VERSION ""

NS_ :

BS_:

BU_: FBD_HL IPB_App1 FBD_HM FBD_HR FBD_Miko FBD_MM FBD_Trunk FBD_VL FBD_VM FBD_VR Diagnosetool_CAN_FD_IPB_41

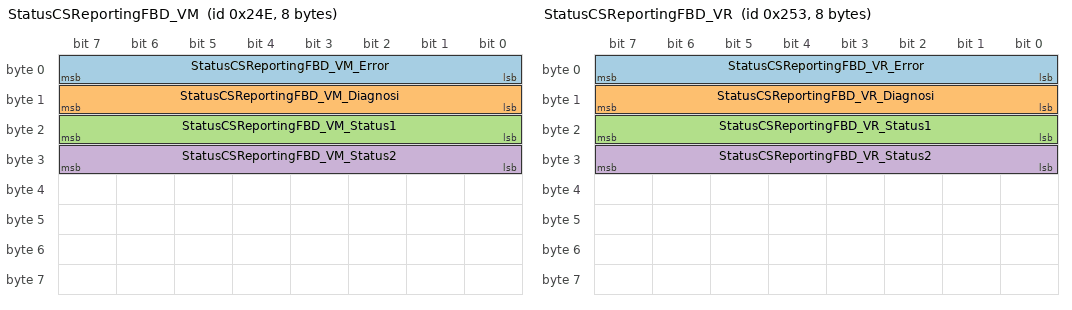
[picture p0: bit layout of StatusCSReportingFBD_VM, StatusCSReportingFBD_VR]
BO_ 590 StatusCSReportingFBD_VM: 8 FBD_VM
 SG_ StatusCSReportingFBD_VM_Error : 0|8@1+ (1,0) [0|0] "" IPB_App1
 SG_ StatusCSReportingFBD_VM_Diagnosi : 8|8@1+ (1.0,0) [0|252] "" IPB_App1
 SG_ StatusCSReportingFBD_VM_Status1 : 16|8@1+ (1.0,0) [0|252] "" IPB_App1
 SG_ StatusCSReportingFBD_VM_Status2 : 24|8@1+ (1.0,0) [0|252] "" IPB_App1

BO_ 595 StatusCSReportingFBD_VR: 8 FBD_VR
 SG_ StatusCSReportingFBD_VR_Error : 0|8@1+ (1,0) [0|0] "" IPB_App1
 SG_ StatusCSReportingFBD_VR_Diagnosi : 8|8@1+ (1.0,0) [0|252] "" IPB_App1
 SG_ StatusCSReportingFBD_VR_Status1 : 16|8@1+ (1.0,0) [0|252] "" IPB_App1
 SG_ StatusCSReportingFBD_VR_Status2 : 24|8@1+ (1.0,0) [0|252] "" IPB_App1

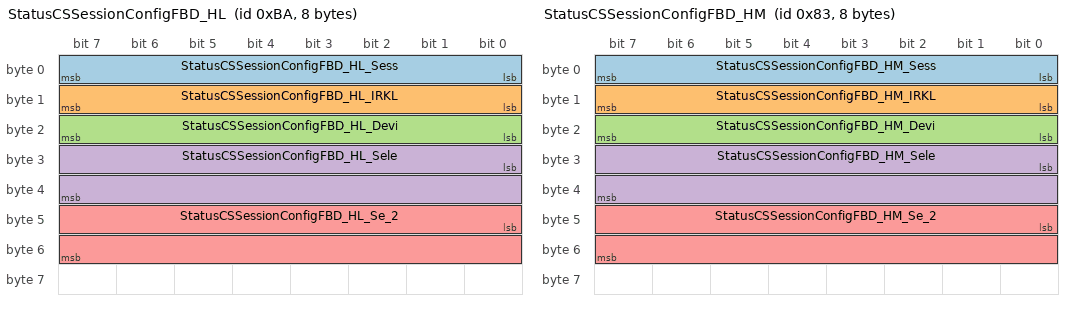
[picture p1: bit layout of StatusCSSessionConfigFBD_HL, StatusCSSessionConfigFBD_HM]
BO_ 186 StatusCSSessionConfigFBD_HL: 8 FBD_HL
 SG_ StatusCSSessionConfigFBD_HL_Sess : 0|8@1+ (1.0,0) [0|252] "" IPB_App1
 SG_ StatusCSSessionConfigFBD_HL_IRKL : 8|8@1+ (1.0,0) [0|252] "" IPB_App1
 SG_ StatusCSSessionConfigFBD_HL_Devi : 16|8@1+ (1.0,0) [0|252] "" IPB_App1
 SG_ StatusCSSessionConfigFBD_HL_Sele : 24|16@1+ (0.625,0) [0|40900] "ms" IPB_App1
 SG_ StatusCSSessionConfigFBD_HL_Se_2 : 40|16@1+ (1.0,0) [0|65532] "" IPB_App1

BO_ 131 StatusCSSessionConfigFBD_HM: 8 FBD_HM
 SG_ StatusCSSessionConfigFBD_HM_Sess : 0|8@1+ (1.0,0) [0|252] "" IPB_App1
 SG_ StatusCSSessionConfigFBD_HM_IRKL : 8|8@1+ (1.0,0) [0|252] "" IPB_App1
 SG_ StatusCSSessionConfigFBD_HM_Devi : 16|8@1+ (1.0,0) [0|252] "" IPB_App1
 SG_ StatusCSSessionConfigFBD_HM_Sele : 24|16@1+ (0.625,0) [0|40900] "ms" IPB_App1
 SG_ StatusCSSessionConfigFBD_HM_Se_2 : 40|16@1+ (1.0,0) [0|65532] "" IPB_App1

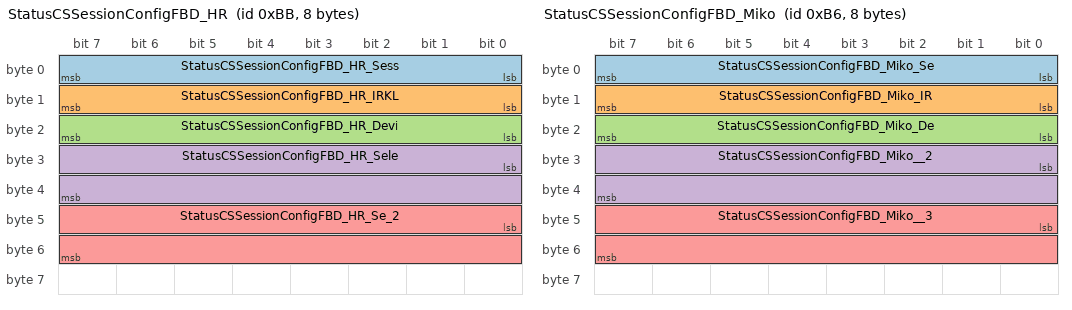
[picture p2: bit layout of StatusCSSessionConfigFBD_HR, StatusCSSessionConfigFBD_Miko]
BO_ 187 StatusCSSessionConfigFBD_HR: 8 FBD_HR
 SG_ StatusCSSessionConfigFBD_HR_Sess : 0|8@1+ (1.0,0) [0|252] "" IPB_App1
 SG_ StatusCSSessionConfigFBD_HR_IRKL : 8|8@1+ (1.0,0) [0|252] "" IPB_App1
 SG_ StatusCSSessionConfigFBD_HR_Devi : 16|8@1+ (1.0,0) [0|252] "" IPB_App1
 SG_ StatusCSSessionConfigFBD_HR_Sele : 24|16@1+ (0.625,0) [0|40900] "ms" IPB_App1
 SG_ StatusCSSessionConfigFBD_HR_Se_2 : 40|16@1+ (1.0,0) [0|65532] "" IPB_App1

BO_ 182 StatusCSSessionConfigFBD_Miko: 8 FBD_Miko
 SG_ StatusCSSessionConfigFBD_Miko_Se : 0|8@1+ (1.0,0) [0|252] "" IPB_App1
 SG_ StatusCSSessionConfigFBD_Miko_IR : 8|8@1+ (1.0,0) [0|252] "" IPB_App1
 SG_ StatusCSSessionConfigFBD_Miko_De : 16|8@1+ (1.0,0) [0|252] "" IPB_App1
 SG_ StatusCSSessionConfigFBD_Miko__2 : 24|16@1+ (0.625,0) [0|40900] "ms" IPB_App1
 SG_ StatusCSSessionConfigFBD_Miko__3 : 40|16@1+ (1.0,0) [0|65532] "" IPB_App1

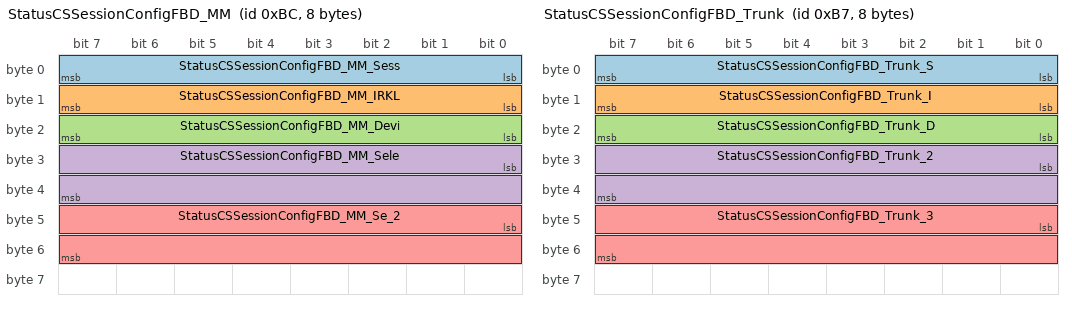
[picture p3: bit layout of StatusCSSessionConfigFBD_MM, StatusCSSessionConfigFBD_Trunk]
BO_ 188 StatusCSSessionConfigFBD_MM: 8 FBD_MM
 SG_ StatusCSSessionConfigFBD_MM_Sess : 0|8@1+ (1.0,0) [0|252] "" IPB_App1
 SG_ StatusCSSessionConfigFBD_MM_IRKL : 8|8@1+ (1.0,0) [0|252] "" IPB_App1
 SG_ StatusCSSessionConfigFBD_MM_Devi : 16|8@1+ (1.0,0) [0|252] "" IPB_App1
 SG_ StatusCSSessionConfigFBD_MM_Sele : 24|16@1+ (0.625,0) [0|40900] "ms" IPB_App1
 SG_ StatusCSSessionConfigFBD_MM_Se_2 : 40|16@1+ (1.0,0) [0|65532] "" IPB_App1

BO_ 183 StatusCSSessionConfigFBD_Trunk: 8 FBD_Trunk
 SG_ StatusCSSessionConfigFBD_Trunk_S : 0|8@1+ (1.0,0) [0|252] "" IPB_App1
 SG_ StatusCSSessionConfigFBD_Trunk_I : 8|8@1+ (1.0,0) [0|252] "" IPB_App1
 SG_ StatusCSSessionConfigFBD_Trunk_D : 16|8@1+ (1.0,0) [0|252] "" IPB_App1
 SG_ StatusCSSessionConfigFBD_Trunk_2 : 24|16@1+ (0.625,0) [0|40900] "ms" IPB_App1
 SG_ StatusCSSessionConfigFBD_Trunk_3 : 40|16@1+ (1.0,0) [0|65532] "" IPB_App1

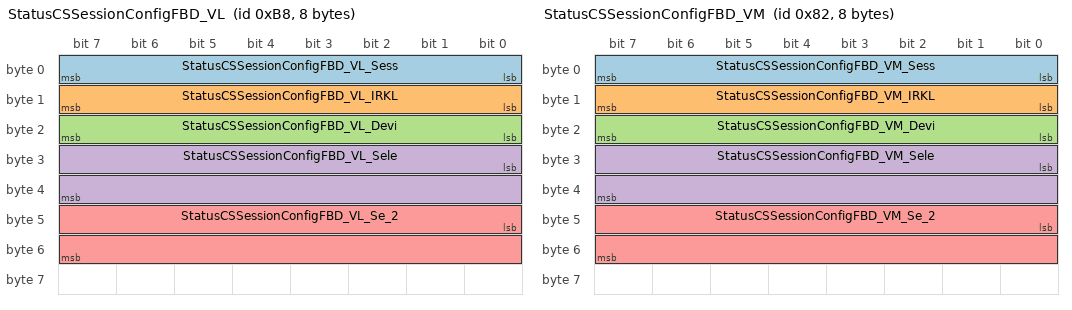
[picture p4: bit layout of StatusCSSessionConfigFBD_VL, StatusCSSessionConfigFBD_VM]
BO_ 184 StatusCSSessionConfigFBD_VL: 8 FBD_VL
 SG_ StatusCSSessionConfigFBD_VL_Sess : 0|8@1+ (1.0,0) [0|252] "" IPB_App1
 SG_ StatusCSSessionConfigFBD_VL_IRKL : 8|8@1+ (1.0,0) [0|252] "" IPB_App1
 SG_ StatusCSSessionConfigFBD_VL_Devi : 16|8@1+ (1.0,0) [0|252] "" IPB_App1
 SG_ StatusCSSessionConfigFBD_VL_Sele : 24|16@1+ (0.625,0) [0|40900] "ms" IPB_App1
 SG_ StatusCSSessionConfigFBD_VL_Se_2 : 40|16@1+ (1.0,0) [0|65532] "" IPB_App1

BO_ 130 StatusCSSessionConfigFBD_VM: 8 FBD_VM
 SG_ StatusCSSessionConfigFBD_VM_Sess : 0|8@1+ (1.0,0) [0|252] "" IPB_App1
 SG_ StatusCSSessionConfigFBD_VM_IRKL : 8|8@1+ (1.0,0) [0|252] "" IPB_App1
 SG_ StatusCSSessionConfigFBD_VM_Devi : 16|8@1+ (1.0,0) [0|252] "" IPB_App1
 SG_ StatusCSSessionConfigFBD_VM_Sele : 24|16@1+ (0.625,0) [0|40900] "ms" IPB_App1
 SG_ StatusCSSessionConfigFBD_VM_Se_2 : 40|16@1+ (1.0,0) [0|65532] "" IPB_App1

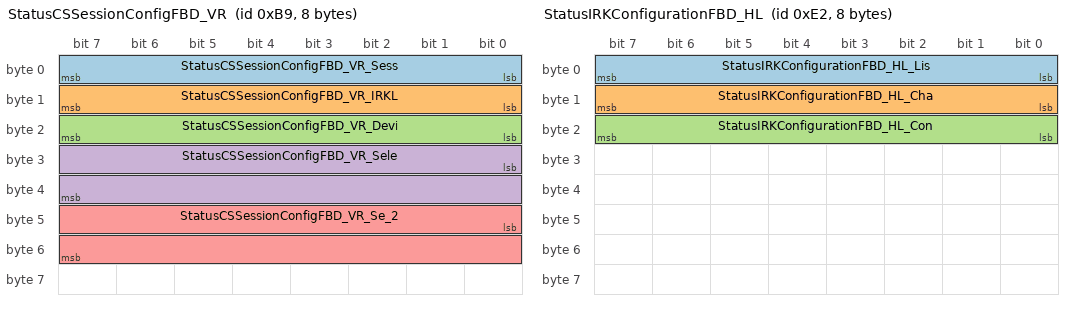
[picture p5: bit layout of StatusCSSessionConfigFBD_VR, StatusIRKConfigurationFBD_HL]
BO_ 185 StatusCSSessionConfigFBD_VR: 8 FBD_VR
 SG_ StatusCSSessionConfigFBD_VR_Sess : 0|8@1+ (1.0,0) [0|252] "" IPB_App1
 SG_ StatusCSSessionConfigFBD_VR_IRKL : 8|8@1+ (1.0,0) [0|252] "" IPB_App1
 SG_ StatusCSSessionConfigFBD_VR_Devi : 16|8@1+ (1.0,0) [0|252] "" IPB_App1
 SG_ StatusCSSessionConfigFBD_VR_Sele : 24|16@1+ (0.625,0) [0|40900] "ms" IPB_App1
 SG_ StatusCSSessionConfigFBD_VR_Se_2 : 40|16@1+ (1.0,0) [0|65532] "" IPB_App1

BO_ 646 StatusDiagnosticFBD_HL: 32 FBD_HL
 SG_ StatusDiagnosticFBD_HL_BMWPartNu : 0|8@1+ (1.0,0) [0|255] "" IPB_App1
 SG_ StatusDiagnosticFBD_HL_BMWPart_2 : 8|8@1+ (1.0,0) [0|255] "" IPB_App1
 SG_ StatusDiagnosticFBD_HL_BMWPart_3 : 16|8@1+ (1.0,0) [0|255] "" IPB_App1
 SG_ StatusDiagnosticFBD_HL_BMWPart_4 : 24|8@1+ (1.0,0) [0|255] "" IPB_App1
 SG_ StatusDiagnosticFBD_HL_BMWPart_5 : 32|8@1+ (1.0,0) [0|255] "" IPB_App1
 SG_ StatusDiagnosticFBD_HL_BMWPart_6 : 40|8@1+ (1.0,0) [0|255] "" IPB_App1
 SG_ StatusDiagnosticFBD_HL_BMWPart_7 : 48|8@1+ (1.0,0) [0|255] "" IPB_App1
 SG_ StatusDiagnosticFBD_HL_BMWPart_8 : 56|8@1+ (1.0,0) [0|255] "" IPB_App1
 SG_ StatusDiagnosticFBD_HL_HWELMain : 64|8@1+ (1.0,0) [0|252] "" IPB_App1
 SG_ StatusDiagnosticFBD_HL_HWELMinor : 72|8@1+ (1.0,0) [0|252] "" IPB_App1
 SG_ StatusDiagnosticFBD_HL_HWELPatch : 80|8@1+ (1.0,0) [0|252] "" IPB_App1
 SG_ StatusDiagnosticFBD_HL_BLESWFKMa : 88|8@1+ (1.0,0) [0|252] "" IPB_App1
 SG_ StatusDiagnosticFBD_HL_BLESWFKMi : 96|8@1+ (1.0,0) [0|252] "" IPB_App1
 SG_ StatusDiagnosticFBD_HL_BLESWFKPa : 104|8@1+ (1.0,0) [0|252] "" IPB_App1
 SG_ StatusDiagnosticFBD_HL_UWBSWFKMa : 112|8@1+ (1.0,0) [0|252] "" IPB_App1
 SG_ StatusDiagnosticFBD_HL_UWBSWFKMi : 120|8@1+ (1.0,0) [0|252] "" IPB_App1
 SG_ StatusDiagnosticFBD_HL_UWBSWFKPa : 128|8@1+ (1.0,0) [0|252] "" IPB_App1
 SG_ StatusDiagnosticFBD_HL_Bootloade : 136|8@1+ (1.0,0) [0|252] "" IPB_App1
 SG_ StatusDiagnosticFBD_HL_Bootloa_2 : 144|8@1+ (1.0,0) [0|252] "" IPB_App1
 SG_ StatusDiagnosticFBD_HL_Bootloa_3 : 152|8@1+ (1.0,0) [0|252] "" IPB_App1
 SG_ StatusDiagnosticFBD_HL_Productio : 160|64@1+ (1.0,0) [0|18446744073709551612] "" IPB_App1
 SG_ StatusDiagnosticFBD_HL_SerialNum : 224|32@1+ (1.0,0) [0|4294967292] "" IPB_App1

BO_ 641 StatusDiagnosticFBD_HM: 32 FBD_HM
 SG_ StatusDiagnosticFBD_HM_BMWPartNu : 0|8@1+ (1.0,0) [0|255] "" IPB_App1
 SG_ StatusDiagnosticFBD_HM_BMWPart_2 : 8|8@1+ (1.0,0) [0|255] "" IPB_App1
 SG_ StatusDiagnosticFBD_HM_BMWPart_3 : 16|8@1+ (1.0,0) [0|255] "" IPB_App1
 SG_ StatusDiagnosticFBD_HM_BMWPart_4 : 24|8@1+ (1.0,0) [0|255] "" IPB_App1
 SG_ StatusDiagnosticFBD_HM_BMWPart_5 : 32|8@1+ (1.0,0) [0|255] "" IPB_App1
 SG_ StatusDiagnosticFBD_HM_BMWPart_6 : 40|8@1+ (1.0,0) [0|255] "" IPB_App1
 SG_ StatusDiagnosticFBD_HM_BMWPart_7 : 48|8@1+ (1.0,0) [0|255] "" IPB_App1
 SG_ StatusDiagnosticFBD_HM_BMWPart_8 : 56|8@1+ (1.0,0) [0|255] "" IPB_App1
 SG_ StatusDiagnosticFBD_HM_HWELMain : 64|8@1+ (1.0,0) [0|252] "" IPB_App1
 SG_ StatusDiagnosticFBD_HM_HWELMinor : 72|8@1+ (1.0,0) [0|252] "" IPB_App1
 SG_ StatusDiagnosticFBD_HM_HWELPatch : 80|8@1+ (1.0,0) [0|252] "" IPB_App1
 SG_ StatusDiagnosticFBD_HM_BLESWFKMa : 88|8@1+ (1.0,0) [0|252] "" IPB_App1
 SG_ StatusDiagnosticFBD_HM_BLESWFKMi : 96|8@1+ (1.0,0) [0|252] "" IPB_App1
 SG_ StatusDiagnosticFBD_HM_BLESWFKPa : 104|8@1+ (1.0,0) [0|252] "" IPB_App1
 SG_ StatusDiagnosticFBD_HM_UWBSWFKMa : 112|8@1+ (1.0,0) [0|252] "" IPB_App1
 SG_ StatusDiagnosticFBD_HM_UWBSWFKMi : 120|8@1+ (1.0,0) [0|252] "" IPB_App1
 SG_ StatusDiagnosticFBD_HM_UWBSWFKPa : 128|8@1+ (1.0,0) [0|252] "" IPB_App1
 SG_ StatusDiagnosticFBD_HM_Bootloade : 136|8@1+ (1.0,0) [0|252] "" IPB_App1
 SG_ StatusDiagnosticFBD_HM_Bootloa_2 : 144|8@1+ (1.0,0) [0|252] "" IPB_App1
 SG_ StatusDiagnosticFBD_HM_Bootloa_3 : 152|8@1+ (1.0,0) [0|252] "" IPB_App1
 SG_ StatusDiagnosticFBD_HM_Productio : 160|64@1+ (1.0,0) [0|18446744073709551612] "" IPB_App1
 SG_ StatusDiagnosticFBD_HM_SerialNum : 224|32@1+ (1.0,0) [0|4294967292] "" IPB_App1

BO_ 647 StatusDiagnosticFBD_HR: 32 FBD_HR
 SG_ StatusDiagnosticFBD_HR_BMWPartNu : 0|8@1+ (1.0,0) [0|255] "" IPB_App1
 SG_ StatusDiagnosticFBD_HR_BMWPart_2 : 8|8@1+ (1.0,0) [0|255] "" IPB_App1
 SG_ StatusDiagnosticFBD_HR_BMWPart_3 : 16|8@1+ (1.0,0) [0|255] "" IPB_App1
 SG_ StatusDiagnosticFBD_HR_BMWPart_4 : 24|8@1+ (1.0,0) [0|255] "" IPB_App1
 SG_ StatusDiagnosticFBD_HR_BMWPart_5 : 32|8@1+ (1.0,0) [0|255] "" IPB_App1
 SG_ StatusDiagnosticFBD_HR_BMWPart_6 : 40|8@1+ (1.0,0) [0|255] "" IPB_App1
 SG_ StatusDiagnosticFBD_HR_BMWPart_7 : 48|8@1+ (1.0,0) [0|255] "" IPB_App1
 SG_ StatusDiagnosticFBD_HR_BMWPart_8 : 56|8@1+ (1.0,0) [0|255] "" IPB_App1
 SG_ StatusDiagnosticFBD_HR_HWELMain : 64|8@1+ (1.0,0) [0|252] "" IPB_App1
 SG_ StatusDiagnosticFBD_HR_HWELMinor : 72|8@1+ (1.0,0) [0|252] "" IPB_App1
 SG_ StatusDiagnosticFBD_HR_HWELPatch : 80|8@1+ (1.0,0) [0|252] "" IPB_App1
 SG_ StatusDiagnosticFBD_HR_BLESWFKMa : 88|8@1+ (1.0,0) [0|252] "" IPB_App1
 SG_ StatusDiagnosticFBD_HR_BLESWFKMi : 96|8@1+ (1.0,0) [0|252] "" IPB_App1
 SG_ StatusDiagnosticFBD_HR_BLESWFKPa : 104|8@1+ (1.0,0) [0|252] "" IPB_App1
 SG_ StatusDiagnosticFBD_HR_UWBSWFKMa : 112|8@1+ (1.0,0) [0|252] "" IPB_App1
 SG_ StatusDiagnosticFBD_HR_UWBSWFKMi : 120|8@1+ (1.0,0) [0|252] "" IPB_App1
 SG_ StatusDiagnosticFBD_HR_UWBSWFKPa : 128|8@1+ (1.0,0) [0|252] "" IPB_App1
 SG_ StatusDiagnosticFBD_HR_Bootloade : 136|8@1+ (1.0,0) [0|252] "" IPB_App1
 SG_ StatusDiagnosticFBD_HR_Bootloa_2 : 144|8@1+ (1.0,0) [0|252] "" IPB_App1
 SG_ StatusDiagnosticFBD_HR_Bootloa_3 : 152|8@1+ (1.0,0) [0|252] "" IPB_App1
 SG_ StatusDiagnosticFBD_HR_Productio : 160|64@1+ (1.0,0) [0|18446744073709551612] "" IPB_App1
 SG_ StatusDiagnosticFBD_HR_SerialNum : 224|32@1+ (1.0,0) [0|4294967292] "" IPB_App1

BO_ 642 StatusDiagnosticFBD_Miko: 32 FBD_Miko
 SG_ StatusDiagnosticFBD_Miko_BMWPart : 0|8@1+ (1.0,0) [0|255] "" IPB_App1
 SG_ StatusDiagnosticFBD_Miko_BMWPa_2 : 8|8@1+ (1.0,0) [0|255] "" IPB_App1
 SG_ StatusDiagnosticFBD_Miko_BMWPa_3 : 16|8@1+ (1.0,0) [0|255] "" IPB_App1
 SG_ StatusDiagnosticFBD_Miko_BMWPa_4 : 24|8@1+ (1.0,0) [0|255] "" IPB_App1
 SG_ StatusDiagnosticFBD_Miko_BMWPa_5 : 32|8@1+ (1.0,0) [0|255] "" IPB_App1
 SG_ StatusDiagnosticFBD_Miko_BMWPa_6 : 40|8@1+ (1.0,0) [0|255] "" IPB_App1
 SG_ StatusDiagnosticFBD_Miko_BMWPa_7 : 48|8@1+ (1.0,0) [0|255] "" IPB_App1
 SG_ StatusDiagnosticFBD_Miko_BMWPa_8 : 56|8@1+ (1.0,0) [0|255] "" IPB_App1
 SG_ StatusDiagnosticFBD_Miko_HWELMai : 64|8@1+ (1.0,0) [0|252] "" IPB_App1
 SG_ StatusDiagnosticFBD_Miko_HWELMin : 72|8@1+ (1.0,0) [0|252] "" IPB_App1
 SG_ StatusDiagnosticFBD_Miko_HWELPat : 80|8@1+ (1.0,0) [0|252] "" IPB_App1
 SG_ StatusDiagnosticFBD_Miko_BLESWFK : 88|8@1+ (1.0,0) [0|252] "" IPB_App1
 SG_ StatusDiagnosticFBD_Miko_BLESW_2 : 96|8@1+ (1.0,0) [0|252] "" IPB_App1
 SG_ StatusDiagnosticFBD_Miko_BLESW_3 : 104|8@1+ (1.0,0) [0|252] "" IPB_App1
 SG_ StatusDiagnosticFBD_Miko_UWBSWFK : 112|8@1+ (1.0,0) [0|252] "" IPB_App1
 SG_ StatusDiagnosticFBD_Miko_UWBSW_2 : 120|8@1+ (1.0,0) [0|252] "" IPB_App1
 SG_ StatusDiagnosticFBD_Miko_UWBSW_3 : 128|8@1+ (1.0,0) [0|252] "" IPB_App1
 SG_ StatusDiagnosticFBD_Miko_Bootloa : 136|8@1+ (1.0,0) [0|252] "" IPB_App1
 SG_ StatusDiagnosticFBD_Miko_Bootl_2 : 144|8@1+ (1.0,0) [0|252] "" IPB_App1
 SG_ StatusDiagnosticFBD_Miko_Bootl_3 : 152|8@1+ (1.0,0) [0|252] "" IPB_App1
 SG_ StatusDiagnosticFBD_Miko_Product : 160|64@1+ (1.0,0) [0|18446744073709551612] "" IPB_App1
 SG_ StatusDiagnosticFBD_Miko_SerialN : 224|32@1+ (1.0,0) [0|4294967292] "" IPB_App1

BO_ 864 StatusDiagnosticFBD_MM: 32 FBD_MM
 SG_ StatusDiagnosticFBD_MM_BMWPartNu : 0|8@1+ (1.0,0) [0|255] "" IPB_App1
 SG_ StatusDiagnosticFBD_MM_BMWPart_2 : 8|8@1+ (1.0,0) [0|255] "" IPB_App1
 SG_ StatusDiagnosticFBD_MM_BMWPart_3 : 16|8@1+ (1.0,0) [0|255] "" IPB_App1
 SG_ StatusDiagnosticFBD_MM_BMWPart_4 : 24|8@1+ (1.0,0) [0|255] "" IPB_App1
 SG_ StatusDiagnosticFBD_MM_BMWPart_5 : 32|8@1+ (1.0,0) [0|255] "" IPB_App1
 SG_ StatusDiagnosticFBD_MM_BMWPart_6 : 40|8@1+ (1.0,0) [0|255] "" IPB_App1
 SG_ StatusDiagnosticFBD_MM_BMWPart_7 : 48|8@1+ (1.0,0) [0|255] "" IPB_App1
 SG_ StatusDiagnosticFBD_MM_BMWPart_8 : 56|8@1+ (1.0,0) [0|255] "" IPB_App1
 SG_ StatusDiagnosticFBD_MM_HWELMain : 64|8@1+ (1.0,0) [0|252] "" IPB_App1
 SG_ StatusDiagnosticFBD_MM_HWELMinor : 72|8@1+ (1.0,0) [0|252] "" IPB_App1
 SG_ StatusDiagnosticFBD_MM_HWELPatch : 80|8@1+ (1.0,0) [0|252] "" IPB_App1
 SG_ StatusDiagnosticFBD_MM_BLESWFKMa : 88|8@1+ (1.0,0) [0|252] "" IPB_App1
 SG_ StatusDiagnosticFBD_MM_BLESWFKMi : 96|8@1+ (1.0,0) [0|252] "" IPB_App1
 SG_ StatusDiagnosticFBD_MM_BLESWFKPa : 104|8@1+ (1.0,0) [0|252] "" IPB_App1
 SG_ StatusDiagnosticFBD_MM_UWBSWFKMa : 112|8@1+ (1.0,0) [0|252] "" IPB_App1
 SG_ StatusDiagnosticFBD_MM_UWBSWFKMi : 120|8@1+ (1.0,0) [0|252] "" IPB_App1
 SG_ StatusDiagnosticFBD_MM_UWBSWFKPa : 128|8@1+ (1.0,0) [0|252] "" IPB_App1
 SG_ StatusDiagnosticFBD_MM_Bootloade : 136|8@1+ (1.0,0) [0|252] "" IPB_App1
 SG_ StatusDiagnosticFBD_MM_Bootloa_2 : 144|8@1+ (1.0,0) [0|252] "" IPB_App1
 SG_ StatusDiagnosticFBD_MM_Bootloa_3 : 152|8@1+ (1.0,0) [0|252] "" IPB_App1
 SG_ StatusDiagnosticFBD_MM_Productio : 160|64@1+ (1.0,0) [0|18446744073709551612] "" IPB_App1
 SG_ StatusDiagnosticFBD_MM_SerialNum : 224|32@1+ (1.0,0) [0|4294967292] "" IPB_App1

BO_ 643 StatusDiagnosticFBD_Trunk: 32 FBD_Trunk
 SG_ StatusDiagnosticFBD_Trunk_BMWPar : 0|8@1+ (1.0,0) [0|255] "" IPB_App1
 SG_ StatusDiagnosticFBD_Trunk_BMWP_2 : 8|8@1+ (1.0,0) [0|255] "" IPB_App1
 SG_ StatusDiagnosticFBD_Trunk_BMWP_3 : 16|8@1+ (1.0,0) [0|255] "" IPB_App1
 SG_ StatusDiagnosticFBD_Trunk_BMWP_4 : 24|8@1+ (1.0,0) [0|255] "" IPB_App1
 SG_ StatusDiagnosticFBD_Trunk_BMWP_5 : 32|8@1+ (1.0,0) [0|255] "" IPB_App1
 SG_ StatusDiagnosticFBD_Trunk_BMWP_6 : 40|8@1+ (1.0,0) [0|255] "" IPB_App1
 SG_ StatusDiagnosticFBD_Trunk_BMWP_7 : 48|8@1+ (1.0,0) [0|255] "" IPB_App1
 SG_ StatusDiagnosticFBD_Trunk_BMWP_8 : 56|8@1+ (1.0,0) [0|255] "" IPB_App1
 SG_ StatusDiagnosticFBD_Trunk_HWELMa : 64|8@1+ (1.0,0) [0|252] "" IPB_App1
 SG_ StatusDiagnosticFBD_Trunk_HWELMi : 72|8@1+ (1.0,0) [0|252] "" IPB_App1
 SG_ StatusDiagnosticFBD_Trunk_HWELPa : 80|8@1+ (1.0,0) [0|252] "" IPB_App1
 SG_ StatusDiagnosticFBD_Trunk_BLESWF : 88|8@1+ (1.0,0) [0|252] "" IPB_App1
 SG_ StatusDiagnosticFBD_Trunk_BLES_2 : 96|8@1+ (1.0,0) [0|252] "" IPB_App1
 SG_ StatusDiagnosticFBD_Trunk_BLES_3 : 104|8@1+ (1.0,0) [0|252] "" IPB_App1
 SG_ StatusDiagnosticFBD_Trunk_UWBSWF : 112|8@1+ (1.0,0) [0|252] "" IPB_App1
 SG_ StatusDiagnosticFBD_Trunk_UWBS_2 : 120|8@1+ (1.0,0) [0|252] "" IPB_App1
 SG_ StatusDiagnosticFBD_Trunk_UWBS_3 : 128|8@1+ (1.0,0) [0|252] "" IPB_App1
 SG_ StatusDiagnosticFBD_Trunk_Bootlo : 136|8@1+ (1.0,0) [0|252] "" IPB_App1
 SG_ StatusDiagnosticFBD_Trunk_Boot_2 : 144|8@1+ (1.0,0) [0|252] "" IPB_App1
 SG_ StatusDiagnosticFBD_Trunk_Boot_3 : 152|8@1+ (1.0,0) [0|252] "" IPB_App1
 SG_ StatusDiagnosticFBD_Trunk_Produc : 160|64@1+ (1.0,0) [0|18446744073709551612] "" IPB_App1
 SG_ StatusDiagnosticFBD_Trunk_Serial : 224|32@1+ (1.0,0) [0|4294967292] "" IPB_App1

BO_ 644 StatusDiagnosticFBD_VL: 32 FBD_VL
 SG_ StatusDiagnosticFBD_VL_BMWPartNu : 0|8@1+ (1.0,0) [0|255] "" IPB_App1
 SG_ StatusDiagnosticFBD_VL_BMWPart_2 : 8|8@1+ (1.0,0) [0|255] "" IPB_App1
 SG_ StatusDiagnosticFBD_VL_BMWPart_3 : 16|8@1+ (1.0,0) [0|255] "" IPB_App1
 SG_ StatusDiagnosticFBD_VL_BMWPart_4 : 24|8@1+ (1.0,0) [0|255] "" IPB_App1
 SG_ StatusDiagnosticFBD_VL_BMWPart_5 : 32|8@1+ (1.0,0) [0|255] "" IPB_App1
 SG_ StatusDiagnosticFBD_VL_BMWPart_6 : 40|8@1+ (1.0,0) [0|255] "" IPB_App1
 SG_ StatusDiagnosticFBD_VL_BMWPart_7 : 48|8@1+ (1.0,0) [0|255] "" IPB_App1
 SG_ StatusDiagnosticFBD_VL_BMWPart_8 : 56|8@1+ (1.0,0) [0|255] "" IPB_App1
 SG_ StatusDiagnosticFBD_VL_HWELMain : 64|8@1+ (1.0,0) [0|252] "" IPB_App1
 SG_ StatusDiagnosticFBD_VL_HWELMinor : 72|8@1+ (1.0,0) [0|252] "" IPB_App1
 SG_ StatusDiagnosticFBD_VL_HWELPatch : 80|8@1+ (1.0,0) [0|252] "" IPB_App1
 SG_ StatusDiagnosticFBD_VL_BLESWFKMa : 88|8@1+ (1.0,0) [0|252] "" IPB_App1
 SG_ StatusDiagnosticFBD_VL_BLESWFKMi : 96|8@1+ (1.0,0) [0|252] "" IPB_App1
 SG_ StatusDiagnosticFBD_VL_BLESWFKPa : 104|8@1+ (1.0,0) [0|252] "" IPB_App1
 SG_ StatusDiagnosticFBD_VL_UWBSWFKMa : 112|8@1+ (1.0,0) [0|252] "" IPB_App1
 SG_ StatusDiagnosticFBD_VL_UWBSWFKMi : 120|8@1+ (1.0,0) [0|252] "" IPB_App1
 SG_ StatusDiagnosticFBD_VL_UWBSWFKPa : 128|8@1+ (1.0,0) [0|252] "" IPB_App1
 SG_ StatusDiagnosticFBD_VL_Bootloade : 136|8@1+ (1.0,0) [0|252] "" IPB_App1
 SG_ StatusDiagnosticFBD_VL_Bootloa_2 : 144|8@1+ (1.0,0) [0|252] "" IPB_App1
 SG_ StatusDiagnosticFBD_VL_Bootloa_3 : 152|8@1+ (1.0,0) [0|252] "" IPB_App1
 SG_ StatusDiagnosticFBD_VL_Productio : 160|64@1+ (1.0,0) [0|18446744073709551612] "" IPB_App1
 SG_ StatusDiagnosticFBD_VL_SerialNum : 224|32@1+ (1.0,0) [0|4294967292] "" IPB_App1

BO_ 640 StatusDiagnosticFBD_VM: 32 FBD_VM
 SG_ StatusDiagnosticFBD_VM_BMWPartNu : 0|8@1+ (1.0,0) [0|255] "" IPB_App1
 SG_ StatusDiagnosticFBD_VM_BMWPart_2 : 8|8@1+ (1.0,0) [0|255] "" IPB_App1
 SG_ StatusDiagnosticFBD_VM_BMWPart_3 : 16|8@1+ (1.0,0) [0|255] "" IPB_App1
 SG_ StatusDiagnosticFBD_VM_BMWPart_4 : 24|8@1+ (1.0,0) [0|255] "" IPB_App1
 SG_ StatusDiagnosticFBD_VM_BMWPart_5 : 32|8@1+ (1.0,0) [0|255] "" IPB_App1
 SG_ StatusDiagnosticFBD_VM_BMWPart_6 : 40|8@1+ (1.0,0) [0|255] "" IPB_App1
 SG_ StatusDiagnosticFBD_VM_BMWPart_7 : 48|8@1+ (1.0,0) [0|255] "" IPB_App1
 SG_ StatusDiagnosticFBD_VM_BMWPart_8 : 56|8@1+ (1.0,0) [0|255] "" IPB_App1
 SG_ StatusDiagnosticFBD_VM_HWELMain : 64|8@1+ (1.0,0) [0|252] "" IPB_App1
 SG_ StatusDiagnosticFBD_VM_HWELMinor : 72|8@1+ (1.0,0) [0|252] "" IPB_App1
 SG_ StatusDiagnosticFBD_VM_HWELPatch : 80|8@1+ (1.0,0) [0|252] "" IPB_App1
 SG_ StatusDiagnosticFBD_VM_BLESWFKMa : 88|8@1+ (1.0,0) [0|252] "" IPB_App1
 SG_ StatusDiagnosticFBD_VM_BLESWFKMi : 96|8@1+ (1.0,0) [0|252] "" IPB_App1
 SG_ StatusDiagnosticFBD_VM_BLESWFKPa : 104|8@1+ (1.0,0) [0|252] "" IPB_App1
 SG_ StatusDiagnosticFBD_VM_UWBSWFKMa : 112|8@1+ (1.0,0) [0|252] "" IPB_App1
 SG_ StatusDiagnosticFBD_VM_UWBSWFKMi : 120|8@1+ (1.0,0) [0|252] "" IPB_App1
 SG_ StatusDiagnosticFBD_VM_UWBSWFKPa : 128|8@1+ (1.0,0) [0|252] "" IPB_App1
 SG_ StatusDiagnosticFBD_VM_Bootloade : 136|8@1+ (1.0,0) [0|252] "" IPB_App1
 SG_ StatusDiagnosticFBD_VM_Bootloa_2 : 144|8@1+ (1.0,0) [0|252] "" IPB_App1
 SG_ StatusDiagnosticFBD_VM_Bootloa_3 : 152|8@1+ (1.0,0) [0|252] "" IPB_App1
 SG_ StatusDiagnosticFBD_VM_Productio : 160|64@1+ (1.0,0) [0|18446744073709551612] "" IPB_App1
 SG_ StatusDiagnosticFBD_VM_SerialNum : 224|32@1+ (1.0,0) [0|4294967292] "" IPB_App1

BO_ 645 StatusDiagnosticFBD_VR: 32 FBD_VR
 SG_ StatusDiagnosticFBD_VR_BMWPartNu : 0|8@1+ (1.0,0) [0|255] "" IPB_App1
 SG_ StatusDiagnosticFBD_VR_BMWPart_2 : 8|8@1+ (1.0,0) [0|255] "" IPB_App1
 SG_ StatusDiagnosticFBD_VR_BMWPart_3 : 16|8@1+ (1.0,0) [0|255] "" IPB_App1
 SG_ StatusDiagnosticFBD_VR_BMWPart_4 : 24|8@1+ (1.0,0) [0|255] "" IPB_App1
 SG_ StatusDiagnosticFBD_VR_BMWPart_5 : 32|8@1+ (1.0,0) [0|255] "" IPB_App1
 SG_ StatusDiagnosticFBD_VR_BMWPart_6 : 40|8@1+ (1.0,0) [0|255] "" IPB_App1
 SG_ StatusDiagnosticFBD_VR_BMWPart_7 : 48|8@1+ (1.0,0) [0|255] "" IPB_App1
 SG_ StatusDiagnosticFBD_VR_BMWPart_8 : 56|8@1+ (1.0,0) [0|255] "" IPB_App1
 SG_ StatusDiagnosticFBD_VR_HWELMain : 64|8@1+ (1.0,0) [0|252] "" IPB_App1
 SG_ StatusDiagnosticFBD_VR_HWELMinor : 72|8@1+ (1.0,0) [0|252] "" IPB_App1
 SG_ StatusDiagnosticFBD_VR_HWELPatch : 80|8@1+ (1.0,0) [0|252] "" IPB_App1
 SG_ StatusDiagnosticFBD_VR_BLESWFKMa : 88|8@1+ (1.0,0) [0|252] "" IPB_App1
 SG_ StatusDiagnosticFBD_VR_BLESWFKMi : 96|8@1+ (1.0,0) [0|252] "" IPB_App1
 SG_ StatusDiagnosticFBD_VR_BLESWFKPa : 104|8@1+ (1.0,0) [0|252] "" IPB_App1
 SG_ StatusDiagnosticFBD_VR_UWBSWFKMa : 112|8@1+ (1.0,0) [0|252] "" IPB_App1
 SG_ StatusDiagnosticFBD_VR_UWBSWFKMi : 120|8@1+ (1.0,0) [0|252] "" IPB_App1
 SG_ StatusDiagnosticFBD_VR_UWBSWFKPa : 128|8@1+ (1.0,0) [0|252] "" IPB_App1
 SG_ StatusDiagnosticFBD_VR_Bootloade : 136|8@1+ (1.0,0) [0|252] "" IPB_App1
 SG_ StatusDiagnosticFBD_VR_Bootloa_2 : 144|8@1+ (1.0,0) [0|252] "" IPB_App1
 SG_ StatusDiagnosticFBD_VR_Bootloa_3 : 152|8@1+ (1.0,0) [0|252] "" IPB_App1
 SG_ StatusDiagnosticFBD_VR_Productio : 160|64@1+ (1.0,0) [0|18446744073709551612] "" IPB_App1
 SG_ StatusDiagnosticFBD_VR_SerialNum : 224|32@1+ (1.0,0) [0|4294967292] "" IPB_App1

BO_ 156 StatusFBD_HL: 32 FBD_HL
 SG_ StatusFBD_HL_PowerMode : 0|8@1+ (1,0) [0|0] "" IPB_App1
 SG_ StatusFBD_HL_ResetState : 8|8@1+ (1.0,0) [0|252] "" IPB_App1
 SG_ StatusFBD_HL_ResetReason : 16|8@1+ (1.0,0) [0|252] "" IPB_App1
 SG_ StatusFBD_HL_BLEStatus : 24|8@1+ (1,0) [0|0] "" IPB_App1
 SG_ StatusFBD_HL_UWBStatus : 32|8@1+ (1,0) [0|0] "" IPB_App1
 SG_ StatusFBD_HL_WakeUpReason : 40|8@1+ (1,0) [0|0] "" IPB_App1
 SG_ StatusFBD_HL_IRKListIndexWakeUpT : 48|8@1+ (1.0,0) [0|252] "" IPB_App1
 SG_ StatusFBD_HL_Temperature : 56|8@1+ (1.0,-100) [-100|150] "°C" IPB_App1
 SG_ StatusFBD_HL_BLENumberOfBonding : 64|8@1+ (1.0,0) [0|252] "" IPB_App1
 SG_ StatusFBD_HL_BLENumberActiveConn : 72|8@1+ (1.0,0) [0|252] "" IPB_App1
 SG_ StatusFBD_HL_BLEChipPowerOnReset : 80|8@1+ (1.0,0) [0|252] "" IPB_App1
 SG_ StatusFBD_HL_BLEChipSWResetCount : 88|8@1+ (1.0,0) [0|252] "" IPB_App1
 SG_ StatusFBD_HL_BLEChipWatchdogCoun : 96|8@1+ (1.0,0) [0|252] "" IPB_App1
 SG_ StatusFBD_HL_BLEChipTemperatureP : 104|8@1+ (1.0,0) [0|252] "" IPB_App1
 SG_ StatusFBD_HL_BLEChipThermalShutd : 112|8@1+ (1.0,0) [0|252] "" IPB_App1
 SG_ StatusFBD_HL_BLEChipErrorState : 120|8@1+ (1,0) [0|0] "" IPB_App1
 SG_ StatusFBD_HL_UWBChipPowerOnReset : 128|8@1+ (1.0,0) [0|252] "" IPB_App1
 SG_ StatusFBD_HL_UWBChipSWResetCount : 136|8@1+ (1.0,0) [0|252] "" IPB_App1
 SG_ StatusFBD_HL_UWBChipWatchdogCoun : 144|8@1+ (1.0,0) [0|252] "" IPB_App1
 SG_ StatusFBD_HL_UWBChipTemperatureP : 152|8@1+ (1.0,0) [0|252] "" IPB_App1
 SG_ StatusFBD_HL_UWBChipThermalShutd : 160|8@1+ (1.0,0) [0|252] "" IPB_App1
 SG_ StatusFBD_HL_UWBChipErrorState : 168|8@1+ (1,0) [0|0] "" IPB_App1
 SG_ StatusFBD_HL_ProgrammingCounter : 176|8@1+ (1.0,0) [0|252] "" IPB_App1
 SG_ StatusFBD_HL_ProgrammingErrorCou : 184|8@1+ (1.0,0) [0|252] "" IPB_App1
 SG_ StatusFBD_HL_SPIHangupCounter : 192|8@1+ (1.0,0) [0|252] "" IPB_App1
 SG_ StatusFBD_HL_SBCChipTemperatureP : 200|8@1+ (1.0,0) [0|252] "" IPB_App1
 SG_ StatusFBD_HL_SBCChipThermalShutd : 208|8@1+ (1.0,0) [0|252] "" IPB_App1
 SG_ StatusFBD_HL_SBCErrorState : 216|8@1+ (1,0) [0|0] "" IPB_App1
 SG_ StatusFBD_HL_OptionCode : 224|8@1+ (1,0) [0|0] "" IPB_App1
 SG_ StatusFBD_HL_UWBCollisionCounter : 232|8@1+ (1.0,0) [0|252] "" IPB_App1
 SG_ StatusFBD_HL_DebugInformation1 : 240|8@1+ (1,0) [0|0] "" IPB_App1
 SG_ StatusFBD_HL_DebugInformation2 : 248|8@1+ (1,0) [0|0] "" IPB_App1

BO_ 151 StatusFBD_HM: 32 FBD_HM
 SG_ StatusFBD_HM_PowerMode : 0|8@1+ (1,0) [0|0] "" IPB_App1
 SG_ StatusFBD_HM_ResetState : 8|8@1+ (1.0,0) [0|252] "" IPB_App1
 SG_ StatusFBD_HM_ResetReason : 16|8@1+ (1.0,0) [0|252] "" IPB_App1
 SG_ StatusFBD_HM_BLEStatus : 24|8@1+ (1,0) [0|0] "" IPB_App1
 SG_ StatusFBD_HM_UWBStatus : 32|8@1+ (1,0) [0|0] "" IPB_App1
 SG_ StatusFBD_HM_WakeUpReason : 40|8@1+ (1,0) [0|0] "" IPB_App1
 SG_ StatusFBD_HM_IRKListIndexWakeUpT : 48|8@1+ (1.0,0) [0|252] "" IPB_App1
 SG_ StatusFBD_HM_Temperature : 56|8@1+ (1.0,-100) [-100|150] "°C" IPB_App1
 SG_ StatusFBD_HM_BLENumberOfBonding : 64|8@1+ (1.0,0) [0|252] "" IPB_App1
 SG_ StatusFBD_HM_BLENumberActiveConn : 72|8@1+ (1.0,0) [0|252] "" IPB_App1
 SG_ StatusFBD_HM_BLEChipPowerOnReset : 80|8@1+ (1.0,0) [0|252] "" IPB_App1
 SG_ StatusFBD_HM_BLEChipSWResetCount : 88|8@1+ (1.0,0) [0|252] "" IPB_App1
 SG_ StatusFBD_HM_BLEChipWatchdogCoun : 96|8@1+ (1.0,0) [0|252] "" IPB_App1
 SG_ StatusFBD_HM_BLEChipTemperatureP : 104|8@1+ (1.0,0) [0|252] "" IPB_App1
 SG_ StatusFBD_HM_BLEChipThermalShutd : 112|8@1+ (1.0,0) [0|252] "" IPB_App1
 SG_ StatusFBD_HM_BLEChipErrorState : 120|8@1+ (1,0) [0|0] "" IPB_App1
 SG_ StatusFBD_HM_UWBChipPowerOnReset : 128|8@1+ (1.0,0) [0|252] "" IPB_App1
 SG_ StatusFBD_HM_UWBChipSWResetCount : 136|8@1+ (1.0,0) [0|252] "" IPB_App1
 SG_ StatusFBD_HM_UWBChipWatchdogCoun : 144|8@1+ (1.0,0) [0|252] "" IPB_App1
 SG_ StatusFBD_HM_UWBChipTemperatureP : 152|8@1+ (1.0,0) [0|252] "" IPB_App1
 SG_ StatusFBD_HM_UWBChipThermalShutd : 160|8@1+ (1.0,0) [0|252] "" IPB_App1
 SG_ StatusFBD_HM_UWBChipErrorState : 168|8@1+ (1,0) [0|0] "" IPB_App1
 SG_ StatusFBD_HM_ProgrammingCounter : 176|8@1+ (1.0,0) [0|252] "" IPB_App1
 SG_ StatusFBD_HM_ProgrammingErrorCou : 184|8@1+ (1.0,0) [0|252] "" IPB_App1
 SG_ StatusFBD_HM_SPIHangupCounter : 192|8@1+ (1.0,0) [0|252] "" IPB_App1
 SG_ StatusFBD_HM_SBCChipTemperatureP : 200|8@1+ (1.0,0) [0|252] "" IPB_App1
 SG_ StatusFBD_HM_SBCChipThermalShutd : 208|8@1+ (1.0,0) [0|252] "" IPB_App1
 SG_ StatusFBD_HM_SBCErrorState : 216|8@1+ (1,0) [0|0] "" IPB_App1
 SG_ StatusFBD_HM_OptionCode : 224|8@1+ (1,0) [0|0] "" IPB_App1
 SG_ StatusFBD_HM_UWBCollisionCounter : 232|8@1+ (1.0,0) [0|252] "" IPB_App1
 SG_ StatusFBD_HM_DebugInformation1 : 240|8@1+ (1,0) [0|0] "" IPB_App1
 SG_ StatusFBD_HM_DebugInformation2 : 248|8@1+ (1,0) [0|0] "" IPB_App1

BO_ 157 StatusFBD_HR: 32 FBD_HR
 SG_ StatusFBD_HR_PowerMode : 0|8@1+ (1,0) [0|0] "" IPB_App1
 SG_ StatusFBD_HR_ResetState : 8|8@1+ (1.0,0) [0|252] "" IPB_App1
 SG_ StatusFBD_HR_ResetReason : 16|8@1+ (1.0,0) [0|252] "" IPB_App1
 SG_ StatusFBD_HR_BLEStatus : 24|8@1+ (1,0) [0|0] "" IPB_App1
 SG_ StatusFBD_HR_UWBStatus : 32|8@1+ (1,0) [0|0] "" IPB_App1
 SG_ StatusFBD_HR_WakeUpReason : 40|8@1+ (1,0) [0|0] "" IPB_App1
 SG_ StatusFBD_HR_IRKListIndexWakeUpT : 48|8@1+ (1.0,0) [0|252] "" IPB_App1
 SG_ StatusFBD_HR_Temperature : 56|8@1+ (1.0,-100) [-100|150] "°C" IPB_App1
 SG_ StatusFBD_HR_BLENumberOfBonding : 64|8@1+ (1.0,0) [0|252] "" IPB_App1
 SG_ StatusFBD_HR_BLENumberActiveConn : 72|8@1+ (1.0,0) [0|252] "" IPB_App1
 SG_ StatusFBD_HR_BLEChipPowerOnReset : 80|8@1+ (1.0,0) [0|252] "" IPB_App1
 SG_ StatusFBD_HR_BLEChipSWResetCount : 88|8@1+ (1.0,0) [0|252] "" IPB_App1
 SG_ StatusFBD_HR_BLEChipWatchdogCoun : 96|8@1+ (1.0,0) [0|252] "" IPB_App1
 SG_ StatusFBD_HR_BLEChipTemperatureP : 104|8@1+ (1.0,0) [0|252] "" IPB_App1
 SG_ StatusFBD_HR_BLEChipThermalShutd : 112|8@1+ (1.0,0) [0|252] "" IPB_App1
 SG_ StatusFBD_HR_BLEChipErrorState : 120|8@1+ (1,0) [0|0] "" IPB_App1
 SG_ StatusFBD_HR_UWBChipPowerOnReset : 128|8@1+ (1.0,0) [0|252] "" IPB_App1
 SG_ StatusFBD_HR_UWBChipSWResetCount : 136|8@1+ (1.0,0) [0|252] "" IPB_App1
 SG_ StatusFBD_HR_UWBChipWatchdogCoun : 144|8@1+ (1.0,0) [0|252] "" IPB_App1
 SG_ StatusFBD_HR_UWBChipTemperatureP : 152|8@1+ (1.0,0) [0|252] "" IPB_App1
 SG_ StatusFBD_HR_UWBChipThermalShutd : 160|8@1+ (1.0,0) [0|252] "" IPB_App1
 SG_ StatusFBD_HR_UWBChipErrorState : 168|8@1+ (1,0) [0|0] "" IPB_App1
 SG_ StatusFBD_HR_ProgrammingCounter : 176|8@1+ (1.0,0) [0|252] "" IPB_App1
 SG_ StatusFBD_HR_ProgrammingErrorCou : 184|8@1+ (1.0,0) [0|252] "" IPB_App1
 SG_ StatusFBD_HR_SPIHangupCounter : 192|8@1+ (1.0,0) [0|252] "" IPB_App1
 SG_ StatusFBD_HR_SBCChipTemperatureP : 200|8@1+ (1.0,0) [0|252] "" IPB_App1
 SG_ StatusFBD_HR_SBCChipThermalShutd : 208|8@1+ (1.0,0) [0|252] "" IPB_App1
 SG_ StatusFBD_HR_SBCErrorState : 216|8@1+ (1,0) [0|0] "" IPB_App1
 SG_ StatusFBD_HR_OptionCode : 224|8@1+ (1,0) [0|0] "" IPB_App1
 SG_ StatusFBD_HR_UWBCollisionCounter : 232|8@1+ (1.0,0) [0|252] "" IPB_App1
 SG_ StatusFBD_HR_DebugInformation1 : 240|8@1+ (1,0) [0|0] "" IPB_App1
 SG_ StatusFBD_HR_DebugInformation2 : 248|8@1+ (1,0) [0|0] "" IPB_App1

BO_ 152 StatusFBD_Miko: 32 FBD_Miko
 SG_ StatusFBD_Miko_PowerMode : 0|8@1+ (1,0) [0|0] "" IPB_App1
 SG_ StatusFBD_Miko_ResetState : 8|8@1+ (1.0,0) [0|252] "" IPB_App1
 SG_ StatusFBD_Miko_ResetReason : 16|8@1+ (1.0,0) [0|252] "" IPB_App1
 SG_ StatusFBD_Miko_BLEStatus : 24|8@1+ (1,0) [0|0] "" IPB_App1
 SG_ StatusFBD_Miko_UWBStatus : 32|8@1+ (1,0) [0|0] "" IPB_App1
 SG_ StatusFBD_Miko_WakeUpReason : 40|8@1+ (1,0) [0|0] "" IPB_App1
 SG_ StatusFBD_Miko_IRKListIndexWakeU : 48|8@1+ (1.0,0) [0|252] "" IPB_App1
 SG_ StatusFBD_Miko_Temperature : 56|8@1+ (1.0,-100) [-100|150] "°C" IPB_App1
 SG_ StatusFBD_Miko_BLENumberOfBondin : 64|8@1+ (1.0,0) [0|252] "" IPB_App1
 SG_ StatusFBD_Miko_BLENumberActiveCo : 72|8@1+ (1.0,0) [0|252] "" IPB_App1
 SG_ StatusFBD_Miko_BLEChipPowerOnRes : 80|8@1+ (1.0,0) [0|252] "" IPB_App1
 SG_ StatusFBD_Miko_BLEChipSWResetCou : 88|8@1+ (1.0,0) [0|252] "" IPB_App1
 SG_ StatusFBD_Miko_BLEChipWatchdogCo : 96|8@1+ (1.0,0) [0|252] "" IPB_App1
 SG_ StatusFBD_Miko_BLEChipTemperatur : 104|8@1+ (1.0,0) [0|252] "" IPB_App1
 SG_ StatusFBD_Miko_BLEChipThermalShu : 112|8@1+ (1.0,0) [0|252] "" IPB_App1
 SG_ StatusFBD_Miko_BLEChipErrorState : 120|8@1+ (1,0) [0|0] "" IPB_App1
 SG_ StatusFBD_Miko_UWBChipPowerOnRes : 128|8@1+ (1.0,0) [0|252] "" IPB_App1
 SG_ StatusFBD_Miko_UWBChipSWResetCou : 136|8@1+ (1.0,0) [0|252] "" IPB_App1
 SG_ StatusFBD_Miko_UWBChipWatchdogCo : 144|8@1+ (1.0,0) [0|252] "" IPB_App1
 SG_ StatusFBD_Miko_UWBChipTemperatur : 152|8@1+ (1.0,0) [0|252] "" IPB_App1
 SG_ StatusFBD_Miko_UWBChipThermalShu : 160|8@1+ (1.0,0) [0|252] "" IPB_App1
 SG_ StatusFBD_Miko_UWBChipErrorState : 168|8@1+ (1,0) [0|0] "" IPB_App1
 SG_ StatusFBD_Miko_ProgrammingCounte : 176|8@1+ (1.0,0) [0|252] "" IPB_App1
 SG_ StatusFBD_Miko_ProgrammingErrorC : 184|8@1+ (1.0,0) [0|252] "" IPB_App1
 SG_ StatusFBD_Miko_SPIHangupCounter : 192|8@1+ (1.0,0) [0|252] "" IPB_App1
 SG_ StatusFBD_Miko_SBCChipTemperatur : 200|8@1+ (1.0,0) [0|252] "" IPB_App1
 SG_ StatusFBD_Miko_SBCChipThermalShu : 208|8@1+ (1.0,0) [0|252] "" IPB_App1
 SG_ StatusFBD_Miko_SBCErrorState : 216|8@1+ (1,0) [0|0] "" IPB_App1
 SG_ StatusFBD_Miko_OptionCode : 224|8@1+ (1,0) [0|0] "" IPB_App1
 SG_ StatusFBD_Miko_UWBCollisionCount : 232|8@1+ (1.0,0) [0|252] "" IPB_App1
 SG_ StatusFBD_Miko_DebugInformation1 : 240|8@1+ (1,0) [0|0] "" IPB_App1
 SG_ StatusFBD_Miko_DebugInformation2 : 248|8@1+ (1,0) [0|0] "" IPB_App1

BO_ 815 StatusFBD_MM: 64 FBD_MM
 SG_ StatusFBD_MM_PowerMode : 0|8@1+ (1,0) [0|0] "" IPB_App1
 SG_ StatusFBD_MM_ResetState : 8|8@1+ (1.0,0) [0|252] "" IPB_App1
 SG_ StatusFBD_MM_ResetReason : 16|8@1+ (1.0,0) [0|252] "" IPB_App1
 SG_ StatusFBD_MM_BLEStatus : 24|8@1+ (1,0) [0|0] "" IPB_App1
 SG_ StatusFBD_MM_UWBStatus : 32|8@1+ (1,0) [0|0] "" IPB_App1
 SG_ StatusFBD_MM_WakeUpReason : 40|8@1+ (1,0) [0|0] "" IPB_App1
 SG_ StatusFBD_MM_IRKListIndexWakeUpT : 48|8@1+ (1.0,0) [0|252] "" IPB_App1
 SG_ StatusFBD_MM_Temperature : 56|8@1+ (1.0,-100) [-100|150] "°C" IPB_App1
 SG_ StatusFBD_MM_BLENumberOfBonding : 64|8@1+ (1.0,0) [0|252] "" IPB_App1
 SG_ StatusFBD_MM_BLENumberActiveConn : 72|8@1+ (1.0,0) [0|252] "" IPB_App1
 SG_ StatusFBD_MM_BLEChipPowerOnReset : 80|8@1+ (1.0,0) [0|252] "" IPB_App1
 SG_ StatusFBD_MM_BLEChipSWResetCount : 88|8@1+ (1.0,0) [0|252] "" IPB_App1
 SG_ StatusFBD_MM_BLEChipWatchdogCoun : 96|8@1+ (1.0,0) [0|252] "" IPB_App1
 SG_ StatusFBD_MM_BLEChipTemperatureP : 104|8@1+ (1.0,0) [0|252] "" IPB_App1
 SG_ StatusFBD_MM_BLEChipThermalShutd : 112|8@1+ (1.0,0) [0|252] "" IPB_App1
 SG_ StatusFBD_MM_BLEChipErrorState : 120|8@1+ (1,0) [0|0] "" IPB_App1
 SG_ StatusFBD_MM_UWBChipPowerOnReset : 128|8@1+ (1.0,0) [0|252] "" IPB_App1
 SG_ StatusFBD_MM_UWBChipSWResetCount : 136|8@1+ (1.0,0) [0|252] "" IPB_App1
 SG_ StatusFBD_MM_UWBChipWatchdogCoun : 144|8@1+ (1.0,0) [0|252] "" IPB_App1
 SG_ StatusFBD_MM_UWBChipTemperatureP : 152|8@1+ (1.0,0) [0|252] "" IPB_App1
 SG_ StatusFBD_MM_UWBChipThermalShutd : 160|8@1+ (1.0,0) [0|252] "" IPB_App1
 SG_ StatusFBD_MM_UWBChipErrorState : 168|8@1+ (1,0) [0|0] "" IPB_App1
 SG_ StatusFBD_MM_ProgrammingCounter : 176|8@1+ (1.0,0) [0|252] "" IPB_App1
 SG_ StatusFBD_MM_ProgrammingErrorCou : 184|8@1+ (1.0,0) [0|252] "" IPB_App1
 SG_ StatusFBD_MM_SPIHangupCounter : 192|8@1+ (1.0,0) [0|252] "" IPB_App1
 SG_ StatusFBD_MM_SBCChipTemperatureP : 200|8@1+ (1.0,0) [0|252] "" IPB_App1
 SG_ StatusFBD_MM_SBCChipThermalShutd : 208|8@1+ (1.0,0) [0|252] "" IPB_App1
 SG_ StatusFBD_MM_SBCErrorState : 216|8@1+ (1,0) [0|0] "" IPB_App1
 SG_ StatusFBD_MM_OptionCode : 224|8@1+ (1,0) [0|0] "" IPB_App1
 SG_ StatusFBD_MM_UWBCollisionCounter : 232|8@1+ (1.0,0) [0|252] "" IPB_App1
 SG_ StatusFBD_MM_DebugInformation1 : 240|8@1+ (1,0) [0|0] "" IPB_App1
 SG_ StatusFBD_MM_DebugInformation2 : 248|8@1+ (1,0) [0|0] "" IPB_App1

BO_ 153 StatusFBD_Trunk: 32 FBD_Trunk
 SG_ StatusFBD_Trunk_PowerMode : 0|8@1+ (1,0) [0|0] "" IPB_App1
 SG_ StatusFBD_Trunk_ResetState : 8|8@1+ (1.0,0) [0|252] "" IPB_App1
 SG_ StatusFBD_Trunk_ResetReason : 16|8@1+ (1.0,0) [0|252] "" IPB_App1
 SG_ StatusFBD_Trunk_BLEStatus : 24|8@1+ (1,0) [0|0] "" IPB_App1
 SG_ StatusFBD_Trunk_UWBStatus : 32|8@1+ (1,0) [0|0] "" IPB_App1
 SG_ StatusFBD_Trunk_WakeUpReason : 40|8@1+ (1,0) [0|0] "" IPB_App1
 SG_ StatusFBD_Trunk_IRKListIndexWake : 48|8@1+ (1.0,0) [0|252] "" IPB_App1
 SG_ StatusFBD_Trunk_Temperature : 56|8@1+ (1.0,-100) [-100|150] "°C" IPB_App1
 SG_ StatusFBD_Trunk_BLENumberOfBondi : 64|8@1+ (1.0,0) [0|252] "" IPB_App1
 SG_ StatusFBD_Trunk_BLENumberActiveC : 72|8@1+ (1.0,0) [0|252] "" IPB_App1
 SG_ StatusFBD_Trunk_BLEChipPowerOnRe : 80|8@1+ (1.0,0) [0|252] "" IPB_App1
 SG_ StatusFBD_Trunk_BLEChipSWResetCo : 88|8@1+ (1.0,0) [0|252] "" IPB_App1
 SG_ StatusFBD_Trunk_BLEChipWatchdogC : 96|8@1+ (1.0,0) [0|252] "" IPB_App1
 SG_ StatusFBD_Trunk_BLEChipTemperatu : 104|8@1+ (1.0,0) [0|252] "" IPB_App1
 SG_ StatusFBD_Trunk_BLEChipThermalSh : 112|8@1+ (1.0,0) [0|252] "" IPB_App1
 SG_ StatusFBD_Trunk_BLEChipErrorStat : 120|8@1+ (1,0) [0|0] "" IPB_App1
 SG_ StatusFBD_Trunk_UWBChipPowerOnRe : 128|8@1+ (1.0,0) [0|252] "" IPB_App1
 SG_ StatusFBD_Trunk_UWBChipSWResetCo : 136|8@1+ (1.0,0) [0|252] "" IPB_App1
 SG_ StatusFBD_Trunk_UWBChipWatchdogC : 144|8@1+ (1.0,0) [0|252] "" IPB_App1
 SG_ StatusFBD_Trunk_UWBChipTemperatu : 152|8@1+ (1.0,0) [0|252] "" IPB_App1
 SG_ StatusFBD_Trunk_UWBChipThermalSh : 160|8@1+ (1.0,0) [0|252] "" IPB_App1
 SG_ StatusFBD_Trunk_UWBChipErrorStat : 168|8@1+ (1,0) [0|0] "" IPB_App1
 SG_ StatusFBD_Trunk_ProgrammingCount : 176|8@1+ (1.0,0) [0|252] "" IPB_App1
 SG_ StatusFBD_Trunk_ProgrammingError : 184|8@1+ (1.0,0) [0|252] "" IPB_App1
 SG_ StatusFBD_Trunk_SPIHangupCounter : 192|8@1+ (1.0,0) [0|252] "" IPB_App1
 SG_ StatusFBD_Trunk_SBCChipTemperatu : 200|8@1+ (1.0,0) [0|252] "" IPB_App1
 SG_ StatusFBD_Trunk_SBCChipThermalSh : 208|8@1+ (1.0,0) [0|252] "" IPB_App1
 SG_ StatusFBD_Trunk_SBCErrorState : 216|8@1+ (1,0) [0|0] "" IPB_App1
 SG_ StatusFBD_Trunk_OptionCode : 224|8@1+ (1,0) [0|0] "" IPB_App1
 SG_ StatusFBD_Trunk_UWBCollisionCoun : 232|8@1+ (1.0,0) [0|252] "" IPB_App1
 SG_ StatusFBD_Trunk_DebugInformation : 240|8@1+ (1,0) [0|0] "" IPB_App1
 SG_ StatusFBD_Trunk_DebugInformati_2 : 248|8@1+ (1,0) [0|0] "" IPB_App1

BO_ 154 StatusFBD_VL: 32 FBD_VL
 SG_ StatusFBD_VL_PowerMode : 0|8@1+ (1,0) [0|0] "" IPB_App1
 SG_ StatusFBD_VL_ResetState : 8|8@1+ (1.0,0) [0|252] "" IPB_App1
 SG_ StatusFBD_VL_ResetReason : 16|8@1+ (1.0,0) [0|252] "" IPB_App1
 SG_ StatusFBD_VL_BLEStatus : 24|8@1+ (1,0) [0|0] "" IPB_App1
 SG_ StatusFBD_VL_UWBStatus : 32|8@1+ (1,0) [0|0] "" IPB_App1
 SG_ StatusFBD_VL_WakeUpReason : 40|8@1+ (1,0) [0|0] "" IPB_App1
 SG_ StatusFBD_VL_IRKListIndexWakeUpT : 48|8@1+ (1.0,0) [0|252] "" IPB_App1
 SG_ StatusFBD_VL_Temperature : 56|8@1+ (1.0,-100) [-100|150] "°C" IPB_App1
 SG_ StatusFBD_VL_BLENumberOfBonding : 64|8@1+ (1.0,0) [0|252] "" IPB_App1
 SG_ StatusFBD_VL_BLENumberActiveConn : 72|8@1+ (1.0,0) [0|252] "" IPB_App1
 SG_ StatusFBD_VL_BLEChipPowerOnReset : 80|8@1+ (1.0,0) [0|252] "" IPB_App1
 SG_ StatusFBD_VL_BLEChipSWResetCount : 88|8@1+ (1.0,0) [0|252] "" IPB_App1
 SG_ StatusFBD_VL_BLEChipWatchdogCoun : 96|8@1+ (1.0,0) [0|252] "" IPB_App1
 SG_ StatusFBD_VL_BLEChipTemperatureP : 104|8@1+ (1.0,0) [0|252] "" IPB_App1
 SG_ StatusFBD_VL_BLEChipThermalShutd : 112|8@1+ (1.0,0) [0|252] "" IPB_App1
 SG_ StatusFBD_VL_BLEChipErrorState : 120|8@1+ (1,0) [0|0] "" IPB_App1
 SG_ StatusFBD_VL_UWBChipPowerOnReset : 128|8@1+ (1.0,0) [0|252] "" IPB_App1
 SG_ StatusFBD_VL_UWBChipSWResetCount : 136|8@1+ (1.0,0) [0|252] "" IPB_App1
 SG_ StatusFBD_VL_UWBChipWatchdogCoun : 144|8@1+ (1.0,0) [0|252] "" IPB_App1
 SG_ StatusFBD_VL_UWBChipTemperatureP : 152|8@1+ (1.0,0) [0|252] "" IPB_App1
 SG_ StatusFBD_VL_UWBChipThermalShutd : 160|8@1+ (1.0,0) [0|252] "" IPB_App1
 SG_ StatusFBD_VL_UWBChipErrorState : 168|8@1+ (1,0) [0|0] "" IPB_App1
 SG_ StatusFBD_VL_ProgrammingCounter : 176|8@1+ (1.0,0) [0|252] "" IPB_App1
 SG_ StatusFBD_VL_ProgrammingErrorCou : 184|8@1+ (1.0,0) [0|252] "" IPB_App1
 SG_ StatusFBD_VL_SPIHangupCounter : 192|8@1+ (1.0,0) [0|252] "" IPB_App1
 SG_ StatusFBD_VL_SBCChipTemperatureP : 200|8@1+ (1.0,0) [0|252] "" IPB_App1
 SG_ StatusFBD_VL_SBCChipThermalShutd : 208|8@1+ (1.0,0) [0|252] "" IPB_App1
 SG_ StatusFBD_VL_SBCErrorState : 216|8@1+ (1,0) [0|0] "" IPB_App1
 SG_ StatusFBD_VL_OptionCode : 224|8@1+ (1,0) [0|0] "" IPB_App1
 SG_ StatusFBD_VL_UWBCollisionCounter : 232|8@1+ (1.0,0) [0|252] "" IPB_App1
 SG_ StatusFBD_VL_DebugInformation1 : 240|8@1+ (1,0) [0|0] "" IPB_App1
 SG_ StatusFBD_VL_DebugInformation2 : 248|8@1+ (1,0) [0|0] "" IPB_App1

BO_ 150 StatusFBD_VM: 32 FBD_VM
 SG_ StatusFBD_VM_PowerMode : 0|8@1+ (1,0) [0|0] "" IPB_App1
 SG_ StatusFBD_VM_ResetState : 8|8@1+ (1.0,0) [0|252] "" IPB_App1
 SG_ StatusFBD_VM_ResetReason : 16|8@1+ (1.0,0) [0|252] "" IPB_App1
 SG_ StatusFBD_VM_BLEStatus : 24|8@1+ (1,0) [0|0] "" IPB_App1
 SG_ StatusFBD_VM_UWBStatus : 32|8@1+ (1,0) [0|0] "" IPB_App1
 SG_ StatusFBD_VM_WakeUpReason : 40|8@1+ (1,0) [0|0] "" IPB_App1
 SG_ StatusFBD_VM_IRKListIndexWakeUpT : 48|8@1+ (1.0,0) [0|252] "" IPB_App1
 SG_ StatusFBD_VM_Temperature : 56|8@1+ (1.0,-100) [-100|150] "°C" IPB_App1
 SG_ StatusFBD_VM_BLENumberOfBonding : 64|8@1+ (1.0,0) [0|252] "" IPB_App1
 SG_ StatusFBD_VM_BLENumberActiveConn : 72|8@1+ (1.0,0) [0|252] "" IPB_App1
 SG_ StatusFBD_VM_BLEChipPowerOnReset : 80|8@1+ (1.0,0) [0|252] "" IPB_App1
 SG_ StatusFBD_VM_BLEChipSWResetCount : 88|8@1+ (1.0,0) [0|252] "" IPB_App1
 SG_ StatusFBD_VM_BLEChipWatchdogCoun : 96|8@1+ (1.0,0) [0|252] "" IPB_App1
 SG_ StatusFBD_VM_BLEChipTemperatureP : 104|8@1+ (1.0,0) [0|252] "" IPB_App1
 SG_ StatusFBD_VM_BLEChipThermalShutd : 112|8@1+ (1.0,0) [0|252] "" IPB_App1
 SG_ StatusFBD_VM_BLEChipErrorState : 120|8@1+ (1,0) [0|0] "" IPB_App1
 SG_ StatusFBD_VM_UWBChipPowerOnReset : 128|8@1+ (1.0,0) [0|252] "" IPB_App1
 SG_ StatusFBD_VM_UWBChipSWResetCount : 136|8@1+ (1.0,0) [0|252] "" IPB_App1
 SG_ StatusFBD_VM_UWBChipWatchdogCoun : 144|8@1+ (1.0,0) [0|252] "" IPB_App1
 SG_ StatusFBD_VM_UWBChipTemperatureP : 152|8@1+ (1.0,0) [0|252] "" IPB_App1
 SG_ StatusFBD_VM_UWBChipThermalShutd : 160|8@1+ (1.0,0) [0|252] "" IPB_App1
 SG_ StatusFBD_VM_UWBChipErrorState : 168|8@1+ (1,0) [0|0] "" IPB_App1
 SG_ StatusFBD_VM_ProgrammingCounter : 176|8@1+ (1.0,0) [0|252] "" IPB_App1
 SG_ StatusFBD_VM_ProgrammingErrorCou : 184|8@1+ (1.0,0) [0|252] "" IPB_App1
 SG_ StatusFBD_VM_SPIHangupCounter : 192|8@1+ (1.0,0) [0|252] "" IPB_App1
 SG_ StatusFBD_VM_SBCChipTemperatureP : 200|8@1+ (1.0,0) [0|252] "" IPB_App1
 SG_ StatusFBD_VM_SBCChipThermalShutd : 208|8@1+ (1.0,0) [0|252] "" IPB_App1
 SG_ StatusFBD_VM_SBCErrorState : 216|8@1+ (1,0) [0|0] "" IPB_App1
 SG_ StatusFBD_VM_OptionCode : 224|8@1+ (1,0) [0|0] "" IPB_App1
 SG_ StatusFBD_VM_UWBCollisionCounter : 232|8@1+ (1.0,0) [0|252] "" IPB_App1
 SG_ StatusFBD_VM_DebugInformation1 : 240|8@1+ (1,0) [0|0] "" IPB_App1
 SG_ StatusFBD_VM_DebugInformation2 : 248|8@1+ (1,0) [0|0] "" IPB_App1

BO_ 155 StatusFBD_VR: 32 FBD_VR
 SG_ StatusFBD_VR_PowerMode : 0|8@1+ (1,0) [0|0] "" IPB_App1
 SG_ StatusFBD_VR_ResetState : 8|8@1+ (1.0,0) [0|252] "" IPB_App1
 SG_ StatusFBD_VR_ResetReason : 16|8@1+ (1.0,0) [0|252] "" IPB_App1
 SG_ StatusFBD_VR_BLEStatus : 24|8@1+ (1,0) [0|0] "" IPB_App1
 SG_ StatusFBD_VR_UWBStatus : 32|8@1+ (1,0) [0|0] "" IPB_App1
 SG_ StatusFBD_VR_WakeUpReason : 40|8@1+ (1,0) [0|0] "" IPB_App1
 SG_ StatusFBD_VR_IRKListIndexWakeUpT : 48|8@1+ (1.0,0) [0|252] "" IPB_App1
 SG_ StatusFBD_VR_Temperature : 56|8@1+ (1.0,-100) [-100|150] "°C" IPB_App1
 SG_ StatusFBD_VR_BLENumberOfBonding : 64|8@1+ (1.0,0) [0|252] "" IPB_App1
 SG_ StatusFBD_VR_BLENumberActiveConn : 72|8@1+ (1.0,0) [0|252] "" IPB_App1
 SG_ StatusFBD_VR_BLEChipPowerOnReset : 80|8@1+ (1.0,0) [0|252] "" IPB_App1
 SG_ StatusFBD_VR_BLEChipSWResetCount : 88|8@1+ (1.0,0) [0|252] "" IPB_App1
 SG_ StatusFBD_VR_BLEChipWatchdogCoun : 96|8@1+ (1.0,0) [0|252] "" IPB_App1
 SG_ StatusFBD_VR_BLEChipTemperatureP : 104|8@1+ (1.0,0) [0|252] "" IPB_App1
 SG_ StatusFBD_VR_BLEChipThermalShutd : 112|8@1+ (1.0,0) [0|252] "" IPB_App1
 SG_ StatusFBD_VR_BLEChipErrorState : 120|8@1+ (1,0) [0|0] "" IPB_App1
 SG_ StatusFBD_VR_UWBChipPowerOnReset : 128|8@1+ (1.0,0) [0|252] "" IPB_App1
 SG_ StatusFBD_VR_UWBChipSWResetCount : 136|8@1+ (1.0,0) [0|252] "" IPB_App1
 SG_ StatusFBD_VR_UWBChipWatchdogCoun : 144|8@1+ (1.0,0) [0|252] "" IPB_App1
 SG_ StatusFBD_VR_UWBChipTemperatureP : 152|8@1+ (1.0,0) [0|252] "" IPB_App1
 SG_ StatusFBD_VR_UWBChipThermalShutd : 160|8@1+ (1.0,0) [0|252] "" IPB_App1
 SG_ StatusFBD_VR_UWBChipErrorState : 168|8@1+ (1,0) [0|0] "" IPB_App1
 SG_ StatusFBD_VR_ProgrammingCounter : 176|8@1+ (1.0,0) [0|252] "" IPB_App1
 SG_ StatusFBD_VR_ProgrammingErrorCou : 184|8@1+ (1.0,0) [0|252] "" IPB_App1
 SG_ StatusFBD_VR_SPIHangupCounter : 192|8@1+ (1.0,0) [0|252] "" IPB_App1
 SG_ StatusFBD_VR_SBCChipTemperatureP : 200|8@1+ (1.0,0) [0|252] "" IPB_App1
 SG_ StatusFBD_VR_SBCChipThermalShutd : 208|8@1+ (1.0,0) [0|252] "" IPB_App1
 SG_ StatusFBD_VR_SBCErrorState : 216|8@1+ (1,0) [0|0] "" IPB_App1
 SG_ StatusFBD_VR_OptionCode : 224|8@1+ (1,0) [0|0] "" IPB_App1
 SG_ StatusFBD_VR_UWBCollisionCounter : 232|8@1+ (1.0,0) [0|252] "" IPB_App1
 SG_ StatusFBD_VR_DebugInformation1 : 240|8@1+ (1,0) [0|0] "" IPB_App1
 SG_ StatusFBD_VR_DebugInformation2 : 248|8@1+ (1,0) [0|0] "" IPB_App1

BO_ 226 StatusIRKConfigurationFBD_HL: 8 FBD_HL
 SG_ StatusIRKConfigurationFBD_HL_Lis : 0|8@1+ (1.0,0) [0|252] "" IPB_App1
 SG_ StatusIRKConfigurationFBD_HL_Cha : 8|8@1+ (1,0) [0|0] "" IPB_App1
 SG_ StatusIRKConfigurationFBD_HL_Con : 16|8@1+ (1,0) [0|0] "" IPB_App1

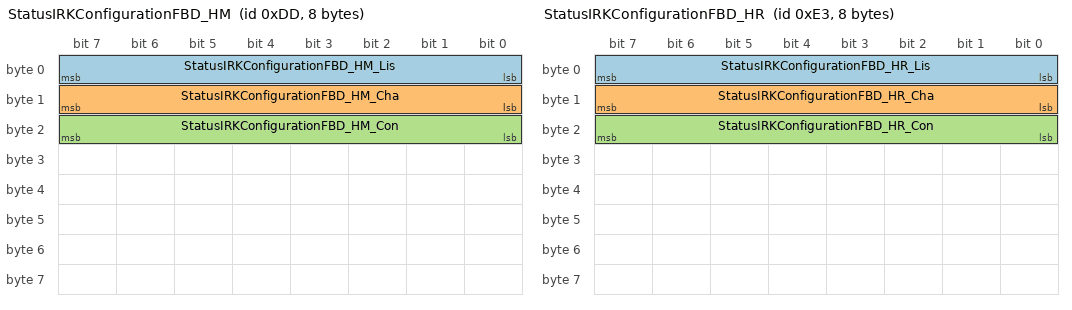
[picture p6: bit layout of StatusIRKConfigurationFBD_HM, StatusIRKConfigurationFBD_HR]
BO_ 221 StatusIRKConfigurationFBD_HM: 8 FBD_HM
 SG_ StatusIRKConfigurationFBD_HM_Lis : 0|8@1+ (1.0,0) [0|252] "" IPB_App1
 SG_ StatusIRKConfigurationFBD_HM_Cha : 8|8@1+ (1,0) [0|0] "" IPB_App1
 SG_ StatusIRKConfigurationFBD_HM_Con : 16|8@1+ (1,0) [0|0] "" IPB_App1

BO_ 227 StatusIRKConfigurationFBD_HR: 8 FBD_HR
 SG_ StatusIRKConfigurationFBD_HR_Lis : 0|8@1+ (1.0,0) [0|252] "" IPB_App1
 SG_ StatusIRKConfigurationFBD_HR_Cha : 8|8@1+ (1,0) [0|0] "" IPB_App1
 SG_ StatusIRKConfigurationFBD_HR_Con : 16|8@1+ (1,0) [0|0] "" IPB_App1

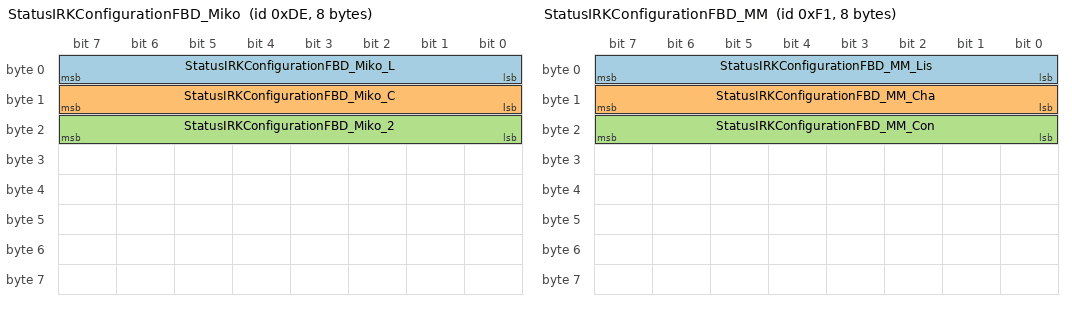
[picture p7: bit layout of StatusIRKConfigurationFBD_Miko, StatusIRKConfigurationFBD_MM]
BO_ 222 StatusIRKConfigurationFBD_Miko: 8 FBD_Miko
 SG_ StatusIRKConfigurationFBD_Miko_L : 0|8@1+ (1.0,0) [0|252] "" IPB_App1
 SG_ StatusIRKConfigurationFBD_Miko_C : 8|8@1+ (1,0) [0|0] "" IPB_App1
 SG_ StatusIRKConfigurationFBD_Miko_2 : 16|8@1+ (1,0) [0|0] "" IPB_App1

BO_ 241 StatusIRKConfigurationFBD_MM: 8 FBD_MM
 SG_ StatusIRKConfigurationFBD_MM_Lis : 0|8@1+ (1.0,0) [0|252] "" IPB_App1
 SG_ StatusIRKConfigurationFBD_MM_Cha : 8|8@1+ (1,0) [0|0] "" IPB_App1
 SG_ StatusIRKConfigurationFBD_MM_Con : 16|8@1+ (1,0) [0|0] "" IPB_App1

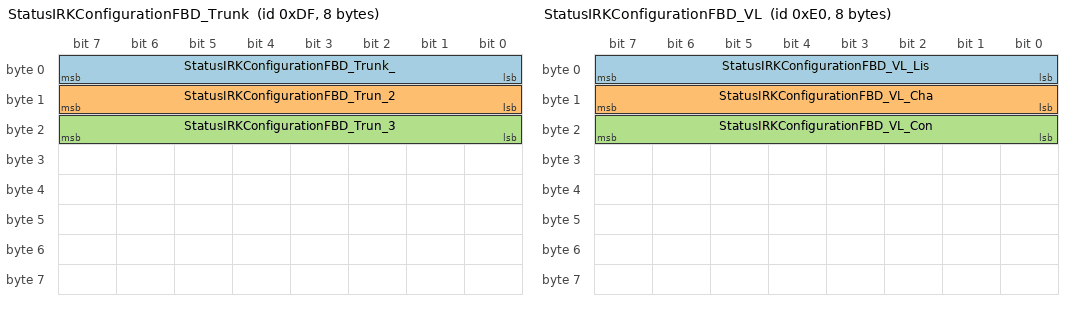
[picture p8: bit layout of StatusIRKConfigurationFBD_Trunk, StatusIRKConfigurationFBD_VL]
BO_ 223 StatusIRKConfigurationFBD_Trunk: 8 FBD_Trunk
 SG_ StatusIRKConfigurationFBD_Trunk_ : 0|8@1+ (1.0,0) [0|252] "" IPB_App1
 SG_ StatusIRKConfigurationFBD_Trun_2 : 8|8@1+ (1,0) [0|0] "" IPB_App1
 SG_ StatusIRKConfigurationFBD_Trun_3 : 16|8@1+ (1,0) [0|0] "" IPB_App1

BO_ 224 StatusIRKConfigurationFBD_VL: 8 FBD_VL
 SG_ StatusIRKConfigurationFBD_VL_Lis : 0|8@1+ (1.0,0) [0|252] "" IPB_App1
 SG_ StatusIRKConfigurationFBD_VL_Cha : 8|8@1+ (1,0) [0|0] "" IPB_App1
 SG_ StatusIRKConfigurationFBD_VL_Con : 16|8@1+ (1,0) [0|0] "" IPB_App1

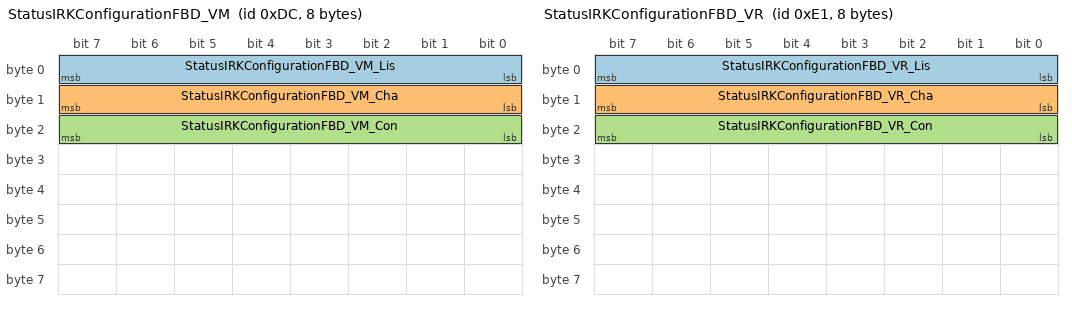
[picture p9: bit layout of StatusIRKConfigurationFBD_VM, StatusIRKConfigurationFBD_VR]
BO_ 220 StatusIRKConfigurationFBD_VM: 8 FBD_VM
 SG_ StatusIRKConfigurationFBD_VM_Lis : 0|8@1+ (1.0,0) [0|252] "" IPB_App1
 SG_ StatusIRKConfigurationFBD_VM_Cha : 8|8@1+ (1,0) [0|0] "" IPB_App1
 SG_ StatusIRKConfigurationFBD_VM_Con : 16|8@1+ (1,0) [0|0] "" IPB_App1

BO_ 225 StatusIRKConfigurationFBD_VR: 8 FBD_VR
 SG_ StatusIRKConfigurationFBD_VR_Lis : 0|8@1+ (1.0,0) [0|252] "" IPB_App1
 SG_ StatusIRKConfigurationFBD_VR_Cha : 8|8@1+ (1,0) [0|0] "" IPB_App1
 SG_ StatusIRKConfigurationFBD_VR_Con : 16|8@1+ (1,0) [0|0] "" IPB_App1

BO_ 236 StatusRangingIntentFBD_HL: 8 FBD_HL
 SG_ StatusRangingIntentFBD_HL_IRKLis : 0|8@1+ (1.0,0) [0|252] "" IPB_App1
 SG_ StatusRangingIntentFBD_HL_Intent : 8|8@1+ (1.0,0) [0|252] "" IPB_App1

BO_ 231 StatusRangingIntentFBD_HM: 8 FBD_HM
 SG_ StatusRangingIntentFBD_HM_IRKLis : 0|8@1+ (1.0,0) [0|252] "" IPB_App1
 SG_ StatusRangingIntentFBD_HM_Intent : 8|8@1+ (1.0,0) [0|252] "" IPB_App1

BO_ 237 StatusRangingIntentFBD_HR: 8 FBD_HR
 SG_ StatusRangingIntentFBD_HR_IRKLis : 0|8@1+ (1.0,0) [0|252] "" IPB_App1
 SG_ StatusRangingIntentFBD_HR_Intent : 8|8@1+ (1.0,0) [0|252] "" IPB_App1

BO_ 232 StatusRangingIntentFBD_Miko: 8 FBD_Miko
 SG_ StatusRangingIntentFBD_Miko_IRKL : 0|8@1+ (1.0,0) [0|252] "" IPB_App1
 SG_ StatusRangingIntentFBD_Miko_Inte : 8|8@1+ (1.0,0) [0|252] "" IPB_App1

BO_ 242 StatusRangingIntentFBD_MM: 8 FBD_MM
 SG_ StatusRangingIntentFBD_MM_IRKLis : 0|8@1+ (1.0,0) [0|252] "" IPB_App1
 SG_ StatusRangingIntentFBD_MM_Intent : 8|8@1+ (1.0,0) [0|252] "" IPB_App1

BO_ 233 StatusRangingIntentFBD_Trunk: 8 FBD_Trunk
 SG_ StatusRangingIntentFBD_Trunk_IRK : 0|8@1+ (1.0,0) [0|252] "" IPB_App1
 SG_ StatusRangingIntentFBD_Trunk_Int : 8|8@1+ (1.0,0) [0|252] "" IPB_App1

BO_ 234 StatusRangingIntentFBD_VL: 8 FBD_VL
 SG_ StatusRangingIntentFBD_VL_IRKLis : 0|8@1+ (1.0,0) [0|252] "" IPB_App1
 SG_ StatusRangingIntentFBD_VL_Intent : 8|8@1+ (1.0,0) [0|252] "" IPB_App1

BO_ 230 StatusRangingIntentFBD_VM: 8 FBD_VM
 SG_ StatusRangingIntentFBD_VM_IRKLis : 0|8@1+ (1.0,0) [0|252] "" IPB_App1
 SG_ StatusRangingIntentFBD_VM_Intent : 8|8@1+ (1.0,0) [0|252] "" IPB_App1

BO_ 235 StatusRangingIntentFBD_VR: 8 FBD_VR
 SG_ StatusRangingIntentFBD_VR_IRKLis : 0|8@1+ (1.0,0) [0|252] "" IPB_App1
 SG_ StatusRangingIntentFBD_VR_Intent : 8|8@1+ (1.0,0) [0|252] "" IPB_App1

BO_ 426 StatusRangingSessionFBD_HL: 12 FBD_HL
 SG_ StatusRangingSessionFBD_HL_Sessi : 0|8@1+ (1.0,0) [0|252] "" IPB_App1
 SG_ StatusRangingSessionFBD_HL_Rangi : 8|16@1+ (1.0,0) [0|65532] "" IPB_App1
 SG_ StatusRangingSessionFBD_HL_Funct : 24|8@1+ (1.0,0) [0|252] "" IPB_App1
 SG_ StatusRangingSessionFBD_HL_Setup : 32|4@1+ (1,0) [0|0] "" IPB_App1
 SG_ StatusRangingSessionFBD_HL_Start : 36|4@1+ (1,0) [0|0] "" IPB_App1
 SG_ StatusRangingSessionFBD_HL_Suspe : 40|4@1+ (1,0) [0|0] "" IPB_App1
 SG_ StatusRangingSessionFBD_HL_Resum : 44|4@1+ (1,0) [0|0] "" IPB_App1
 SG_ StatusRangingSessionFBD_HL_Statu : 48|8@1+ (1.0,0) [0|252] "" IPB_App1
 SG_ StatusRangingSessionFBD_HL_Error : 56|16@1+ (1.0,0) [0|65532] "" IPB_App1
 SG_ StatusRangingSessionFBD_HL_Diag1 : 72|8@1+ (1.0,0) [0|252] "" IPB_App1
 SG_ StatusRangingSessionFBD_HL_Diag2 : 80|8@1+ (1.0,0) [0|252] "" IPB_App1
 SG_ StatusRangingSessionFBD_HL_Diag3 : 88|8@1+ (1.0,0) [0|252] "" IPB_App1

BO_ 421 StatusRangingSessionFBD_HM: 12 FBD_HM
 SG_ StatusRangingSessionFBD_HM_Sessi : 0|8@1+ (1.0,0) [0|252] "" IPB_App1
 SG_ StatusRangingSessionFBD_HM_Frame : 8|16@1+ (1.0,0) [0|65532] "" IPB_App1
 SG_ StatusRangingSessionFBD_HM_Funct : 24|8@1+ (1.0,0) [0|252] "" IPB_App1
 SG_ StatusRangingSessionFBD_HM_Setup : 32|4@1+ (1,0) [0|0] "" IPB_App1
 SG_ StatusRangingSessionFBD_HM_Start : 36|4@1+ (1,0) [0|0] "" IPB_App1
 SG_ StatusRangingSessionFBD_HM_Suspe : 40|4@1+ (1,0) [0|0] "" IPB_App1
 SG_ StatusRangingSessionFBD_HM_Resum : 44|4@1+ (1,0) [0|0] "" IPB_App1
 SG_ StatusRangingSessionFBD_HM_Statu : 48|8@1+ (1.0,0) [0|252] "" IPB_App1
 SG_ StatusRangingSessionFBD_HM_Error : 56|16@1+ (1.0,0) [0|65532] "" IPB_App1
 SG_ StatusRangingSessionFBD_HM_Diag1 : 72|8@1+ (1.0,0) [0|252] "" IPB_App1
 SG_ StatusRangingSessionFBD_HM_Diag2 : 80|8@1+ (1.0,0) [0|252] "" IPB_App1
 SG_ StatusRangingSessionFBD_HM_Diag3 : 88|8@1+ (1.0,0) [0|252] "" IPB_App1

BO_ 427 StatusRangingSessionFBD_HR: 12 FBD_HR
 SG_ StatusRangingSessionFBD_HR_Sessi : 0|8@1+ (1.0,0) [0|252] "" IPB_App1
 SG_ StatusRangingSessionFBD_HR_Frame : 8|16@1+ (1.0,0) [0|65532] "" IPB_App1
 SG_ StatusRangingSessionFBD_HR_Funct : 24|8@1+ (1.0,0) [0|252] "" IPB_App1
 SG_ StatusRangingSessionFBD_HR_Setup : 32|4@1+ (1,0) [0|0] "" IPB_App1
 SG_ StatusRangingSessionFBD_HR_Start : 36|4@1+ (1,0) [0|0] "" IPB_App1
 SG_ StatusRangingSessionFBD_HR_Suspe : 40|4@1+ (1,0) [0|0] "" IPB_App1
 SG_ StatusRangingSessionFBD_HR_Resum : 44|4@1+ (1,0) [0|0] "" IPB_App1
 SG_ StatusRangingSessionFBD_HR_Statu : 48|8@1+ (1.0,0) [0|252] "" IPB_App1
 SG_ StatusRangingSessionFBD_HR_Error : 56|16@1+ (1.0,0) [0|65532] "" IPB_App1
 SG_ StatusRangingSessionFBD_HR_Diag1 : 72|8@1+ (1.0,0) [0|252] "" IPB_App1
 SG_ StatusRangingSessionFBD_HR_Diag2 : 80|8@1+ (1.0,0) [0|252] "" IPB_App1
 SG_ StatusRangingSessionFBD_HR_Diag3 : 88|8@1+ (1.0,0) [0|252] "" IPB_App1

BO_ 422 StatusRangingSessionFBD_Miko: 12 FBD_Miko
 SG_ StatusRangingSessionFBD_Miko_Ses : 0|8@1+ (1.0,0) [0|252] "" IPB_App1
 SG_ StatusRangingSessionFBD_Miko_Fra : 8|16@1+ (1.0,0) [0|65532] "" IPB_App1
 SG_ StatusRangingSessionFBD_Miko_Fun : 24|8@1+ (1.0,0) [0|252] "" IPB_App1
 SG_ StatusRangingSessionFBD_Miko_Set : 32|4@1+ (1,0) [0|0] "" IPB_App1
 SG_ StatusRangingSessionFBD_Miko_Sta : 36|4@1+ (1,0) [0|0] "" IPB_App1
 SG_ StatusRangingSessionFBD_Miko_Sus : 40|4@1+ (1,0) [0|0] "" IPB_App1
 SG_ StatusRangingSessionFBD_Miko_Res : 44|4@1+ (1,0) [0|0] "" IPB_App1
 SG_ StatusRangingSessionFBD_Miko_S_2 : 48|8@1+ (1.0,0) [0|252] "" IPB_App1
 SG_ StatusRangingSessionFBD_Miko_Err : 56|16@1+ (1.0,0) [0|65532] "" IPB_App1
 SG_ StatusRangingSessionFBD_Miko_Dia : 72|8@1+ (1.0,0) [0|252] "" IPB_App1
 SG_ StatusRangingSessionFBD_Miko_D_2 : 80|8@1+ (1.0,0) [0|252] "" IPB_App1
 SG_ StatusRangingSessionFBD_Miko_D_3 : 88|8@1+ (1.0,0) [0|252] "" IPB_App1

BO_ 440 StatusRangingSessionFBD_MM: 12 FBD_MM
 SG_ StatusRangingSessionFBD_MM_Sessi : 0|8@1+ (1.0,0) [0|252] "" IPB_App1
 SG_ StatusRangingSessionFBD_MM_Frame : 8|16@1+ (1.0,0) [0|65532] "" IPB_App1
 SG_ StatusRangingSessionFBD_MM_Funct : 24|8@1+ (1.0,0) [0|252] "" IPB_App1
 SG_ StatusRangingSessionFBD_MM_Setup : 32|4@1+ (1,0) [0|0] "" IPB_App1
 SG_ StatusRangingSessionFBD_MM_Start : 36|4@1+ (1,0) [0|0] "" IPB_App1
 SG_ StatusRangingSessionFBD_MM_Suspe : 40|4@1+ (1,0) [0|0] "" IPB_App1
 SG_ StatusRangingSessionFBD_MM_Resum : 44|4@1+ (1,0) [0|0] "" IPB_App1
 SG_ StatusRangingSessionFBD_MM_Statu : 48|8@1+ (1.0,0) [0|252] "" IPB_App1
 SG_ StatusRangingSessionFBD_MM_Error : 56|16@1+ (1.0,0) [0|65532] "" IPB_App1
 SG_ StatusRangingSessionFBD_MM_Diag1 : 72|8@1+ (1.0,0) [0|252] "" IPB_App1
 SG_ StatusRangingSessionFBD_MM_Diag2 : 80|8@1+ (1.0,0) [0|252] "" IPB_App1
 SG_ StatusRangingSessionFBD_MM_Diag3 : 88|8@1+ (1.0,0) [0|252] "" IPB_App1

BO_ 423 StatusRangingSessionFBD_Trunk: 12 FBD_Trunk
 SG_ StatusRangingSessionFBD_Trunk_Se : 0|8@1+ (1.0,0) [0|252] "" IPB_App1
 SG_ StatusRangingSessionFBD_Trunk_Fr : 8|16@1+ (1.0,0) [0|65532] "" IPB_App1
 SG_ StatusRangingSessionFBD_Trunk_Fu : 24|8@1+ (1.0,0) [0|252] "" IPB_App1
 SG_ StatusRangingSessionFBD_Trunk__2 : 32|4@1+ (1,0) [0|0] "" IPB_App1
 SG_ StatusRangingSessionFBD_Trunk_St : 36|4@1+ (1,0) [0|0] "" IPB_App1
 SG_ StatusRangingSessionFBD_Trunk_Su : 40|4@1+ (1,0) [0|0] "" IPB_App1
 SG_ StatusRangingSessionFBD_Trunk_Re : 44|4@1+ (1,0) [0|0] "" IPB_App1
 SG_ StatusRangingSessionFBD_Trunk__3 : 48|8@1+ (1.0,0) [0|252] "" IPB_App1
 SG_ StatusRangingSessionFBD_Trunk_Er : 56|16@1+ (1.0,0) [0|65532] "" IPB_App1
 SG_ StatusRangingSessionFBD_Trunk_Di : 72|8@1+ (1.0,0) [0|252] "" IPB_App1
 SG_ StatusRangingSessionFBD_Trunk__4 : 80|8@1+ (1.0,0) [0|252] "" IPB_App1
 SG_ StatusRangingSessionFBD_Trunk__5 : 88|8@1+ (1.0,0) [0|252] "" IPB_App1

BO_ 424 StatusRangingSessionFBD_VL: 12 FBD_VL
 SG_ StatusRangingSessionFBD_VL_Sessi : 0|8@1+ (1.0,0) [0|252] "" IPB_App1
 SG_ StatusRangingSessionFBD_VL_Frame : 8|16@1+ (1.0,0) [0|65532] "" IPB_App1
 SG_ StatusRangingSessionFBD_VL_Funct : 24|8@1+ (1.0,0) [0|252] "" IPB_App1
 SG_ StatusRangingSessionFBD_VL_Setup : 32|4@1+ (1,0) [0|0] "" IPB_App1
 SG_ StatusRangingSessionFBD_VL_Start : 36|4@1+ (1,0) [0|0] "" IPB_App1
 SG_ StatusRangingSessionFBD_VL_Suspe : 40|4@1+ (1,0) [0|0] "" IPB_App1
 SG_ StatusRangingSessionFBD_VL_Resum : 44|4@1+ (1,0) [0|0] "" IPB_App1
 SG_ StatusRangingSessionFBD_VL_Statu : 48|8@1+ (1.0,0) [0|252] "" IPB_App1
 SG_ StatusRangingSessionFBD_VL_Error : 56|16@1+ (1.0,0) [0|65532] "" IPB_App1
 SG_ StatusRangingSessionFBD_VL_Diag1 : 72|8@1+ (1.0,0) [0|252] "" IPB_App1
 SG_ StatusRangingSessionFBD_VL_Diag2 : 80|8@1+ (1.0,0) [0|252] "" IPB_App1
 SG_ StatusRangingSessionFBD_VL_Diag3 : 88|8@1+ (1.0,0) [0|252] "" IPB_App1

BO_ 420 StatusRangingSessionFBD_VM: 12 FBD_VM
 SG_ StatusRangingSessionFBD_VM_Sessi : 0|8@1+ (1.0,0) [0|252] "" IPB_App1
 SG_ StatusRangingSessionFBD_VM_Frame : 8|16@1+ (1.0,0) [0|65532] "" IPB_App1
 SG_ StatusRangingSessionFBD_VM_Funct : 24|8@1+ (1.0,0) [0|252] "" IPB_App1
 SG_ StatusRangingSessionFBD_VM_Setup : 32|4@1+ (1,0) [0|0] "" IPB_App1
 SG_ StatusRangingSessionFBD_VM_Start : 36|4@1+ (1,0) [0|0] "" IPB_App1
 SG_ StatusRangingSessionFBD_VM_Suspe : 40|4@1+ (1,0) [0|0] "" IPB_App1
 SG_ StatusRangingSessionFBD_VM_Resum : 44|4@1+ (1,0) [0|0] "" IPB_App1
 SG_ StatusRangingSessionFBD_VM_Statu : 48|8@1+ (1.0,0) [0|252] "" IPB_App1
 SG_ StatusRangingSessionFBD_VM_Error : 56|16@1+ (1.0,0) [0|65532] "" IPB_App1
 SG_ StatusRangingSessionFBD_VM_Diag1 : 72|8@1+ (1.0,0) [0|252] "" IPB_App1
 SG_ StatusRangingSessionFBD_VM_Diag2 : 80|8@1+ (1.0,0) [0|252] "" IPB_App1
 SG_ StatusRangingSessionFBD_VM_Diag3 : 88|8@1+ (1.0,0) [0|252] "" IPB_App1

BO_ 425 StatusRangingSessionFBD_VR: 12 FBD_VR
 SG_ StatusRangingSessionFBD_VR_Sessi : 0|8@1+ (1.0,0) [0|252] "" IPB_App1
 SG_ StatusRangingSessionFBD_VR_Frame : 8|16@1+ (1.0,0) [0|65532] "" IPB_App1
 SG_ StatusRangingSessionFBD_VR_Funct : 24|8@1+ (1.0,0) [0|252] "" IPB_App1
 SG_ StatusRangingSessionFBD_VR_Setup : 32|4@1+ (1,0) [0|0] "" IPB_App1
 SG_ StatusRangingSessionFBD_VR_Start : 36|4@1+ (1,0) [0|0] "" IPB_App1
 SG_ StatusRangingSessionFBD_VR_Suspe : 40|4@1+ (1,0) [0|0] "" IPB_App1
 SG_ StatusRangingSessionFBD_VR_Resum : 44|4@1+ (1,0) [0|0] "" IPB_App1
 SG_ StatusRangingSessionFBD_VR_Statu : 48|8@1+ (1.0,0) [0|252] "" IPB_App1
 SG_ StatusRangingSessionFBD_VR_Error : 56|16@1+ (1.0,0) [0|65532] "" IPB_App1
 SG_ StatusRangingSessionFBD_VR_Diag1 : 72|8@1+ (1.0,0) [0|252] "" IPB_App1
 SG_ StatusRangingSessionFBD_VR_Diag2 : 80|8@1+ (1.0,0) [0|252] "" IPB_App1
 SG_ StatusRangingSessionFBD_VR_Diag3 : 88|8@1+ (1.0,0) [0|252] "" IPB_App1

BO_ 476 StatusRangingSessionSignFBD_HL: 12 FBD_HL
 SG_ StatusRangingSessionSignFBD_HL_S : 0|8@1+ (1.0,0) [0|252] "" IPB_App1
 SG_ StatusRangingSessionSignFBD_HL_F : 8|16@1+ (1.0,0) [0|65532] "" IPB_App1
 SG_ StatusRangingSessionSignFBD_HL_2 : 24|64@1+ (1.0,0) [0|18446744073709551614] "" IPB_App1

BO_ 471 StatusRangingSessionSignFBD_HM: 12 FBD_HM
 SG_ StatusRangingSessionSignFBD_HM_S : 0|8@1+ (1.0,0) [0|252] "" IPB_App1
 SG_ StatusRangingSessionFBD_HM_Rangi : 8|16@1+ (1.0,0) [0|65532] "" IPB_App1
 SG_ StatusRangingSessionSignFBD_HM_2 : 24|64@1+ (1.0,0) [0|18446744073709551614] "" IPB_App1

BO_ 477 StatusRangingSessionSignFBD_HR: 12 FBD_HR
 SG_ StatusRangingSessionSignFBD_HR_S : 0|8@1+ (1.0,0) [0|252] "" IPB_App1
 SG_ StatusRangingSessionFBD_HR_Rangi : 8|16@1+ (1.0,0) [0|65532] "" IPB_App1
 SG_ StatusRangingSessionSignFBD_HR_2 : 24|64@1+ (1.0,0) [0|18446744073709551614] "" IPB_App1

BO_ 472 StatusRangingSessionSignFBD_Miko: 12 FBD_Miko
 SG_ StatusRangingSessionSignFBD_Miko : 0|8@1+ (1.0,0) [0|252] "" IPB_App1
 SG_ StatusRangingSessionFBD_Miko_Ran : 8|16@1+ (1.0,0) [0|65532] "" IPB_App1
 SG_ StatusRangingSessionSignFBD_Mi_2 : 24|64@1+ (1.0,0) [0|18446744073709551614] "" IPB_App1

BO_ 441 StatusRangingSessionSignFBD_MM: 12 FBD_MM
 SG_ StatusRangingSessionSignFBD_MM_S : 0|8@1+ (1.0,0) [0|252] "" IPB_App1
 SG_ StatusRangingSessionFBD_MM_Rangi : 8|16@1+ (1.0,0) [0|65532] "" IPB_App1
 SG_ StatusRangingSessionSignFBD_MM_2 : 24|64@1+ (1.0,0) [0|18446744073709551614] "" IPB_App1

BO_ 473 StatusRangingSessionSignFBD_Trun: 12 FBD_Trunk
 SG_ StatusRangingSessionSignFBD_Trun : 0|8@1+ (1.0,0) [0|252] "" IPB_App1
 SG_ StatusRangingSessionFBD_Trunk_Ra : 8|16@1+ (1.0,0) [0|65532] "" IPB_App1
 SG_ StatusRangingSessionSignFBD_Tr_2 : 24|64@1+ (1.0,0) [0|18446744073709551614] "" IPB_App1

BO_ 474 StatusRangingSessionSignFBD_VL: 12 FBD_VL
 SG_ StatusRangingSessionSignFBD_VL_S : 0|8@1+ (1.0,0) [0|252] "" IPB_App1
 SG_ StatusRangingSessionFBD_VL_Rangi : 8|16@1+ (1.0,0) [0|65532] "" IPB_App1
 SG_ StatusRangingSessionSignFBD_VL_2 : 24|64@1+ (1.0,0) [0|18446744073709551614] "" IPB_App1

BO_ 470 StatusRangingSessionSignFBD_VM: 12 FBD_VM
 SG_ StatusRangingSessionSignFBD_VM_S : 0|8@1+ (1.0,0) [0|252] "" IPB_App1
 SG_ StatusRangingSessionFBD_VM_Rangi : 8|16@1+ (1.0,0) [0|65532] "" IPB_App1
 SG_ StatusRangingSessionSignFBD_VM_2 : 24|64@1+ (1.0,0) [0|18446744073709551614] "" IPB_App1

BO_ 475 StatusRangingSessionSignFBD_VR: 12 FBD_VR
 SG_ StatusRangingSessionSignFBD_VR_S : 0|8@1+ (1.0,0) [0|252] "" IPB_App1
 SG_ StatusRangingSessionFBD_VR_Rangi : 8|16@1+ (1.0,0) [0|65532] "" IPB_App1
 SG_ StatusRangingSessionSignFBD_VR_2 : 24|64@1+ (1.0,0) [0|18446744073709551614] "" IPB_App1

BO_ 126 StatusTimeSyncFBD_HL: 8 FBD_HL
 SG_ StatusTimeSyncFBD_HL_Status : 0|8@1+ (1,0) [0|0] "" FBD_HM,FBD_HR,FBD_MM,FBD_Miko,FBD_Trunk,FBD_VL,FBD_VM,FBD_VR,IPB_App1
 SG_ StatusTimeSyncFBD_HL_ReSyncCorre : 8|16@1+ (1.0,0) [0|65532] "us" FBD_HM,FBD_HR,FBD_MM,FBD_Miko,FBD_Trunk,FBD_VL,FBD_VM,FBD_VR,IPB_App1

BO_ 121 StatusTimeSyncFBD_HM: 8 FBD_HM
 SG_ StatusTimeSyncFBD_HM_Status : 0|8@1+ (1,0) [0|0] "" FBD_HL,FBD_HR,FBD_MM,FBD_Miko,FBD_Trunk,FBD_VL,FBD_VM,FBD_VR,IPB_App1
 SG_ StatusTimeSyncFBD_HM_ReSyncCorre : 8|16@1+ (1.0,0) [0|65532] "us" FBD_HL,FBD_HR,FBD_MM,FBD_Miko,FBD_Trunk,FBD_VL,FBD_VM,FBD_VR,IPB_App1

BO_ 127 StatusTimeSyncFBD_HR: 8 FBD_HR
 SG_ StatusTimeSyncFBD_HR_Status : 0|8@1+ (1,0) [0|0] "" FBD_HL,FBD_HM,FBD_MM,FBD_Miko,FBD_Trunk,FBD_VL,FBD_VM,FBD_VR,IPB_App1
 SG_ StatusTimeSyncFBD_HR_ReSyncCorre : 8|16@1+ (1.0,0) [0|65532] "us" FBD_HL,FBD_HM,FBD_MM,FBD_Miko,FBD_Trunk,FBD_VL,FBD_VM,FBD_VR,IPB_App1

BO_ 122 StatusTimeSyncFBD_Miko: 8 FBD_Miko
 SG_ StatusTimeSyncFBD_Miko_Status : 0|8@1+ (1,0) [0|0] "" FBD_HL,FBD_HM,FBD_HR,FBD_MM,FBD_Trunk,FBD_VL,FBD_VM,FBD_VR,IPB_App1
 SG_ StatusTimeSyncFBD_Miko_ReSyncCor : 8|16@1+ (1.0,0) [0|65532] "us" FBD_HL,FBD_HM,FBD_HR,FBD_MM,FBD_Trunk,FBD_VL,FBD_VM,FBD_VR,IPB_App1

BO_ 812 StatusTimeSyncFBD_MM: 8 FBD_MM
 SG_ StatusTimeSyncFBD_MM_Status : 0|8@1+ (1,0) [0|0] "" IPB_App1
 SG_ StatusTimeSyncFBD_MM_ReSyncCorre : 8|16@1+ (1.0,0) [0|65532] "us" IPB_App1

BO_ 128 StatusTimeSyncFBD_SML: 8 IPB_App1
 SG_ StatusTimeSyncFBD_SML_Status : 0|8@1+ (1,0) [0|0] "" FBD_HL,FBD_HM,FBD_HR,FBD_MM,FBD_Miko,FBD_Trunk,FBD_VL,FBD_VM,FBD_VR
 SG_ StatusTimeSyncFBD_SML_ReSyncCorr : 8|16@1+ (1.0,0) [0|65532] "us" FBD_HL,FBD_HM,FBD_HR,FBD_MM,FBD_Miko,FBD_Trunk,FBD_VL,FBD_VM,FBD_VR

BO_ 129 StatusTimeSyncFBD_SMR: 8 IPB_App1
 SG_ StatusTimeSyncFBD_SMR_Status : 0|8@1+ (1,0) [0|0] "" FBD_HL,FBD_HM,FBD_HR,FBD_MM,FBD_Miko,FBD_Trunk,FBD_VL,FBD_VM,FBD_VR
 SG_ StatusTimeSyncFBD_SMR_ReSyncCorr : 8|16@1+ (1.0,0) [0|65532] "us" FBD_HL,FBD_HM,FBD_HR,FBD_MM,FBD_Miko,FBD_Trunk,FBD_VL,FBD_VM,FBD_VR

BO_ 123 StatusTimeSyncFBD_Trunk: 8 FBD_Trunk
 SG_ StatusTimeSyncFBD_Trunk_Status : 0|8@1+ (1,0) [0|0] "" FBD_HL,FBD_HM,FBD_HR,FBD_MM,FBD_Miko,FBD_VL,FBD_VM,FBD_VR,IPB_App1
 SG_ StatusTimeSyncFBD_Trunk_ReSyncCo : 8|16@1+ (1.0,0) [0|65532] "us" FBD_HL,FBD_HM,FBD_HR,FBD_MM,FBD_Miko,FBD_VL,FBD_VM,FBD_VR,IPB_App1

BO_ 124 StatusTimeSyncFBD_VL: 8 FBD_VL
 SG_ StatusTimeSyncFBD_VL_Status : 0|8@1+ (1,0) [0|0] "" FBD_HL,FBD_HM,FBD_HR,FBD_MM,FBD_Miko,FBD_Trunk,FBD_VM,FBD_VR,IPB_App1
 SG_ StatusTimeSyncFBD_VL_ReSyncCorre : 8|16@1+ (1.0,0) [0|65532] "us" FBD_HL,FBD_HM,FBD_HR,FBD_MM,FBD_Miko,FBD_Trunk,FBD_VM,FBD_VR,IPB_App1

BO_ 120 StatusTimeSyncFBD_VM: 8 FBD_VM
 SG_ StatusTimeSyncFBD_VM_Status : 0|8@1+ (1,0) [0|0] "" FBD_HL,FBD_HM,FBD_HR,FBD_MM,FBD_Miko,FBD_Trunk,FBD_VL,FBD_VR,IPB_App1
 SG_ StatusTimeSyncFBD_VM_ReSyncCorre : 8|16@1+ (1.0,0) [0|65532] "us" FBD_HL,FBD_HM,FBD_HR,FBD_MM,FBD_Miko,FBD_Trunk,FBD_VL,FBD_VR,IPB_App1

BO_ 125 StatusTimeSyncFBD_VR: 8 FBD_VR
 SG_ StatusTimeSyncFBD_VR_Status : 0|8@1+ (1,0) [0|0] "" FBD_HL,FBD_HM,FBD_HR,FBD_MM,FBD_Miko,FBD_Trunk,FBD_VL,FBD_VM,IPB_App1
 SG_ StatusTimeSyncFBD_VR_ReSyncCorre : 8|16@1+ (1.0,0) [0|65532] "us" FBD_HL,FBD_HM,FBD_HR,FBD_MM,FBD_Miko,FBD_Trunk,FBD_VL,FBD_VM,IPB_App1

BO_ 436 StatusUWBRangingFBD_HL: 32 FBD_HL
 SG_ StatusUWBRangingFBD_HL_SessionID : 0|8@1+ (1.0,0) [0|252] "" FBD_HM,FBD_HR,FBD_MM,FBD_Miko,FBD_Trunk,FBD_VL,FBD_VM,FBD_VR,IPB_App1
 SG_ StatusUWBRangingFBD_HL_TimeOfFli : 8|16@1+ (15.65,0) [0|1000000] "ps" FBD_HM,FBD_HR,FBD_MM,FBD_Miko,FBD_Trunk,FBD_VL,FBD_VM,FBD_VR,IPB_App1
 SG_ StatusUWBRangingFBD_HL_RangingBl : 24|16@1+ (1.0,0) [0|65532] "" FBD_HM,FBD_HR,FBD_MM,FBD_Miko,FBD_Trunk,FBD_VL,FBD_VM,FBD_VR,IPB_App1
 SG_ StatusUWBRangingFBD_HL_RangingRo : 40|8@1+ (1.0,0) [0|252] "" FBD_HM,FBD_HR,FBD_MM,FBD_Miko,FBD_Trunk,FBD_VL,FBD_VM,FBD_VR,IPB_App1
 SG_ StatusUWBRangingFBD_HL_OverallRe : 48|8@1+ (0.5,-127) [-127|-1] "dB" FBD_HM,FBD_HR,FBD_MM,FBD_Miko,FBD_Trunk,FBD_VL,FBD_VM,FBD_VR,IPB_App1
 SG_ StatusUWBRangingFBD_HL_FirstPath : 56|8@1+ (0.5,-127) [-127|-1] "dB" FBD_HM,FBD_HR,FBD_MM,FBD_Miko,FBD_Trunk,FBD_VL,FBD_VM,FBD_VR,IPB_App1
 SG_ StatusUWBRangingFBD_HL_AngleOfAr : 64|8@1+ (1.0,-90) [-90|90] "°" FBD_HM,FBD_HR,FBD_MM,FBD_Miko,FBD_Trunk,FBD_VL,FBD_VM,FBD_VR,IPB_App1
 SG_ StatusUWBRangingFBD_HL_PhaseDiff : 72|8@1+ (1.0,-90) [-90|90] "°" FBD_HM,FBD_HR,FBD_MM,FBD_Miko,FBD_Trunk,FBD_VL,FBD_VM,FBD_VR,IPB_App1
 SG_ StatusUWBRangingFBD_HL_Strongest : 80|8@1+ (0.5,-127) [-127|-1] "dB" FBD_HM,FBD_HR,FBD_MM,FBD_Miko,FBD_Trunk,FBD_VL,FBD_VM,FBD_VR,IPB_App1
 SG_ StatusUWBRangingFBD_HL_BLE_RSSI : 88|8@1+ (0.5,-127) [-127|-1] "dB" FBD_HM,FBD_HR,FBD_MM,FBD_Miko,FBD_Trunk,FBD_VL,FBD_VM,FBD_VR,IPB_App1
 SG_ StatusUWBRangingFBD_HL_Stronge_2 : 96|8@1+ (0.5,0) [0|125] "ns" FBD_HM,FBD_HR,FBD_MM,FBD_Miko,FBD_Trunk,FBD_VL,FBD_VM,FBD_VR,IPB_App1
 SG_ StatusUWBRangingFBD_HL_PDoA_SNR : 104|8@1+ (0.5,0) [0|126] "dB" FBD_HM,FBD_HR,FBD_MM,FBD_Miko,FBD_Trunk,FBD_VL,FBD_VM,FBD_VR,IPB_App1
 SG_ StatusUWBRangingFBD_HL_DutyCycle : 112|8@1+ (1.0,0) [0|100] "%" FBD_HM,FBD_HR,FBD_MM,FBD_Miko,FBD_Trunk,FBD_VL,FBD_VM,FBD_VR,IPB_App1
 SG_ StatusUWBRangingFBD_HL_FinalData : 120|4@1+ (1.0,0) [0|12] "" FBD_HM,FBD_HR,FBD_MM,FBD_Miko,FBD_Trunk,FBD_VL,FBD_VM,FBD_VR,IPB_App1
 SG_ StatusUWBRangingFBD_HL_Antenna : 124|4@1+ (1,0) [0|0] "" FBD_HM,FBD_HR,FBD_MM,FBD_Miko,FBD_Trunk,FBD_VL,FBD_VM,FBD_VR,IPB_App1
 SG_ StatusUWBRangingFBD_HL_Status1 : 128|8@1+ (1,0) [0|0] "" FBD_HM,FBD_HR,FBD_MM,FBD_Miko,FBD_Trunk,FBD_VL,FBD_VM,FBD_VR,IPB_App1
 SG_ StatusUWBRangingFBD_HL_Status2 : 136|8@1+ (1.0,0) [0|252] "" FBD_HM,FBD_HR,FBD_MM,FBD_Miko,FBD_Trunk,FBD_VL,FBD_VM,FBD_VR,IPB_App1
 SG_ StatusUWBRangingFBD_HL_Status3 : 144|8@1+ (1.0,0) [0|252] "" FBD_HM,FBD_HR,FBD_MM,FBD_Miko,FBD_Trunk,FBD_VL,FBD_VM,FBD_VR,IPB_App1
 SG_ StatusUWBRangingFBD_HL_Status4 : 152|8@1+ (1.0,0) [0|252] "" FBD_HM,FBD_HR,FBD_MM,FBD_Miko,FBD_Trunk,FBD_VL,FBD_VM,FBD_VR,IPB_App1
 SG_ StatusUWBRangingFBD_HL_IV00 : 160|8@1+ (1.0,0) [0|255] "" FBD_HM,FBD_HR,FBD_MM,FBD_Miko,FBD_Trunk,FBD_VL,FBD_VM,FBD_VR,IPB_App1
 SG_ StatusUWBRangingFBD_HL_IV01 : 168|8@1+ (1.0,0) [0|255] "" FBD_HM,FBD_HR,FBD_MM,FBD_Miko,FBD_Trunk,FBD_VL,FBD_VM,FBD_VR,IPB_App1
 SG_ StatusUWBRangingFBD_HL_IV02 : 176|8@1+ (1.0,0) [0|255] "" FBD_HM,FBD_HR,FBD_MM,FBD_Miko,FBD_Trunk,FBD_VL,FBD_VM,FBD_VR,IPB_App1
 SG_ StatusUWBRangingFBD_HL_IV03 : 184|8@1+ (1.0,0) [0|255] "" FBD_HM,FBD_HR,FBD_MM,FBD_Miko,FBD_Trunk,FBD_VL,FBD_VM,FBD_VR,IPB_App1
 SG_ StatusUWBRangingFBD_HL_Sign00 : 192|8@1+ (1.0,0) [0|255] "" FBD_HM,FBD_HR,FBD_MM,FBD_Miko,FBD_Trunk,FBD_VL,FBD_VM,FBD_VR,IPB_App1
 SG_ StatusUWBRangingFBD_HL_Sign01 : 200|8@1+ (1.0,0) [0|255] "" FBD_HM,FBD_HR,FBD_MM,FBD_Miko,FBD_Trunk,FBD_VL,FBD_VM,FBD_VR,IPB_App1
 SG_ StatusUWBRangingFBD_HL_Sign02 : 208|8@1+ (1.0,0) [0|255] "" FBD_HM,FBD_HR,FBD_MM,FBD_Miko,FBD_Trunk,FBD_VL,FBD_VM,FBD_VR,IPB_App1
 SG_ StatusUWBRangingFBD_HL_Sign03 : 216|8@1+ (1.0,0) [0|255] "" FBD_HM,FBD_HR,FBD_MM,FBD_Miko,FBD_Trunk,FBD_VL,FBD_VM,FBD_VR,IPB_App1
 SG_ StatusUWBRangingFBD_HL_Sign04 : 224|8@1+ (1.0,0) [0|255] "" FBD_HM,FBD_HR,FBD_MM,FBD_Miko,FBD_Trunk,FBD_VL,FBD_VM,FBD_VR,IPB_App1
 SG_ StatusUWBRangingFBD_HL_Sign05 : 232|8@1+ (1.0,0) [0|255] "" FBD_HM,FBD_HR,FBD_MM,FBD_Miko,FBD_Trunk,FBD_VL,FBD_VM,FBD_VR,IPB_App1
 SG_ StatusUWBRangingFBD_HL_Sign06 : 240|8@1+ (1.0,0) [0|255] "" FBD_HM,FBD_HR,FBD_MM,FBD_Miko,FBD_Trunk,FBD_VL,FBD_VM,FBD_VR,IPB_App1
 SG_ StatusUWBRangingFBD_HL_Sign07 : 248|8@1+ (1.0,0) [0|255] "" FBD_HM,FBD_HR,FBD_MM,FBD_Miko,FBD_Trunk,FBD_VL,FBD_VM,FBD_VR,IPB_App1

BO_ 431 StatusUWBRangingFBD_HM: 32 FBD_HM
 SG_ StatusUWBRangingFBD_HM_SessionID : 0|8@1+ (1.0,0) [0|252] "" FBD_HL,FBD_HR,FBD_MM,FBD_Miko,FBD_Trunk,FBD_VL,FBD_VM,FBD_VR,IPB_App1
 SG_ StatusUWBRangingFBD_HM_TimeOfFli : 8|16@1+ (15.65,0) [0|1000000] "ps" FBD_HL,FBD_HR,FBD_MM,FBD_Miko,FBD_Trunk,FBD_VL,FBD_VM,FBD_VR,IPB_App1
 SG_ StatusUWBRangingFBD_HM_RangingBl : 24|16@1+ (1.0,0) [0|65532] "" FBD_HL,FBD_HR,FBD_MM,FBD_Miko,FBD_Trunk,FBD_VL,FBD_VM,FBD_VR,IPB_App1
 SG_ StatusUWBRangingFBD_HM_RangingRo : 40|8@1+ (1.0,0) [0|252] "" FBD_HL,FBD_HR,FBD_MM,FBD_Miko,FBD_Trunk,FBD_VL,FBD_VM,FBD_VR,IPB_App1
 SG_ StatusUWBRangingFBD_HM_OverallRe : 48|8@1+ (0.5,-127) [-127|-1] "dB" FBD_HL,FBD_HR,FBD_MM,FBD_Miko,FBD_Trunk,FBD_VL,FBD_VM,FBD_VR,IPB_App1
 SG_ StatusUWBRangingFBD_HM_FirstPath : 56|8@1+ (0.5,-127) [-127|-1] "dB" FBD_HL,FBD_HR,FBD_MM,FBD_Miko,FBD_Trunk,FBD_VL,FBD_VM,FBD_VR,IPB_App1
 SG_ StatusUWBRangingFBD_HM_AngleOfAr : 64|8@1+ (1.0,-90) [-90|90] "°" FBD_HL,FBD_HR,FBD_MM,FBD_Miko,FBD_Trunk,FBD_VL,FBD_VM,FBD_VR,IPB_App1
 SG_ StatusUWBRangingFBD_HM_PhaseDiff : 72|8@1+ (1.0,-90) [-90|90] "°" FBD_HL,FBD_HR,FBD_MM,FBD_Miko,FBD_Trunk,FBD_VL,FBD_VM,FBD_VR,IPB_App1
 SG_ StatusUWBRangingFBD_HM_Strongest : 80|8@1+ (0.5,-127) [-127|-1] "dB" FBD_HL,FBD_HR,FBD_MM,FBD_Miko,FBD_Trunk,FBD_VL,FBD_VM,FBD_VR,IPB_App1
 SG_ StatusUWBRangingFBD_HM_BLE_RSSI : 88|8@1+ (0.5,-127) [-127|-1] "dB" FBD_HL,FBD_HR,FBD_MM,FBD_Miko,FBD_Trunk,FBD_VL,FBD_VM,FBD_VR,IPB_App1
 SG_ StatusUWBRangingFBD_HM_Stronge_2 : 96|8@1+ (0.5,0) [0|125] "ns" FBD_HL,FBD_HR,FBD_MM,FBD_Miko,FBD_Trunk,FBD_VL,FBD_VM,FBD_VR,IPB_App1
 SG_ StatusUWBRangingFBD_HM_PDoA_SNR : 104|8@1+ (0.5,0) [0|126] "dB" FBD_HL,FBD_HR,FBD_MM,FBD_Miko,FBD_Trunk,FBD_VL,FBD_VM,FBD_VR,IPB_App1
 SG_ StatusUWBRangingFBD_HM_DutyCycle : 112|8@1+ (1.0,0) [0|100] "%" FBD_HL,FBD_HR,FBD_MM,FBD_Miko,FBD_Trunk,FBD_VL,FBD_VM,FBD_VR,IPB_App1
 SG_ StatusUWBRangingFBD_HM_FinalData : 120|4@1+ (1.0,0) [0|12] "" FBD_HL,FBD_HR,FBD_MM,FBD_Miko,FBD_Trunk,FBD_VL,FBD_VM,FBD_VR,IPB_App1
 SG_ StatusUWBRangingFBD_HM_Antenna : 124|4@1+ (1,0) [0|0] "" FBD_HL,FBD_HR,FBD_MM,FBD_Miko,FBD_Trunk,FBD_VL,FBD_VM,FBD_VR,IPB_App1
 SG_ StatusUWBRangingFBD_HM_Status1 : 128|8@1+ (1,0) [0|0] "" FBD_HL,FBD_HR,FBD_MM,FBD_Miko,FBD_Trunk,FBD_VL,FBD_VM,FBD_VR,IPB_App1
 SG_ StatusUWBRangingFBD_HM_Status2 : 136|8@1+ (1.0,0) [0|252] "" FBD_HL,FBD_HR,FBD_MM,FBD_Miko,FBD_Trunk,FBD_VL,FBD_VM,FBD_VR,IPB_App1
 SG_ StatusUWBRangingFBD_HM_Status3 : 144|8@1+ (1.0,0) [0|252] "" FBD_HL,FBD_HR,FBD_MM,FBD_Miko,FBD_Trunk,FBD_VL,FBD_VM,FBD_VR,IPB_App1
 SG_ StatusUWBRangingFBD_HM_Status4 : 152|8@1+ (1.0,0) [0|252] "" FBD_HL,FBD_HR,FBD_MM,FBD_Miko,FBD_Trunk,FBD_VL,FBD_VM,FBD_VR,IPB_App1
 SG_ StatusUWBRangingFBD_HM_IV00 : 160|8@1+ (1.0,0) [0|255] "" FBD_HL,FBD_HR,FBD_MM,FBD_Miko,FBD_Trunk,FBD_VL,FBD_VM,FBD_VR,IPB_App1
 SG_ StatusUWBRangingFBD_HM_IV01 : 168|8@1+ (1.0,0) [0|255] "" FBD_HL,FBD_HR,FBD_MM,FBD_Miko,FBD_Trunk,FBD_VL,FBD_VM,FBD_VR,IPB_App1
 SG_ StatusUWBRangingFBD_HM_IV02 : 176|8@1+ (1.0,0) [0|255] "" FBD_HL,FBD_HR,FBD_MM,FBD_Miko,FBD_Trunk,FBD_VL,FBD_VM,FBD_VR,IPB_App1
 SG_ StatusUWBRangingFBD_HM_IV03 : 184|8@1+ (1.0,0) [0|255] "" FBD_HL,FBD_HR,FBD_MM,FBD_Miko,FBD_Trunk,FBD_VL,FBD_VM,FBD_VR,IPB_App1
 SG_ StatusUWBRangingFBD_HM_Sign00 : 192|8@1+ (1.0,0) [0|255] "" FBD_HL,FBD_HR,FBD_MM,FBD_Miko,FBD_Trunk,FBD_VL,FBD_VM,FBD_VR,IPB_App1
 SG_ StatusUWBRangingFBD_HM_Sign01 : 200|8@1+ (1.0,0) [0|255] "" FBD_HL,FBD_HR,FBD_MM,FBD_Miko,FBD_Trunk,FBD_VL,FBD_VM,FBD_VR,IPB_App1
 SG_ StatusUWBRangingFBD_HM_Sign02 : 208|8@1+ (1.0,0) [0|255] "" FBD_HL,FBD_HR,FBD_MM,FBD_Miko,FBD_Trunk,FBD_VL,FBD_VM,FBD_VR,IPB_App1
 SG_ StatusUWBRangingFBD_HM_Sign03 : 216|8@1+ (1.0,0) [0|255] "" FBD_HL,FBD_HR,FBD_MM,FBD_Miko,FBD_Trunk,FBD_VL,FBD_VM,FBD_VR,IPB_App1
 SG_ StatusUWBRangingFBD_HM_Sign04 : 224|8@1+ (1.0,0) [0|255] "" FBD_HL,FBD_HR,FBD_MM,FBD_Miko,FBD_Trunk,FBD_VL,FBD_VM,FBD_VR,IPB_App1
 SG_ StatusUWBRangingFBD_HM_Sign05 : 232|8@1+ (1.0,0) [0|255] "" FBD_HL,FBD_HR,FBD_MM,FBD_Miko,FBD_Trunk,FBD_VL,FBD_VM,FBD_VR,IPB_App1
 SG_ StatusUWBRangingFBD_HM_Sign06 : 240|8@1+ (1.0,0) [0|255] "" FBD_HL,FBD_HR,FBD_MM,FBD_Miko,FBD_Trunk,FBD_VL,FBD_VM,FBD_VR,IPB_App1
 SG_ StatusUWBRangingFBD_HM_Sign07 : 248|8@1+ (1.0,0) [0|255] "" FBD_HL,FBD_HR,FBD_MM,FBD_Miko,FBD_Trunk,FBD_VL,FBD_VM,FBD_VR,IPB_App1

BO_ 437 StatusUWBRangingFBD_HR: 32 FBD_HR
 SG_ StatusUWBRangingFBD_HR_SessionID : 0|8@1+ (1.0,0) [0|252] "" FBD_HL,FBD_HM,FBD_MM,FBD_Miko,FBD_Trunk,FBD_VL,FBD_VM,FBD_VR,IPB_App1
 SG_ StatusUWBRangingFBD_HR_TimeOfFli : 8|16@1+ (15.65,0) [0|1000000] "ps" FBD_HL,FBD_HM,FBD_MM,FBD_Miko,FBD_Trunk,FBD_VL,FBD_VM,FBD_VR,IPB_App1
 SG_ StatusUWBRangingFBD_HR_RangingBl : 24|16@1+ (1.0,0) [0|65532] "" FBD_HL,FBD_HM,FBD_MM,FBD_Miko,FBD_Trunk,FBD_VL,FBD_VM,FBD_VR,IPB_App1
 SG_ StatusUWBRangingFBD_HR_RangingRo : 40|8@1+ (1.0,0) [0|252] "" FBD_HL,FBD_HM,FBD_MM,FBD_Miko,FBD_Trunk,FBD_VL,FBD_VM,FBD_VR,IPB_App1
 SG_ StatusUWBRangingFBD_HR_OverallRe : 48|8@1+ (0.5,-127) [-127|-1] "dB" FBD_HL,FBD_HM,FBD_MM,FBD_Miko,FBD_Trunk,FBD_VL,FBD_VM,FBD_VR,IPB_App1
 SG_ StatusUWBRangingFBD_HR_FirstPath : 56|8@1+ (0.5,-127) [-127|-1] "dB" FBD_HL,FBD_HM,FBD_MM,FBD_Miko,FBD_Trunk,FBD_VL,FBD_VM,FBD_VR,IPB_App1
 SG_ StatusUWBRangingFBD_HR_AngleOfAr : 64|8@1+ (1.0,-90) [-90|90] "°" FBD_HL,FBD_HM,FBD_MM,FBD_Miko,FBD_Trunk,FBD_VL,FBD_VM,FBD_VR,IPB_App1
 SG_ StatusUWBRangingFBD_HR_PhaseDiff : 72|8@1+ (1.0,-90) [-90|90] "°" FBD_HL,FBD_HM,FBD_MM,FBD_Miko,FBD_Trunk,FBD_VL,FBD_VM,FBD_VR,IPB_App1
 SG_ StatusUWBRangingFBD_HR_Strongest : 80|8@1+ (0.5,-127) [-127|-1] "dB" FBD_HL,FBD_HM,FBD_MM,FBD_Miko,FBD_Trunk,FBD_VL,FBD_VM,FBD_VR,IPB_App1
 SG_ StatusUWBRangingFBD_HR_BLE_RSSI : 88|8@1+ (0.5,-127) [-127|-1] "dB" FBD_HL,FBD_HM,FBD_MM,FBD_Miko,FBD_Trunk,FBD_VL,FBD_VM,FBD_VR,IPB_App1
 SG_ StatusUWBRangingFBD_HR_Stronge_2 : 96|8@1+ (0.5,0) [0|125] "ns" FBD_HL,FBD_HM,FBD_MM,FBD_Miko,FBD_Trunk,FBD_VL,FBD_VM,FBD_VR,IPB_App1
 SG_ StatusUWBRangingFBD_HR_PDoA_SNR : 104|8@1+ (0.5,0) [0|126] "dB" FBD_HL,FBD_HM,FBD_MM,FBD_Miko,FBD_Trunk,FBD_VL,FBD_VM,FBD_VR,IPB_App1
 SG_ StatusUWBRangingFBD_HR_DutyCycle : 112|8@1+ (1.0,0) [0|100] "%" FBD_HL,FBD_HM,FBD_MM,FBD_Miko,FBD_Trunk,FBD_VL,FBD_VM,FBD_VR,IPB_App1
 SG_ StatusUWBRangingFBD_HR_FinalData : 120|4@1+ (1.0,0) [0|12] "" FBD_HL,FBD_HM,FBD_MM,FBD_Miko,FBD_Trunk,FBD_VL,FBD_VM,FBD_VR,IPB_App1
 SG_ StatusUWBRangingFBD_HR_Antenna : 124|4@1+ (1,0) [0|0] "" FBD_HL,FBD_HM,FBD_MM,FBD_Miko,FBD_Trunk,FBD_VL,FBD_VM,FBD_VR,IPB_App1
 SG_ StatusUWBRangingFBD_HR_Status1 : 128|8@1+ (1,0) [0|0] "" FBD_HL,FBD_HM,FBD_MM,FBD_Miko,FBD_Trunk,FBD_VL,FBD_VM,FBD_VR,IPB_App1
 SG_ StatusUWBRangingFBD_HR_Status2 : 136|8@1+ (1.0,0) [0|252] "" FBD_HL,FBD_HM,FBD_MM,FBD_Miko,FBD_Trunk,FBD_VL,FBD_VM,FBD_VR,IPB_App1
 SG_ StatusUWBRangingFBD_HR_Status3 : 144|8@1+ (1.0,0) [0|252] "" FBD_HL,FBD_HM,FBD_MM,FBD_Miko,FBD_Trunk,FBD_VL,FBD_VM,FBD_VR,IPB_App1
 SG_ StatusUWBRangingFBD_HR_Status4 : 152|8@1+ (1.0,0) [0|252] "" FBD_HL,FBD_HM,FBD_MM,FBD_Miko,FBD_Trunk,FBD_VL,FBD_VM,FBD_VR,IPB_App1
 SG_ StatusUWBRangingFBD_HR_IV00 : 160|8@1+ (1.0,0) [0|255] "" FBD_HL,FBD_HM,FBD_MM,FBD_Miko,FBD_Trunk,FBD_VL,FBD_VM,FBD_VR,IPB_App1
 SG_ StatusUWBRangingFBD_HR_IV01 : 168|8@1+ (1.0,0) [0|255] "" FBD_HL,FBD_HM,FBD_MM,FBD_Miko,FBD_Trunk,FBD_VL,FBD_VM,FBD_VR,IPB_App1
 SG_ StatusUWBRangingFBD_HR_IV02 : 176|8@1+ (1.0,0) [0|255] "" FBD_HL,FBD_HM,FBD_MM,FBD_Miko,FBD_Trunk,FBD_VL,FBD_VM,FBD_VR,IPB_App1
 SG_ StatusUWBRangingFBD_HR_IV03 : 184|8@1+ (1.0,0) [0|255] "" FBD_HL,FBD_HM,FBD_MM,FBD_Miko,FBD_Trunk,FBD_VL,FBD_VM,FBD_VR,IPB_App1
 SG_ StatusUWBRangingFBD_HR_Sign00 : 192|8@1+ (1.0,0) [0|255] "" FBD_HL,FBD_HM,FBD_MM,FBD_Miko,FBD_Trunk,FBD_VL,FBD_VM,FBD_VR,IPB_App1
 SG_ StatusUWBRangingFBD_HR_Sign01 : 200|8@1+ (1.0,0) [0|255] "" FBD_HL,FBD_HM,FBD_MM,FBD_Miko,FBD_Trunk,FBD_VL,FBD_VM,FBD_VR,IPB_App1
 SG_ StatusUWBRangingFBD_HR_Sign02 : 208|8@1+ (1.0,0) [0|255] "" FBD_HL,FBD_HM,FBD_MM,FBD_Miko,FBD_Trunk,FBD_VL,FBD_VM,FBD_VR,IPB_App1
 SG_ StatusUWBRangingFBD_HR_Sign03 : 216|8@1+ (1.0,0) [0|255] "" FBD_HL,FBD_HM,FBD_MM,FBD_Miko,FBD_Trunk,FBD_VL,FBD_VM,FBD_VR,IPB_App1
 SG_ StatusUWBRangingFBD_HR_Sign04 : 224|8@1+ (1.0,0) [0|255] "" FBD_HL,FBD_HM,FBD_MM,FBD_Miko,FBD_Trunk,FBD_VL,FBD_VM,FBD_VR,IPB_App1
 SG_ StatusUWBRangingFBD_HR_Sign05 : 232|8@1+ (1.0,0) [0|255] "" FBD_HL,FBD_HM,FBD_MM,FBD_Miko,FBD_Trunk,FBD_VL,FBD_VM,FBD_VR,IPB_App1
 SG_ StatusUWBRangingFBD_HR_Sign06 : 240|8@1+ (1.0,0) [0|255] "" FBD_HL,FBD_HM,FBD_MM,FBD_Miko,FBD_Trunk,FBD_VL,FBD_VM,FBD_VR,IPB_App1
 SG_ StatusUWBRangingFBD_HR_Sign07 : 248|8@1+ (1.0,0) [0|255] "" FBD_HL,FBD_HM,FBD_MM,FBD_Miko,FBD_Trunk,FBD_VL,FBD_VM,FBD_VR,IPB_App1

BO_ 432 StatusUWBRangingFBD_Miko: 32 FBD_Miko
 SG_ StatusUWBRangingFBD_Miko_Session : 0|8@1+ (1.0,0) [0|252] "" FBD_HL,FBD_HM,FBD_HR,FBD_MM,FBD_Trunk,FBD_VL,FBD_VM,FBD_VR,IPB_App1
 SG_ StatusUWBRangingFBD_Miko_TimeOfF : 8|16@1+ (15.65,0) [0|1000000] "ps" FBD_HL,FBD_HM,FBD_HR,FBD_MM,FBD_Trunk,FBD_VL,FBD_VM,FBD_VR,IPB_App1
 SG_ StatusUWBRangingFBD_Miko_Ranging : 24|16@1+ (1.0,0) [0|65532] "" FBD_HL,FBD_HM,FBD_HR,FBD_MM,FBD_Trunk,FBD_VL,FBD_VM,FBD_VR,IPB_App1
 SG_ StatusUWBRangingFBD_Miko_Rangi_2 : 40|8@1+ (1.0,0) [0|252] "" FBD_HL,FBD_HM,FBD_HR,FBD_MM,FBD_Trunk,FBD_VL,FBD_VM,FBD_VR,IPB_App1
 SG_ StatusUWBRangingFBD_Miko_Overall : 48|8@1+ (0.5,-127) [-127|-1] "dB" FBD_HL,FBD_HM,FBD_HR,FBD_MM,FBD_Trunk,FBD_VL,FBD_VM,FBD_VR,IPB_App1
 SG_ StatusUWBRangingFBD_Miko_FirstPa : 56|8@1+ (0.5,-127) [-127|-1] "dB" FBD_HL,FBD_HM,FBD_HR,FBD_MM,FBD_Trunk,FBD_VL,FBD_VM,FBD_VR,IPB_App1
 SG_ StatusUWBRangingFBD_Miko_AngleOf : 64|8@1+ (1.0,-90) [-90|90] "°" FBD_HL,FBD_HM,FBD_HR,FBD_MM,FBD_Trunk,FBD_VL,FBD_VM,FBD_VR,IPB_App1
 SG_ StatusUWBRangingFBD_Miko_PhaseDi : 72|8@1+ (1.0,-90) [-90|90] "°" FBD_HL,FBD_HM,FBD_HR,FBD_MM,FBD_Trunk,FBD_VL,FBD_VM,FBD_VR,IPB_App1
 SG_ StatusUWBRangingFBD_Miko_Stronge : 80|8@1+ (0.5,-127) [-127|-1] "dB" FBD_HL,FBD_HM,FBD_HR,FBD_MM,FBD_Trunk,FBD_VL,FBD_VM,FBD_VR,IPB_App1
 SG_ StatusUWBRangingFBD_Miko_BLE_RSS : 88|8@1+ (0.5,-127) [-127|-1] "dB" FBD_HL,FBD_HM,FBD_HR,FBD_MM,FBD_Trunk,FBD_VL,FBD_VM,FBD_VR,IPB_App1
 SG_ StatusUWBRangingFBD_Miko_Stron_2 : 96|8@1+ (0.5,0) [0|125] "ns" FBD_HL,FBD_HM,FBD_HR,FBD_MM,FBD_Trunk,FBD_VL,FBD_VM,FBD_VR,IPB_App1
 SG_ StatusUWBRangingFBD_Miko_PDoA_SN : 104|8@1+ (0.5,0) [0|126] "dB" FBD_HL,FBD_HM,FBD_HR,FBD_MM,FBD_Trunk,FBD_VL,FBD_VM,FBD_VR,IPB_App1
 SG_ StatusUWBRangingFBD_Miko_DutyCyc : 112|8@1+ (1.0,0) [0|100] "%" FBD_HL,FBD_HM,FBD_HR,FBD_MM,FBD_Trunk,FBD_VL,FBD_VM,FBD_VR,IPB_App1
 SG_ StatusUWBRangingFBD_Miko_FinalDa : 120|4@1+ (1.0,0) [0|12] "" FBD_HL,FBD_HM,FBD_HR,FBD_MM,FBD_Trunk,FBD_VL,FBD_VM,FBD_VR,IPB_App1
 SG_ StatusUWBRangingFBD_Miko_Antenna : 124|4@1+ (1,0) [0|0] "" FBD_HL,FBD_HM,FBD_HR,FBD_MM,FBD_Trunk,FBD_VL,FBD_VM,FBD_VR,IPB_App1
 SG_ StatusUWBRangingFBD_Miko_Status1 : 128|8@1+ (1,0) [0|0] "" FBD_HL,FBD_HM,FBD_HR,FBD_MM,FBD_Trunk,FBD_VL,FBD_VM,FBD_VR,IPB_App1
 SG_ StatusUWBRangingFBD_Miko_Status2 : 136|8@1+ (1.0,0) [0|252] "" FBD_HL,FBD_HM,FBD_HR,FBD_MM,FBD_Trunk,FBD_VL,FBD_VM,FBD_VR,IPB_App1
 SG_ StatusUWBRangingFBD_Miko_Status3 : 144|8@1+ (1.0,0) [0|252] "" FBD_HL,FBD_HM,FBD_HR,FBD_MM,FBD_Trunk,FBD_VL,FBD_VM,FBD_VR,IPB_App1
 SG_ StatusUWBRangingFBD_Miko_Status4 : 152|8@1+ (1.0,0) [0|252] "" FBD_HL,FBD_HM,FBD_HR,FBD_MM,FBD_Trunk,FBD_VL,FBD_VM,FBD_VR,IPB_App1
 SG_ StatusUWBRangingFBD_Miko_IV00 : 160|8@1+ (1.0,0) [0|255] "" FBD_HL,FBD_HM,FBD_HR,FBD_MM,FBD_Trunk,FBD_VL,FBD_VM,FBD_VR,IPB_App1
 SG_ StatusUWBRangingFBD_Miko_IV01 : 168|8@1+ (1.0,0) [0|255] "" FBD_HL,FBD_HM,FBD_HR,FBD_MM,FBD_Trunk,FBD_VL,FBD_VM,FBD_VR,IPB_App1
 SG_ StatusUWBRangingFBD_Miko_IV02 : 176|8@1+ (1.0,0) [0|255] "" FBD_HL,FBD_HM,FBD_HR,FBD_MM,FBD_Trunk,FBD_VL,FBD_VM,FBD_VR,IPB_App1
 SG_ StatusUWBRangingFBD_Miko_IV03 : 184|8@1+ (1.0,0) [0|255] "" FBD_HL,FBD_HM,FBD_HR,FBD_MM,FBD_Trunk,FBD_VL,FBD_VM,FBD_VR,IPB_App1
 SG_ StatusUWBRangingFBD_Miko_Sign00 : 192|8@1+ (1.0,0) [0|255] "" FBD_HL,FBD_HM,FBD_HR,FBD_MM,FBD_Trunk,FBD_VL,FBD_VM,FBD_VR,IPB_App1
 SG_ StatusUWBRangingFBD_Miko_Sign01 : 200|8@1+ (1.0,0) [0|255] "" FBD_HL,FBD_HM,FBD_HR,FBD_MM,FBD_Trunk,FBD_VL,FBD_VM,FBD_VR,IPB_App1
 SG_ StatusUWBRangingFBD_Miko_Sign02 : 208|8@1+ (1.0,0) [0|255] "" FBD_HL,FBD_HM,FBD_HR,FBD_MM,FBD_Trunk,FBD_VL,FBD_VM,FBD_VR,IPB_App1
 SG_ StatusUWBRangingFBD_Miko_Sign03 : 216|8@1+ (1.0,0) [0|255] "" FBD_HL,FBD_HM,FBD_HR,FBD_MM,FBD_Trunk,FBD_VL,FBD_VM,FBD_VR,IPB_App1
 SG_ StatusUWBRangingFBD_Miko_Sign04 : 224|8@1+ (1.0,0) [0|255] "" FBD_HL,FBD_HM,FBD_HR,FBD_MM,FBD_Trunk,FBD_VL,FBD_VM,FBD_VR,IPB_App1
 SG_ StatusUWBRangingFBD_Miko_Sign05 : 232|8@1+ (1.0,0) [0|255] "" FBD_HL,FBD_HM,FBD_HR,FBD_MM,FBD_Trunk,FBD_VL,FBD_VM,FBD_VR,IPB_App1
 SG_ StatusUWBRangingFBD_Miko_Sign06 : 240|8@1+ (1.0,0) [0|255] "" FBD_HL,FBD_HM,FBD_HR,FBD_MM,FBD_Trunk,FBD_VL,FBD_VM,FBD_VR,IPB_App1
 SG_ StatusUWBRangingFBD_Miko_Sign07 : 248|8@1+ (1.0,0) [0|255] "" FBD_HL,FBD_HM,FBD_HR,FBD_MM,FBD_Trunk,FBD_VL,FBD_VM,FBD_VR,IPB_App1

BO_ 443 StatusUWBRangingFBD_MM: 32 FBD_MM
 SG_ StatusUWBRangingFBD_MM_SessionID : 0|8@1+ (1.0,0) [0|252] "" FBD_HL,FBD_HM,FBD_HR,FBD_Miko,FBD_Trunk,FBD_VL,FBD_VM,FBD_VR,IPB_App1
 SG_ StatusUWBRangingFBD_MM_TimeOfFli : 8|16@1+ (15.65,0) [0|1000000] "ps" FBD_HL,FBD_HM,FBD_HR,FBD_Miko,FBD_Trunk,FBD_VL,FBD_VM,FBD_VR,IPB_App1
 SG_ StatusUWBRangingFBD_MM_RangingBl : 24|16@1+ (1.0,0) [0|65532] "" FBD_HL,FBD_HM,FBD_HR,FBD_Miko,FBD_Trunk,FBD_VL,FBD_VM,FBD_VR,IPB_App1
 SG_ StatusUWBRangingFBD_MM_RangingRo : 40|8@1+ (1.0,0) [0|252] "" FBD_HL,FBD_HM,FBD_HR,FBD_Miko,FBD_Trunk,FBD_VL,FBD_VM,FBD_VR,IPB_App1
 SG_ StatusUWBRangingFBD_MM_OverallRe : 48|8@1+ (0.5,-127) [-127|-1] "dB" FBD_HL,FBD_HM,FBD_HR,FBD_Miko,FBD_Trunk,FBD_VL,FBD_VM,FBD_VR,IPB_App1
 SG_ StatusUWBRangingFBD_MM_FirstPath : 56|8@1+ (0.5,-127) [-127|-1] "dB" FBD_HL,FBD_HM,FBD_HR,FBD_Miko,FBD_Trunk,FBD_VL,FBD_VM,FBD_VR,IPB_App1
 SG_ StatusUWBRangingFBD_MM_AngleOfAr : 64|8@1+ (1.0,-90) [-90|90] "°" FBD_HL,FBD_HM,FBD_HR,FBD_Miko,FBD_Trunk,FBD_VL,FBD_VM,FBD_VR,IPB_App1
 SG_ StatusUWBRangingFBD_MM_PhaseDiff : 72|8@1+ (1.0,-90) [-90|90] "°" FBD_HL,FBD_HM,FBD_HR,FBD_Miko,FBD_Trunk,FBD_VL,FBD_VM,FBD_VR,IPB_App1
 SG_ StatusUWBRangingFBD_MM_Strongest : 80|8@1+ (0.5,-127) [-127|-1] "dB" FBD_HL,FBD_HM,FBD_HR,FBD_Miko,FBD_Trunk,FBD_VL,FBD_VM,FBD_VR,IPB_App1
 SG_ StatusUWBRangingFBD_MM_BLE_RSSI : 88|8@1+ (0.5,-127) [-127|-1] "dB" FBD_HL,FBD_HM,FBD_HR,FBD_Miko,FBD_Trunk,FBD_VL,FBD_VM,FBD_VR,IPB_App1
 SG_ StatusUWBRangingFBD_MM_Stronge_2 : 96|8@1+ (0.5,0) [0|125] "ns" FBD_HL,FBD_HM,FBD_HR,FBD_Miko,FBD_Trunk,FBD_VL,FBD_VM,FBD_VR,IPB_App1
 SG_ StatusUWBRangingFBD_MM_PDoA_SNR : 104|8@1+ (0.5,0) [0|126] "dB" FBD_HL,FBD_HM,FBD_HR,FBD_Miko,FBD_Trunk,FBD_VL,FBD_VM,FBD_VR,IPB_App1
 SG_ StatusUWBRangingFBD_MM_DutyCycle : 112|8@1+ (1.0,0) [0|100] "%" FBD_HL,FBD_HM,FBD_HR,FBD_Miko,FBD_Trunk,FBD_VL,FBD_VM,FBD_VR,IPB_App1
 SG_ StatusUWBRangingFBD_MM_FinalData : 120|4@1+ (1.0,0) [0|12] "" FBD_HL,FBD_HM,FBD_HR,FBD_Miko,FBD_Trunk,FBD_VL,FBD_VM,FBD_VR,IPB_App1
 SG_ StatusUWBRangingFBD_MM_Antenna : 124|4@1+ (1,0) [0|0] "" FBD_HL,FBD_HM,FBD_HR,FBD_Miko,FBD_Trunk,FBD_VL,FBD_VM,FBD_VR,IPB_App1
 SG_ StatusUWBRangingFBD_MM_Status1 : 128|8@1+ (1,0) [0|0] "" FBD_HL,FBD_HM,FBD_HR,FBD_Miko,FBD_Trunk,FBD_VL,FBD_VM,FBD_VR,IPB_App1
 SG_ StatusUWBRangingFBD_MM_Status2 : 136|8@1+ (1.0,0) [0|252] "" FBD_HL,FBD_HM,FBD_HR,FBD_Miko,FBD_Trunk,FBD_VL,FBD_VM,FBD_VR,IPB_App1
 SG_ StatusUWBRangingFBD_MM_Status3 : 144|8@1+ (1.0,0) [0|252] "" FBD_HL,FBD_HM,FBD_HR,FBD_Miko,FBD_Trunk,FBD_VL,FBD_VM,FBD_VR,IPB_App1
 SG_ StatusUWBRangingFBD_MM_Status4 : 152|8@1+ (1.0,0) [0|252] "" FBD_HL,FBD_HM,FBD_HR,FBD_Miko,FBD_Trunk,FBD_VL,FBD_VM,FBD_VR,IPB_App1
 SG_ StatusUWBRangingFBD_MM_IV00 : 160|8@1+ (1.0,0) [0|255] "" FBD_HL,FBD_HM,FBD_HR,FBD_Miko,FBD_Trunk,FBD_VL,FBD_VM,FBD_VR,IPB_App1
 SG_ StatusUWBRangingFBD_MM_IV01 : 168|8@1+ (1.0,0) [0|255] "" FBD_HL,FBD_HM,FBD_HR,FBD_Miko,FBD_Trunk,FBD_VL,FBD_VM,FBD_VR,IPB_App1
 SG_ StatusUWBRangingFBD_MM_IV02 : 176|8@1+ (1.0,0) [0|255] "" FBD_HL,FBD_HM,FBD_HR,FBD_Miko,FBD_Trunk,FBD_VL,FBD_VM,FBD_VR,IPB_App1
 SG_ StatusUWBRangingFBD_MM_IV03 : 184|8@1+ (1.0,0) [0|255] "" FBD_HL,FBD_HM,FBD_HR,FBD_Miko,FBD_Trunk,FBD_VL,FBD_VM,FBD_VR,IPB_App1
 SG_ StatusUWBRangingFBD_MM_Sign00 : 192|8@1+ (1.0,0) [0|255] "" FBD_HL,FBD_HM,FBD_HR,FBD_Miko,FBD_Trunk,FBD_VL,FBD_VM,FBD_VR,IPB_App1
 SG_ StatusUWBRangingFBD_MM_Sign01 : 200|8@1+ (1.0,0) [0|255] "" FBD_HL,FBD_HM,FBD_HR,FBD_Miko,FBD_Trunk,FBD_VL,FBD_VM,FBD_VR,IPB_App1
 SG_ StatusUWBRangingFBD_MM_Sign02 : 208|8@1+ (1.0,0) [0|255] "" FBD_HL,FBD_HM,FBD_HR,FBD_Miko,FBD_Trunk,FBD_VL,FBD_VM,FBD_VR,IPB_App1
 SG_ StatusUWBRangingFBD_MM_Sign03 : 216|8@1+ (1.0,0) [0|255] "" FBD_HL,FBD_HM,FBD_HR,FBD_Miko,FBD_Trunk,FBD_VL,FBD_VM,FBD_VR,IPB_App1
 SG_ StatusUWBRangingFBD_MM_Sign04 : 224|8@1+ (1.0,0) [0|255] "" FBD_HL,FBD_HM,FBD_HR,FBD_Miko,FBD_Trunk,FBD_VL,FBD_VM,FBD_VR,IPB_App1
 SG_ StatusUWBRangingFBD_MM_Sign05 : 232|8@1+ (1.0,0) [0|255] "" FBD_HL,FBD_HM,FBD_HR,FBD_Miko,FBD_Trunk,FBD_VL,FBD_VM,FBD_VR,IPB_App1
 SG_ StatusUWBRangingFBD_MM_Sign06 : 240|8@1+ (1.0,0) [0|255] "" FBD_HL,FBD_HM,FBD_HR,FBD_Miko,FBD_Trunk,FBD_VL,FBD_VM,FBD_VR,IPB_App1
 SG_ StatusUWBRangingFBD_MM_Sign07 : 248|8@1+ (1.0,0) [0|255] "" FBD_HL,FBD_HM,FBD_HR,FBD_Miko,FBD_Trunk,FBD_VL,FBD_VM,FBD_VR,IPB_App1

BO_ 438 StatusUWBRangingFBD_SML: 32 IPB_App1
 SG_ StatusUWBRangingFBD_SML_SessionI : 0|8@1+ (1.0,0) [0|252] "" FBD_HL,FBD_HM,FBD_HR,FBD_MM,FBD_Miko,FBD_Trunk,FBD_VL,FBD_VM,FBD_VR
 SG_ StatusUWBRangingFBD_SML_TimeOfFl : 8|16@1+ (15.65,0) [0|1000000] "ps" FBD_HL,FBD_HM,FBD_HR,FBD_MM,FBD_Miko,FBD_Trunk,FBD_VL,FBD_VM,FBD_VR
 SG_ StatusUWBRangingFBD_SML_RangingB : 24|16@1+ (1.0,0) [0|65532] "" FBD_HL,FBD_HM,FBD_HR,FBD_MM,FBD_Miko,FBD_Trunk,FBD_VL,FBD_VM,FBD_VR
 SG_ StatusUWBRangingFBD_SML_RangingR : 40|8@1+ (1.0,0) [0|252] "" FBD_HL,FBD_HM,FBD_HR,FBD_MM,FBD_Miko,FBD_Trunk,FBD_VL,FBD_VM,FBD_VR
 SG_ StatusUWBRangingFBD_SML_OverallR : 48|8@1+ (0.5,-127) [-127|-1] "dB" FBD_HL,FBD_HM,FBD_HR,FBD_MM,FBD_Miko,FBD_Trunk,FBD_VL,FBD_VM,FBD_VR
 SG_ StatusUWBRangingFBD_SML_FirstPat : 56|8@1+ (0.5,-127) [-127|-1] "dB" FBD_HL,FBD_HM,FBD_HR,FBD_MM,FBD_Miko,FBD_Trunk,FBD_VL,FBD_VM,FBD_VR
 SG_ StatusUWBRangingFBD_SML_AngleOfA : 64|8@1+ (1.0,-90) [-90|90] "°" FBD_HL,FBD_HM,FBD_HR,FBD_MM,FBD_Miko,FBD_Trunk,FBD_VL,FBD_VM,FBD_VR
 SG_ StatusUWBRangingFBD_SML_PhaseDif : 72|8@1+ (1.0,-90) [-90|90] "°" FBD_HL,FBD_HM,FBD_HR,FBD_MM,FBD_Miko,FBD_Trunk,FBD_VL,FBD_VM,FBD_VR
 SG_ StatusUWBRangingFBD_SML_Stronges : 80|8@1+ (0.5,-127) [-127|-1] "dB" FBD_HL,FBD_HM,FBD_HR,FBD_MM,FBD_Miko,FBD_Trunk,FBD_VL,FBD_VM,FBD_VR
 SG_ StatusUWBRangingFBD_SML_BLE_RSSI : 88|8@1+ (0.5,-127) [-127|-1] "dB" FBD_HL,FBD_HM,FBD_HR,FBD_MM,FBD_Miko,FBD_Trunk,FBD_VL,FBD_VM,FBD_VR
 SG_ StatusUWBRangingFBD_SML_Strong_2 : 96|8@1+ (0.5,0) [0|125] "ns" FBD_HL,FBD_HM,FBD_HR,FBD_MM,FBD_Miko,FBD_Trunk,FBD_VL,FBD_VM,FBD_VR
 SG_ StatusUWBRangingFBD_SML_PDoA_SNR : 104|8@1+ (0.5,0) [0|126] "dB" FBD_HL,FBD_HM,FBD_HR,FBD_MM,FBD_Miko,FBD_Trunk,FBD_VL,FBD_VM,FBD_VR
 SG_ StatusUWBRangingFBD_SML_DutyCycl : 112|8@1+ (1.0,0) [0|100] "%" FBD_HL,FBD_HM,FBD_HR,FBD_MM,FBD_Miko,FBD_Trunk,FBD_VL,FBD_VM,FBD_VR
 SG_ StatusUWBRangingFBD_SML_FinalDat : 120|4@1+ (1.0,0) [0|12] "" FBD_HL,FBD_HM,FBD_HR,FBD_MM,FBD_Miko,FBD_Trunk,FBD_VL,FBD_VM,FBD_VR
 SG_ StatusUWBRangingFBD_SML_Antenna : 124|4@1+ (1,0) [0|0] "" FBD_HL,FBD_HM,FBD_HR,FBD_MM,FBD_Miko,FBD_Trunk,FBD_VL,FBD_VM,FBD_VR
 SG_ StatusUWBRangingFBD_SML_Status1 : 128|8@1+ (1,0) [0|0] "" FBD_HL,FBD_HM,FBD_HR,FBD_MM,FBD_Miko,FBD_Trunk,FBD_VL,FBD_VM,FBD_VR
 SG_ StatusUWBRangingFBD_SML_Status2 : 136|8@1+ (1.0,0) [0|252] "" FBD_HL,FBD_HM,FBD_HR,FBD_MM,FBD_Miko,FBD_Trunk,FBD_VL,FBD_VM,FBD_VR
 SG_ StatusUWBRangingFBD_SML_Status3 : 144|8@1+ (1.0,0) [0|252] "" FBD_HL,FBD_HM,FBD_HR,FBD_MM,FBD_Miko,FBD_Trunk,FBD_VL,FBD_VM,FBD_VR
 SG_ StatusUWBRangingFBD_SML_Status4 : 152|8@1+ (1.0,0) [0|252] "" FBD_HL,FBD_HM,FBD_HR,FBD_MM,FBD_Miko,FBD_Trunk,FBD_VL,FBD_VM,FBD_VR
 SG_ StatusUWBRangingFBD_SML_IV00 : 160|8@1+ (1.0,0) [0|255] "" FBD_HL,FBD_HM,FBD_HR,FBD_MM,FBD_Miko,FBD_Trunk,FBD_VL,FBD_VM,FBD_VR
 SG_ StatusUWBRangingFBD_SML_IV01 : 168|8@1+ (1.0,0) [0|255] "" FBD_HL,FBD_HM,FBD_HR,FBD_MM,FBD_Miko,FBD_Trunk,FBD_VL,FBD_VM,FBD_VR
 SG_ StatusUWBRangingFBD_SML_IV02 : 176|8@1+ (1.0,0) [0|255] "" FBD_HL,FBD_HM,FBD_HR,FBD_MM,FBD_Miko,FBD_Trunk,FBD_VL,FBD_VM,FBD_VR
 SG_ StatusUWBRangingFBD_SML_IV03 : 184|8@1+ (1.0,0) [0|255] "" FBD_HL,FBD_HM,FBD_HR,FBD_MM,FBD_Miko,FBD_Trunk,FBD_VL,FBD_VM,FBD_VR
 SG_ StatusUWBRangingFBD_SML_Sign00 : 192|8@1+ (1.0,0) [0|255] "" FBD_HL,FBD_HM,FBD_HR,FBD_MM,FBD_Miko,FBD_Trunk,FBD_VL,FBD_VM,FBD_VR
 SG_ StatusUWBRangingFBD_SML_Sign01 : 200|8@1+ (1.0,0) [0|255] "" FBD_HL,FBD_HM,FBD_HR,FBD_MM,FBD_Miko,FBD_Trunk,FBD_VL,FBD_VM,FBD_VR
 SG_ StatusUWBRangingFBD_SML_Sign02 : 208|8@1+ (1.0,0) [0|255] "" FBD_HL,FBD_HM,FBD_HR,FBD_MM,FBD_Miko,FBD_Trunk,FBD_VL,FBD_VM,FBD_VR
 SG_ StatusUWBRangingFBD_SML_Sign03 : 216|8@1+ (1.0,0) [0|255] "" FBD_HL,FBD_HM,FBD_HR,FBD_MM,FBD_Miko,FBD_Trunk,FBD_VL,FBD_VM,FBD_VR
 SG_ StatusUWBRangingFBD_SML_Sign04 : 224|8@1+ (1.0,0) [0|255] "" FBD_HL,FBD_HM,FBD_HR,FBD_MM,FBD_Miko,FBD_Trunk,FBD_VL,FBD_VM,FBD_VR
 SG_ StatusUWBRangingFBD_SML_Sign05 : 232|8@1+ (1.0,0) [0|255] "" FBD_HL,FBD_HM,FBD_HR,FBD_MM,FBD_Miko,FBD_Trunk,FBD_VL,FBD_VM,FBD_VR
 SG_ StatusUWBRangingFBD_SML_Sign06 : 240|8@1+ (1.0,0) [0|255] "" FBD_HL,FBD_HM,FBD_HR,FBD_MM,FBD_Miko,FBD_Trunk,FBD_VL,FBD_VM,FBD_VR
 SG_ StatusUWBRangingFBD_SML_Sign07 : 248|8@1+ (1.0,0) [0|255] "" FBD_HL,FBD_HM,FBD_HR,FBD_MM,FBD_Miko,FBD_Trunk,FBD_VL,FBD_VM,FBD_VR

BO_ 439 StatusUWBRangingFBD_SMR: 32 IPB_App1
 SG_ StatusUWBRangingFBD_SMR_SessionI : 0|8@1+ (1.0,0) [0|252] "" FBD_HL,FBD_HM,FBD_HR,FBD_MM,FBD_Miko,FBD_Trunk,FBD_VL,FBD_VM,FBD_VR
 SG_ StatusUWBRangingFBD_SMR_TimeOfFl : 8|16@1+ (15.65,0) [0|1000000] "ps" FBD_HL,FBD_HM,FBD_HR,FBD_MM,FBD_Miko,FBD_Trunk,FBD_VL,FBD_VM,FBD_VR
 SG_ StatusUWBRangingFBD_SMR_RangingB : 24|16@1+ (1.0,0) [0|65532] "" FBD_HL,FBD_HM,FBD_HR,FBD_MM,FBD_Miko,FBD_Trunk,FBD_VL,FBD_VM,FBD_VR
 SG_ StatusUWBRangingFBD_SMR_RangingR : 40|8@1+ (1.0,0) [0|252] "" FBD_HL,FBD_HM,FBD_HR,FBD_MM,FBD_Miko,FBD_Trunk,FBD_VL,FBD_VM,FBD_VR
 SG_ StatusUWBRangingFBD_SMR_OverallR : 48|8@1+ (0.5,-127) [-127|-1] "dB" FBD_HL,FBD_HM,FBD_HR,FBD_MM,FBD_Miko,FBD_Trunk,FBD_VL,FBD_VM,FBD_VR
 SG_ StatusUWBRangingFBD_SMR_FirstPat : 56|8@1+ (0.5,-127) [-127|-1] "dB" FBD_HL,FBD_HM,FBD_HR,FBD_MM,FBD_Miko,FBD_Trunk,FBD_VL,FBD_VM,FBD_VR
 SG_ StatusUWBRangingFBD_SMR_AngleOfA : 64|8@1+ (1.0,-90) [-90|90] "°" FBD_HL,FBD_HM,FBD_HR,FBD_MM,FBD_Miko,FBD_Trunk,FBD_VL,FBD_VM,FBD_VR
 SG_ StatusUWBRangingFBD_SMR_PhaseDif : 72|8@1+ (1.0,-90) [-90|90] "°" FBD_HL,FBD_HM,FBD_HR,FBD_MM,FBD_Miko,FBD_Trunk,FBD_VL,FBD_VM,FBD_VR
 SG_ StatusUWBRangingFBD_SMR_Stronges : 80|8@1+ (0.5,-127) [-127|-1] "dB" FBD_HL,FBD_HM,FBD_HR,FBD_MM,FBD_Miko,FBD_Trunk,FBD_VL,FBD_VM,FBD_VR
 SG_ StatusUWBRangingFBD_SMR_BLE_RSSI : 88|8@1+ (0.5,-127) [-127|-1] "dB" FBD_HL,FBD_HM,FBD_HR,FBD_MM,FBD_Miko,FBD_Trunk,FBD_VL,FBD_VM,FBD_VR
 SG_ StatusUWBRangingFBD_SMR_Strong_2 : 96|8@1+ (0.5,0) [0|125] "ns" FBD_HL,FBD_HM,FBD_HR,FBD_MM,FBD_Miko,FBD_Trunk,FBD_VL,FBD_VM,FBD_VR
 SG_ StatusUWBRangingFBD_SMR_PDoA_SNR : 104|8@1+ (0.5,0) [0|126] "dB" FBD_HL,FBD_HM,FBD_HR,FBD_MM,FBD_Miko,FBD_Trunk,FBD_VL,FBD_VM,FBD_VR
 SG_ StatusUWBRangingFBD_SMR_DutyCycl : 112|8@1+ (1.0,0) [0|100] "%" FBD_HL,FBD_HM,FBD_HR,FBD_MM,FBD_Miko,FBD_Trunk,FBD_VL,FBD_VM,FBD_VR
 SG_ StatusUWBRangingFBD_SMR_FinalDat : 120|4@1+ (1.0,0) [0|12] "" FBD_HL,FBD_HM,FBD_HR,FBD_MM,FBD_Miko,FBD_Trunk,FBD_VL,FBD_VM,FBD_VR
 SG_ StatusUWBRangingFBD_SMR_Antenna : 124|4@1+ (1,0) [0|0] "" FBD_HL,FBD_HM,FBD_HR,FBD_MM,FBD_Miko,FBD_Trunk,FBD_VL,FBD_VM,FBD_VR
 SG_ StatusUWBRangingFBD_SMR_Status1 : 128|8@1+ (1,0) [0|0] "" FBD_HL,FBD_HM,FBD_HR,FBD_MM,FBD_Miko,FBD_Trunk,FBD_VL,FBD_VM,FBD_VR
 SG_ StatusUWBRangingFBD_SMR_Status2 : 136|8@1+ (1.0,0) [0|252] "" FBD_HL,FBD_HM,FBD_HR,FBD_MM,FBD_Miko,FBD_Trunk,FBD_VL,FBD_VM,FBD_VR
 SG_ StatusUWBRangingFBD_SMR_Status3 : 144|8@1+ (1.0,0) [0|252] "" FBD_HL,FBD_HM,FBD_HR,FBD_MM,FBD_Miko,FBD_Trunk,FBD_VL,FBD_VM,FBD_VR
 SG_ StatusUWBRangingFBD_SMR_Status4 : 152|8@1+ (1.0,0) [0|252] "" FBD_HL,FBD_HM,FBD_HR,FBD_MM,FBD_Miko,FBD_Trunk,FBD_VL,FBD_VM,FBD_VR
 SG_ StatusUWBRangingFBD_SMR_IV00 : 160|8@1+ (1.0,0) [0|255] "" FBD_HL,FBD_HM,FBD_HR,FBD_MM,FBD_Miko,FBD_Trunk,FBD_VL,FBD_VM,FBD_VR
 SG_ StatusUWBRangingFBD_SMR_IV01 : 168|8@1+ (1.0,0) [0|255] "" FBD_HL,FBD_HM,FBD_HR,FBD_MM,FBD_Miko,FBD_Trunk,FBD_VL,FBD_VM,FBD_VR
 SG_ StatusUWBRangingFBD_SMR_IV02 : 176|8@1+ (1.0,0) [0|255] "" FBD_HL,FBD_HM,FBD_HR,FBD_MM,FBD_Miko,FBD_Trunk,FBD_VL,FBD_VM,FBD_VR
 SG_ StatusUWBRangingFBD_SMR_IV03 : 184|8@1+ (1.0,0) [0|255] "" FBD_HL,FBD_HM,FBD_HR,FBD_MM,FBD_Miko,FBD_Trunk,FBD_VL,FBD_VM,FBD_VR
 SG_ StatusUWBRangingFBD_SMR_Sign00 : 192|8@1+ (1.0,0) [0|255] "" FBD_HL,FBD_HM,FBD_HR,FBD_MM,FBD_Miko,FBD_Trunk,FBD_VL,FBD_VM,FBD_VR
 SG_ StatusUWBRangingFBD_SMR_Sign01 : 200|8@1+ (1.0,0) [0|255] "" FBD_HL,FBD_HM,FBD_HR,FBD_MM,FBD_Miko,FBD_Trunk,FBD_VL,FBD_VM,FBD_VR
 SG_ StatusUWBRangingFBD_SMR_Sign02 : 208|8@1+ (1.0,0) [0|255] "" FBD_HL,FBD_HM,FBD_HR,FBD_MM,FBD_Miko,FBD_Trunk,FBD_VL,FBD_VM,FBD_VR
 SG_ StatusUWBRangingFBD_SMR_Sign03 : 216|8@1+ (1.0,0) [0|255] "" FBD_HL,FBD_HM,FBD_HR,FBD_MM,FBD_Miko,FBD_Trunk,FBD_VL,FBD_VM,FBD_VR
 SG_ StatusUWBRangingFBD_SMR_Sign04 : 224|8@1+ (1.0,0) [0|255] "" FBD_HL,FBD_HM,FBD_HR,FBD_MM,FBD_Miko,FBD_Trunk,FBD_VL,FBD_VM,FBD_VR
 SG_ StatusUWBRangingFBD_SMR_Sign05 : 232|8@1+ (1.0,0) [0|255] "" FBD_HL,FBD_HM,FBD_HR,FBD_MM,FBD_Miko,FBD_Trunk,FBD_VL,FBD_VM,FBD_VR
 SG_ StatusUWBRangingFBD_SMR_Sign06 : 240|8@1+ (1.0,0) [0|255] "" FBD_HL,FBD_HM,FBD_HR,FBD_MM,FBD_Miko,FBD_Trunk,FBD_VL,FBD_VM,FBD_VR
 SG_ StatusUWBRangingFBD_SMR_Sign07 : 248|8@1+ (1.0,0) [0|255] "" FBD_HL,FBD_HM,FBD_HR,FBD_MM,FBD_Miko,FBD_Trunk,FBD_VL,FBD_VM,FBD_VR

BO_ 433 StatusUWBRangingFBD_Trunk: 32 FBD_Trunk
 SG_ StatusUWBRangingFBD_Trunk_Sessio : 0|8@1+ (1.0,0) [0|252] "" FBD_HL,FBD_HM,FBD_HR,FBD_MM,FBD_Miko,FBD_VL,FBD_VM,FBD_VR,IPB_App1
 SG_ StatusUWBRangingFBD_Trunk_TimeOf : 8|16@1+ (15.65,0) [0|1000000] "ps" FBD_HL,FBD_HM,FBD_HR,FBD_MM,FBD_Miko,FBD_VL,FBD_VM,FBD_VR,IPB_App1
 SG_ StatusUWBRangingFBD_Trunk_Rangin : 24|16@1+ (1.0,0) [0|65532] "" FBD_HL,FBD_HM,FBD_HR,FBD_MM,FBD_Miko,FBD_VL,FBD_VM,FBD_VR,IPB_App1
 SG_ StatusUWBRangingFBD_Trunk_Rang_2 : 40|8@1+ (1.0,0) [0|252] "" FBD_HL,FBD_HM,FBD_HR,FBD_MM,FBD_Miko,FBD_VL,FBD_VM,FBD_VR,IPB_App1
 SG_ StatusUWBRangingFBD_Trunk_Overal : 48|8@1+ (0.5,-127) [-127|-1] "dB" FBD_HL,FBD_HM,FBD_HR,FBD_MM,FBD_Miko,FBD_VL,FBD_VM,FBD_VR,IPB_App1
 SG_ StatusUWBRangingFBD_Trunk_FirstP : 56|8@1+ (0.5,-127) [-127|-1] "dB" FBD_HL,FBD_HM,FBD_HR,FBD_MM,FBD_Miko,FBD_VL,FBD_VM,FBD_VR,IPB_App1
 SG_ StatusUWBRangingFBD_Trunk_AngleO : 64|8@1+ (1.0,-90) [-90|90] "°" FBD_HL,FBD_HM,FBD_HR,FBD_MM,FBD_Miko,FBD_VL,FBD_VM,FBD_VR,IPB_App1
 SG_ StatusUWBRangingFBD_Trunk_PhaseD : 72|8@1+ (1.0,-90) [-90|90] "°" FBD_HL,FBD_HM,FBD_HR,FBD_MM,FBD_Miko,FBD_VL,FBD_VM,FBD_VR,IPB_App1
 SG_ StatusUWBRangingFBD_Trunk_Strong : 80|8@1+ (0.5,-127) [-127|-1] "dB" FBD_HL,FBD_HM,FBD_HR,FBD_MM,FBD_Miko,FBD_VL,FBD_VM,FBD_VR,IPB_App1
 SG_ StatusUWBRangingFBD_Trunk_BLE_RS : 88|8@1+ (0.5,-127) [-127|-1] "dB" FBD_HL,FBD_HM,FBD_HR,FBD_MM,FBD_Miko,FBD_VL,FBD_VM,FBD_VR,IPB_App1
 SG_ StatusUWBRangingFBD_Trunk_Stro_2 : 96|8@1+ (0.5,0) [0|125] "ns" FBD_HL,FBD_HM,FBD_HR,FBD_MM,FBD_Miko,FBD_VL,FBD_VM,FBD_VR,IPB_App1
 SG_ StatusUWBRangingFBD_Trunk_PDoA_S : 104|8@1+ (0.5,0) [0|126] "dB" FBD_HL,FBD_HM,FBD_HR,FBD_MM,FBD_Miko,FBD_VL,FBD_VM,FBD_VR,IPB_App1
 SG_ StatusUWBRangingFBD_Trunk_DutyCy : 112|8@1+ (1.0,0) [0|100] "%" FBD_HL,FBD_HM,FBD_HR,FBD_MM,FBD_Miko,FBD_VL,FBD_VM,FBD_VR,IPB_App1
 SG_ StatusUWBRangingFBD_Trunk_FinalD : 120|4@1+ (1.0,0) [0|12] "" FBD_HL,FBD_HM,FBD_HR,FBD_MM,FBD_Miko,FBD_VL,FBD_VM,FBD_VR,IPB_App1
 SG_ StatusUWBRangingFBD_Trunk_Antenn : 124|4@1+ (1,0) [0|0] "" FBD_HL,FBD_HM,FBD_HR,FBD_MM,FBD_Miko,FBD_VL,FBD_VM,FBD_VR,IPB_App1
 SG_ StatusUWBRangingFBD_Trunk_Status : 128|8@1+ (1,0) [0|0] "" FBD_HL,FBD_HM,FBD_HR,FBD_MM,FBD_Miko,FBD_VL,FBD_VM,FBD_VR,IPB_App1
 SG_ StatusUWBRangingFBD_Trunk_Stat_2 : 136|8@1+ (1.0,0) [0|252] "" FBD_HL,FBD_HM,FBD_HR,FBD_MM,FBD_Miko,FBD_VL,FBD_VM,FBD_VR,IPB_App1
 SG_ StatusUWBRangingFBD_Trunk_Stat_3 : 144|8@1+ (1.0,0) [0|252] "" FBD_HL,FBD_HM,FBD_HR,FBD_MM,FBD_Miko,FBD_VL,FBD_VM,FBD_VR,IPB_App1
 SG_ StatusUWBRangingFBD_Trunk_Stat_4 : 152|8@1+ (1.0,0) [0|252] "" FBD_HL,FBD_HM,FBD_HR,FBD_MM,FBD_Miko,FBD_VL,FBD_VM,FBD_VR,IPB_App1
 SG_ StatusUWBRangingFBD_Trunk_IV00 : 160|8@1+ (1.0,0) [0|255] "" FBD_HL,FBD_HM,FBD_HR,FBD_MM,FBD_Miko,FBD_VL,FBD_VM,FBD_VR,IPB_App1
 SG_ StatusUWBRangingFBD_Trunk_IV01 : 168|8@1+ (1.0,0) [0|255] "" FBD_HL,FBD_HM,FBD_HR,FBD_MM,FBD_Miko,FBD_VL,FBD_VM,FBD_VR,IPB_App1
 SG_ StatusUWBRangingFBD_Trunk_IV02 : 176|8@1+ (1.0,0) [0|255] "" FBD_HL,FBD_HM,FBD_HR,FBD_MM,FBD_Miko,FBD_VL,FBD_VM,FBD_VR,IPB_App1
 SG_ StatusUWBRangingFBD_Trunk_IV03 : 184|8@1+ (1.0,0) [0|255] "" FBD_HL,FBD_HM,FBD_HR,FBD_MM,FBD_Miko,FBD_VL,FBD_VM,FBD_VR,IPB_App1
 SG_ StatusUWBRangingFBD_Trunk_Sign00 : 192|8@1+ (1.0,0) [0|255] "" FBD_HL,FBD_HM,FBD_HR,FBD_MM,FBD_Miko,FBD_VL,FBD_VM,FBD_VR,IPB_App1
 SG_ StatusUWBRangingFBD_Trunk_Sign01 : 200|8@1+ (1.0,0) [0|255] "" FBD_HL,FBD_HM,FBD_HR,FBD_MM,FBD_Miko,FBD_VL,FBD_VM,FBD_VR,IPB_App1
 SG_ StatusUWBRangingFBD_Trunk_Sign02 : 208|8@1+ (1.0,0) [0|255] "" FBD_HL,FBD_HM,FBD_HR,FBD_MM,FBD_Miko,FBD_VL,FBD_VM,FBD_VR,IPB_App1
 SG_ StatusUWBRangingFBD_Trunk_Sign03 : 216|8@1+ (1.0,0) [0|255] "" FBD_HL,FBD_HM,FBD_HR,FBD_MM,FBD_Miko,FBD_VL,FBD_VM,FBD_VR,IPB_App1
 SG_ StatusUWBRangingFBD_Trunk_Sign04 : 224|8@1+ (1.0,0) [0|255] "" FBD_HL,FBD_HM,FBD_HR,FBD_MM,FBD_Miko,FBD_VL,FBD_VM,FBD_VR,IPB_App1
 SG_ StatusUWBRangingFBD_Trunk_Sign05 : 232|8@1+ (1.0,0) [0|255] "" FBD_HL,FBD_HM,FBD_HR,FBD_MM,FBD_Miko,FBD_VL,FBD_VM,FBD_VR,IPB_App1
 SG_ StatusUWBRangingFBD_Trunk_Sign06 : 240|8@1+ (1.0,0) [0|255] "" FBD_HL,FBD_HM,FBD_HR,FBD_MM,FBD_Miko,FBD_VL,FBD_VM,FBD_VR,IPB_App1
 SG_ StatusUWBRangingFBD_Trunk_Sign07 : 248|8@1+ (1.0,0) [0|255] "" FBD_HL,FBD_HM,FBD_HR,FBD_MM,FBD_Miko,FBD_VL,FBD_VM,FBD_VR,IPB_App1

BO_ 434 StatusUWBRangingFBD_VL: 32 FBD_VL
 SG_ StatusUWBRangingFBD_VL_SessionID : 0|8@1+ (1.0,0) [0|252] "" FBD_HL,FBD_HM,FBD_HR,FBD_MM,FBD_Miko,FBD_Trunk,FBD_VM,FBD_VR,IPB_App1
 SG_ StatusUWBRangingFBD_VL_TimeOfFli : 8|16@1+ (15.65,0) [0|1000000] "ps" FBD_HL,FBD_HM,FBD_HR,FBD_MM,FBD_Miko,FBD_Trunk,FBD_VM,FBD_VR,IPB_App1
 SG_ StatusUWBRangingFBD_VL_RangingBl : 24|16@1+ (1.0,0) [0|65532] "" FBD_HL,FBD_HM,FBD_HR,FBD_MM,FBD_Miko,FBD_Trunk,FBD_VM,FBD_VR,IPB_App1
 SG_ StatusUWBRangingFBD_VL_RangingRo : 40|8@1+ (1.0,0) [0|252] "" FBD_HL,FBD_HM,FBD_HR,FBD_MM,FBD_Miko,FBD_Trunk,FBD_VM,FBD_VR,IPB_App1
 SG_ StatusUWBRangingFBD_VL_OverallRe : 48|8@1+ (0.5,-127) [-127|-1] "dB" FBD_HL,FBD_HM,FBD_HR,FBD_MM,FBD_Miko,FBD_Trunk,FBD_VM,FBD_VR,IPB_App1
 SG_ StatusUWBRangingFBD_VL_FirstPath : 56|8@1+ (0.5,-127) [-127|-1] "dB" FBD_HL,FBD_HM,FBD_HR,FBD_MM,FBD_Miko,FBD_Trunk,FBD_VM,FBD_VR,IPB_App1
 SG_ StatusUWBRangingFBD_VL_AngleOfAr : 64|8@1+ (1.0,-90) [-90|90] "°" FBD_HL,FBD_HM,FBD_HR,FBD_MM,FBD_Miko,FBD_Trunk,FBD_VM,FBD_VR,IPB_App1
 SG_ StatusUWBRangingFBD_VL_PhaseDiff : 72|8@1+ (1.0,-90) [-90|90] "°" FBD_HL,FBD_HM,FBD_HR,FBD_MM,FBD_Miko,FBD_Trunk,FBD_VM,FBD_VR,IPB_App1
 SG_ StatusUWBRangingFBD_VL_Strongest : 80|8@1+ (0.5,-127) [-127|-1] "dB" FBD_HL,FBD_HM,FBD_HR,FBD_MM,FBD_Miko,FBD_Trunk,FBD_VM,FBD_VR,IPB_App1
 SG_ StatusUWBRangingFBD_VL_BLE_RSSI : 88|8@1+ (0.5,-127) [-127|-1] "dB" FBD_HL,FBD_HM,FBD_HR,FBD_MM,FBD_Miko,FBD_Trunk,FBD_VM,FBD_VR,IPB_App1
 SG_ StatusUWBRangingFBD_VL_Stronge_2 : 96|8@1+ (0.5,0) [0|125] "ns" FBD_HL,FBD_HM,FBD_HR,FBD_MM,FBD_Miko,FBD_Trunk,FBD_VM,FBD_VR,IPB_App1
 SG_ StatusUWBRangingFBD_VL_PDoA_SNR : 104|8@1+ (0.5,0) [0|126] "dB" FBD_HL,FBD_HM,FBD_HR,FBD_MM,FBD_Miko,FBD_Trunk,FBD_VM,FBD_VR,IPB_App1
 SG_ StatusUWBRangingFBD_VL_DutyCycle : 112|8@1+ (1.0,0) [0|100] "%" FBD_HL,FBD_HM,FBD_HR,FBD_MM,FBD_Miko,FBD_Trunk,FBD_VM,FBD_VR,IPB_App1
 SG_ StatusUWBRangingFBD_VL_FinalData : 120|4@1+ (1.0,0) [0|12] "" FBD_HL,FBD_HM,FBD_HR,FBD_MM,FBD_Miko,FBD_Trunk,FBD_VM,FBD_VR,IPB_App1
 SG_ StatusUWBRangingFBD_VL_Antenna : 124|4@1+ (1,0) [0|0] "" FBD_HL,FBD_HM,FBD_HR,FBD_MM,FBD_Miko,FBD_Trunk,FBD_VM,FBD_VR,IPB_App1
 SG_ StatusUWBRangingFBD_VL_Status1 : 128|8@1+ (1,0) [0|0] "" FBD_HL,FBD_HM,FBD_HR,FBD_MM,FBD_Miko,FBD_Trunk,FBD_VM,FBD_VR,IPB_App1
 SG_ StatusUWBRangingFBD_VL_Status2 : 136|8@1+ (1.0,0) [0|252] "" FBD_HL,FBD_HM,FBD_HR,FBD_MM,FBD_Miko,FBD_Trunk,FBD_VM,FBD_VR,IPB_App1
 SG_ StatusUWBRangingFBD_VL_Status3 : 144|8@1+ (1.0,0) [0|252] "" FBD_HL,FBD_HM,FBD_HR,FBD_MM,FBD_Miko,FBD_Trunk,FBD_VM,FBD_VR,IPB_App1
 SG_ StatusUWBRangingFBD_VL_Status4 : 152|8@1+ (1.0,0) [0|252] "" FBD_HL,FBD_HM,FBD_HR,FBD_MM,FBD_Miko,FBD_Trunk,FBD_VM,FBD_VR,IPB_App1
 SG_ StatusUWBRangingFBD_VL_IV00 : 160|8@1+ (1.0,0) [0|255] "" FBD_HL,FBD_HM,FBD_HR,FBD_MM,FBD_Miko,FBD_Trunk,FBD_VM,FBD_VR,IPB_App1
 SG_ StatusUWBRangingFBD_VL_IV01 : 168|8@1+ (1.0,0) [0|255] "" FBD_HL,FBD_HM,FBD_HR,FBD_MM,FBD_Miko,FBD_Trunk,FBD_VM,FBD_VR,IPB_App1
 SG_ StatusUWBRangingFBD_VL_IV02 : 176|8@1+ (1.0,0) [0|255] "" FBD_HL,FBD_HM,FBD_HR,FBD_MM,FBD_Miko,FBD_Trunk,FBD_VM,FBD_VR,IPB_App1
 SG_ StatusUWBRangingFBD_VL_IV03 : 184|8@1+ (1.0,0) [0|255] "" FBD_HL,FBD_HM,FBD_HR,FBD_MM,FBD_Miko,FBD_Trunk,FBD_VM,FBD_VR,IPB_App1
 SG_ StatusUWBRangingFBD_VL_Sign00 : 192|8@1+ (1.0,0) [0|255] "" FBD_HL,FBD_HM,FBD_HR,FBD_MM,FBD_Miko,FBD_Trunk,FBD_VM,FBD_VR,IPB_App1
 SG_ StatusUWBRangingFBD_VL_Sign01 : 200|8@1+ (1.0,0) [0|255] "" FBD_HL,FBD_HM,FBD_HR,FBD_MM,FBD_Miko,FBD_Trunk,FBD_VM,FBD_VR,IPB_App1
 SG_ StatusUWBRangingFBD_VL_Sign02 : 208|8@1+ (1.0,0) [0|255] "" FBD_HL,FBD_HM,FBD_HR,FBD_MM,FBD_Miko,FBD_Trunk,FBD_VM,FBD_VR,IPB_App1
 SG_ StatusUWBRangingFBD_VL_Sign03 : 216|8@1+ (1.0,0) [0|255] "" FBD_HL,FBD_HM,FBD_HR,FBD_MM,FBD_Miko,FBD_Trunk,FBD_VM,FBD_VR,IPB_App1
 SG_ StatusUWBRangingFBD_VL_Sign04 : 224|8@1+ (1.0,0) [0|255] "" FBD_HL,FBD_HM,FBD_HR,FBD_MM,FBD_Miko,FBD_Trunk,FBD_VM,FBD_VR,IPB_App1
 SG_ StatusUWBRangingFBD_VL_Sign05 : 232|8@1+ (1.0,0) [0|255] "" FBD_HL,FBD_HM,FBD_HR,FBD_MM,FBD_Miko,FBD_Trunk,FBD_VM,FBD_VR,IPB_App1
 SG_ StatusUWBRangingFBD_VL_Sign06 : 240|8@1+ (1.0,0) [0|255] "" FBD_HL,FBD_HM,FBD_HR,FBD_MM,FBD_Miko,FBD_Trunk,FBD_VM,FBD_VR,IPB_App1
 SG_ StatusUWBRangingFBD_VL_Sign07 : 248|8@1+ (1.0,0) [0|255] "" FBD_HL,FBD_HM,FBD_HR,FBD_MM,FBD_Miko,FBD_Trunk,FBD_VM,FBD_VR,IPB_App1

BO_ 430 StatusUWBRangingFBD_VM: 32 FBD_VM
 SG_ StatusUWBRangingFBD_VM_SessionID : 0|8@1+ (1.0,0) [0|252] "" FBD_HL,FBD_HM,FBD_HR,FBD_MM,FBD_Miko,FBD_Trunk,FBD_VL,FBD_VR,IPB_App1
 SG_ StatusUWBRangingFBD_VM_TimeOfFli : 8|16@1+ (15.65,0) [0|1000000] "ps" FBD_HL,FBD_HM,FBD_HR,FBD_MM,FBD_Miko,FBD_Trunk,FBD_VL,FBD_VR,IPB_App1
 SG_ StatusUWBRangingFBD_VM_RangingBl : 24|16@1+ (1.0,0) [0|65532] "" FBD_HL,FBD_HM,FBD_HR,FBD_MM,FBD_Miko,FBD_Trunk,FBD_VL,FBD_VR,IPB_App1
 SG_ StatusUWBRangingFBD_VM_RangingRo : 40|8@1+ (1.0,0) [0|252] "" FBD_HL,FBD_HM,FBD_HR,FBD_MM,FBD_Miko,FBD_Trunk,FBD_VL,FBD_VR,IPB_App1
 SG_ StatusUWBRangingFBD_VM_OverallRe : 48|8@1+ (0.5,-127) [-127|-1] "dB" FBD_HL,FBD_HM,FBD_HR,FBD_MM,FBD_Miko,FBD_Trunk,FBD_VL,FBD_VR,IPB_App1
 SG_ StatusUWBRangingFBD_VM_FirstPath : 56|8@1+ (0.5,-127) [-127|-1] "dB" FBD_HL,FBD_HM,FBD_HR,FBD_MM,FBD_Miko,FBD_Trunk,FBD_VL,FBD_VR,IPB_App1
 SG_ StatusUWBRangingFBD_VM_AngleOfAr : 64|8@1+ (1.0,-90) [-90|90] "°" FBD_HL,FBD_HM,FBD_HR,FBD_MM,FBD_Miko,FBD_Trunk,FBD_VL,FBD_VR,IPB_App1
 SG_ StatusUWBRangingFBD_VM_PhaseDiff : 72|8@1+ (1.0,-90) [-90|90] "°" FBD_HL,FBD_HM,FBD_HR,FBD_MM,FBD_Miko,FBD_Trunk,FBD_VL,FBD_VR,IPB_App1
 SG_ StatusUWBRangingFBD_VM_Strongest : 80|8@1+ (0.5,-127) [-127|-1] "dB" FBD_HL,FBD_HM,FBD_HR,FBD_MM,FBD_Miko,FBD_Trunk,FBD_VL,FBD_VR,IPB_App1
 SG_ StatusUWBRangingFBD_VM_BLE_RSSI : 88|8@1+ (0.5,-127) [-127|-1] "dB" FBD_HL,FBD_HM,FBD_HR,FBD_MM,FBD_Miko,FBD_Trunk,FBD_VL,FBD_VR,IPB_App1
 SG_ StatusUWBRangingFBD_VM_Stronge_2 : 96|8@1+ (0.5,0) [0|125] "ns" FBD_HL,FBD_HM,FBD_HR,FBD_MM,FBD_Miko,FBD_Trunk,FBD_VL,FBD_VR,IPB_App1
 SG_ StatusUWBRangingFBD_VM_PDoA_SNR : 104|8@1+ (0.5,0) [0|126] "dB" FBD_HL,FBD_HM,FBD_HR,FBD_MM,FBD_Miko,FBD_Trunk,FBD_VL,FBD_VR,IPB_App1
 SG_ StatusUWBRangingFBD_VM_DutyCycle : 112|8@1+ (1.0,0) [0|100] "%" FBD_HL,FBD_HM,FBD_HR,FBD_MM,FBD_Miko,FBD_Trunk,FBD_VL,FBD_VR,IPB_App1
 SG_ StatusUWBRangingFBD_VM_FinalData : 120|4@1+ (1.0,0) [0|12] "" FBD_HL,FBD_HM,FBD_HR,FBD_MM,FBD_Miko,FBD_Trunk,FBD_VL,FBD_VR,IPB_App1
 SG_ StatusUWBRangingFBD_VM_Antenna : 124|4@1+ (1,0) [0|0] "" FBD_HL,FBD_HM,FBD_HR,FBD_MM,FBD_Miko,FBD_Trunk,FBD_VL,FBD_VR,IPB_App1
 SG_ StatusUWBRangingFBD_VM_Status1 : 128|8@1+ (1,0) [0|0] "" FBD_HL,FBD_HM,FBD_HR,FBD_MM,FBD_Miko,FBD_Trunk,FBD_VL,FBD_VR,IPB_App1
 SG_ StatusUWBRangingFBD_VM_Status2 : 136|8@1+ (1.0,0) [0|252] "" FBD_HL,FBD_HM,FBD_HR,FBD_MM,FBD_Miko,FBD_Trunk,FBD_VL,FBD_VR,IPB_App1
 SG_ StatusUWBRangingFBD_VM_Status3 : 144|8@1+ (1.0,0) [0|252] "" FBD_HL,FBD_HM,FBD_HR,FBD_MM,FBD_Miko,FBD_Trunk,FBD_VL,FBD_VR,IPB_App1
 SG_ StatusUWBRangingFBD_VM_Status4 : 152|8@1+ (1.0,0) [0|252] "" FBD_HL,FBD_HM,FBD_HR,FBD_MM,FBD_Miko,FBD_Trunk,FBD_VL,FBD_VR,IPB_App1
 SG_ StatusUWBRangingFBD_VM_IV00 : 160|8@1+ (1.0,0) [0|255] "" FBD_HL,FBD_HM,FBD_HR,FBD_MM,FBD_Miko,FBD_Trunk,FBD_VL,FBD_VR,IPB_App1
 SG_ StatusUWBRangingFBD_VM_IV01 : 168|8@1+ (1.0,0) [0|255] "" FBD_HL,FBD_HM,FBD_HR,FBD_MM,FBD_Miko,FBD_Trunk,FBD_VL,FBD_VR,IPB_App1
 SG_ StatusUWBRangingFBD_VM_IV02 : 176|8@1+ (1.0,0) [0|255] "" FBD_HL,FBD_HM,FBD_HR,FBD_MM,FBD_Miko,FBD_Trunk,FBD_VL,FBD_VR,IPB_App1
 SG_ StatusUWBRangingFBD_VM_IV03 : 184|8@1+ (1.0,0) [0|255] "" FBD_HL,FBD_HM,FBD_HR,FBD_MM,FBD_Miko,FBD_Trunk,FBD_VL,FBD_VR,IPB_App1
 SG_ StatusUWBRangingFBD_VM_Sign00 : 192|8@1+ (1.0,0) [0|255] "" FBD_HL,FBD_HM,FBD_HR,FBD_MM,FBD_Miko,FBD_Trunk,FBD_VL,FBD_VR,IPB_App1
 SG_ StatusUWBRangingFBD_VM_Sign01 : 200|8@1+ (1.0,0) [0|255] "" FBD_HL,FBD_HM,FBD_HR,FBD_MM,FBD_Miko,FBD_Trunk,FBD_VL,FBD_VR,IPB_App1
 SG_ StatusUWBRangingFBD_VM_Sign02 : 208|8@1+ (1.0,0) [0|255] "" FBD_HL,FBD_HM,FBD_HR,FBD_MM,FBD_Miko,FBD_Trunk,FBD_VL,FBD_VR,IPB_App1
 SG_ StatusUWBRangingFBD_VM_Sign03 : 216|8@1+ (1.0,0) [0|255] "" FBD_HL,FBD_HM,FBD_HR,FBD_MM,FBD_Miko,FBD_Trunk,FBD_VL,FBD_VR,IPB_App1
 SG_ StatusUWBRangingFBD_VM_Sign04 : 224|8@1+ (1.0,0) [0|255] "" FBD_HL,FBD_HM,FBD_HR,FBD_MM,FBD_Miko,FBD_Trunk,FBD_VL,FBD_VR,IPB_App1
 SG_ StatusUWBRangingFBD_VM_Sign05 : 232|8@1+ (1.0,0) [0|255] "" FBD_HL,FBD_HM,FBD_HR,FBD_MM,FBD_Miko,FBD_Trunk,FBD_VL,FBD_VR,IPB_App1
 SG_ StatusUWBRangingFBD_VM_Sign06 : 240|8@1+ (1.0,0) [0|255] "" FBD_HL,FBD_HM,FBD_HR,FBD_MM,FBD_Miko,FBD_Trunk,FBD_VL,FBD_VR,IPB_App1
 SG_ StatusUWBRangingFBD_VM_Sign07 : 248|8@1+ (1.0,0) [0|255] "" FBD_HL,FBD_HM,FBD_HR,FBD_MM,FBD_Miko,FBD_Trunk,FBD_VL,FBD_VR,IPB_App1

CM_ SG_ 590 StatusCSReportingFBD_VM_Error "contains CS error code";
CM_ SG_ 590 StatusCSReportingFBD_VM_Diagnosi "contains diagnostic information";
CM_ SG_ 590 StatusCSReportingFBD_VM_Status1 "contains status information";
CM_ SG_ 590 StatusCSReportingFBD_VM_Status2 "contains status information";
CM_ SG_ 595 StatusCSReportingFBD_VR_Error "contains CS error code";
CM_ SG_ 595 StatusCSReportingFBD_VR_Diagnosi "contains diagnostic information";
CM_ SG_ 595 StatusCSReportingFBD_VR_Status1 "contains status information";
CM_ SG_ 595 StatusCSReportingFBD_VR_Status2 "contains status information";
CM_ SG_ 186 StatusCSSessionConfigFBD_HL_Sess "defines the channel sounding session ID within the active connection";
CM_ SG_ 186 StatusCSSessionConfigFBD_HL_IRKL "defines the connected BLE device";
CM_ SG_ 186 StatusCSSessionConfigFBD_HL_Devi "defines the device group";
CM_ SG_ 186 StatusCSSessionConfigFBD_HL_Sele "defines the final interval chosen by the Controller (within Min/Max range), in units of 0.625ms";
CM_ SG_ 186 StatusCSSessionConfigFBD_HL_Se_2 "defines the selected procedure count";
CM_ SG_ 131 StatusCSSessionConfigFBD_HM_Sess "defines the channel sounding session ID within the active connection";
CM_ SG_ 131 StatusCSSessionConfigFBD_HM_IRKL "defines the connected BLE device";
CM_ SG_ 131 StatusCSSessionConfigFBD_HM_Devi "defines the device group";
CM_ SG_ 131 StatusCSSessionConfigFBD_HM_Sele "defines the final interval chosen by the Controller (within Min/Max range), in units of 0.625ms";
CM_ SG_ 131 StatusCSSessionConfigFBD_HM_Se_2 "defines the selected procedure count";
CM_ SG_ 187 StatusCSSessionConfigFBD_HR_Sess "defines the channel sounding session ID within the active connection";
CM_ SG_ 187 StatusCSSessionConfigFBD_HR_IRKL "defines the connected BLE device";
CM_ SG_ 187 StatusCSSessionConfigFBD_HR_Devi "defines the device group";
CM_ SG_ 187 StatusCSSessionConfigFBD_HR_Sele "defines the final interval chosen by the Controller (within Min/Max range), in units of 0.625ms";
CM_ SG_ 187 StatusCSSessionConfigFBD_HR_Se_2 "defines the selected procedure count";
CM_ SG_ 182 StatusCSSessionConfigFBD_Miko_Se "defines the channel sounding session ID within the active connection";
CM_ SG_ 182 StatusCSSessionConfigFBD_Miko_IR "defines the connected BLE device";
CM_ SG_ 182 StatusCSSessionConfigFBD_Miko_De "defines the device group";
CM_ SG_ 182 StatusCSSessionConfigFBD_Miko__2 "defines the final interval chosen by the Controller (within Min/Max range), in units of 0.625ms";
CM_ SG_ 182 StatusCSSessionConfigFBD_Miko__3 "defines the selected procedure count";
CM_ SG_ 188 StatusCSSessionConfigFBD_MM_Sess "defines the channel sounding session ID within the active connection";
CM_ SG_ 188 StatusCSSessionConfigFBD_MM_IRKL "defines the connected BLE device";
CM_ SG_ 188 StatusCSSessionConfigFBD_MM_Devi "defines the device group";
CM_ SG_ 188 StatusCSSessionConfigFBD_MM_Sele "defines the final interval chosen by the Controller (within Min/Max range), in units of 0.625ms";
CM_ SG_ 188 StatusCSSessionConfigFBD_MM_Se_2 "defines the selected procedure count";
CM_ SG_ 183 StatusCSSessionConfigFBD_Trunk_S "defines the channel sounding session ID within the active connection";
CM_ SG_ 183 StatusCSSessionConfigFBD_Trunk_I "defines the connected BLE device";
CM_ SG_ 183 StatusCSSessionConfigFBD_Trunk_D "defines the device group";
CM_ SG_ 183 StatusCSSessionConfigFBD_Trunk_2 "defines the final interval chosen by the Controller (within Min/Max range), in units of 0.625ms";
CM_ SG_ 183 StatusCSSessionConfigFBD_Trunk_3 "defines the selected procedure count";
CM_ SG_ 184 StatusCSSessionConfigFBD_VL_Sess "defines the channel sounding session ID within the active connection";
CM_ SG_ 184 StatusCSSessionConfigFBD_VL_IRKL "defines the connected BLE device";
CM_ SG_ 184 StatusCSSessionConfigFBD_VL_Devi "defines the device group";
CM_ SG_ 184 StatusCSSessionConfigFBD_VL_Sele "defines the final interval chosen by the Controller (within Min/Max range), in units of 0.625ms";
CM_ SG_ 184 StatusCSSessionConfigFBD_VL_Se_2 "defines the selected procedure count";
CM_ SG_ 130 StatusCSSessionConfigFBD_VM_Sess "defines the channel sounding session ID within the active connection";
CM_ SG_ 130 StatusCSSessionConfigFBD_VM_IRKL "defines the connected BLE device";
CM_ SG_ 130 StatusCSSessionConfigFBD_VM_Devi "defines the device group";
CM_ SG_ 130 StatusCSSessionConfigFBD_VM_Sele "defines the final interval chosen by the Controller (within Min/Max range), in units of 0.625ms";
CM_ SG_ 130 StatusCSSessionConfigFBD_VM_Se_2 "defines the selected procedure count";
CM_ SG_ 185 StatusCSSessionConfigFBD_VR_Sess "defines the channel sounding session ID within the active connection";
CM_ SG_ 185 StatusCSSessionConfigFBD_VR_IRKL "defines the connected BLE device";
CM_ SG_ 185 StatusCSSessionConfigFBD_VR_Devi "defines the device group";
CM_ SG_ 185 StatusCSSessionConfigFBD_VR_Sele "defines the final interval chosen by the Controller (within Min/Max range), in units of 0.625ms";
CM_ SG_ 185 StatusCSSessionConfigFBD_VR_Se_2 "defines the selected procedure count";
CM_ SG_ 646 StatusDiagnosticFBD_HL_BMWPartNu "contains BMW part number, LSB";
CM_ SG_ 646 StatusDiagnosticFBD_HL_BMWPart_2 "contains BMW part number";
CM_ SG_ 646 StatusDiagnosticFBD_HL_BMWPart_3 "contains BMW part number";
CM_ SG_ 646 StatusDiagnosticFBD_HL_BMWPart_4 "contains BMW part number";
CM_ SG_ 646 StatusDiagnosticFBD_HL_BMWPart_5 "contains BMW part number";
CM_ SG_ 646 StatusDiagnosticFBD_HL_BMWPart_6 "contains BMW part number";
CM_ SG_ 646 StatusDiagnosticFBD_HL_BMWPart_7 "contains BMW part number, MSB";
CM_ SG_ 646 StatusDiagnosticFBD_HL_BMWPart_8 "contains BMW part number, AI";
CM_ SG_ 646 StatusDiagnosticFBD_HL_HWELMain "contains HWEL";
CM_ SG_ 646 StatusDiagnosticFBD_HL_HWELMinor "contains HWEL";
CM_ SG_ 646 StatusDiagnosticFBD_HL_HWELPatch "contains HWEL";
CM_ SG_ 646 StatusDiagnosticFBD_HL_BLESWFKMa "contains BLESWFK";
CM_ SG_ 646 StatusDiagnosticFBD_HL_BLESWFKMi "contains BLESWFK";
CM_ SG_ 646 StatusDiagnosticFBD_HL_BLESWFKPa "contains BLESWFK";
CM_ SG_ 646 StatusDiagnosticFBD_HL_UWBSWFKMa "contains UWBSWFK";
CM_ SG_ 646 StatusDiagnosticFBD_HL_UWBSWFKMi "contains UWBSWFK";
CM_ SG_ 646 StatusDiagnosticFBD_HL_UWBSWFKPa "contains UWBSWFK";
CM_ SG_ 646 StatusDiagnosticFBD_HL_Bootloade "contains bootloader FWSK";
CM_ SG_ 646 StatusDiagnosticFBD_HL_Bootloa_2 "contains bootloader FWSK";
CM_ SG_ 646 StatusDiagnosticFBD_HL_Bootloa_3 "contains bootloader FWSK";
CM_ SG_ 646 StatusDiagnosticFBD_HL_Productio "contains production date";
CM_ SG_ 646 StatusDiagnosticFBD_HL_SerialNum "contains serial number";
CM_ SG_ 641 StatusDiagnosticFBD_HM_BMWPartNu "contains BMW part number, LSB";
CM_ SG_ 641 StatusDiagnosticFBD_HM_BMWPart_2 "contains BMW part number";
CM_ SG_ 641 StatusDiagnosticFBD_HM_BMWPart_3 "contains BMW part number";
CM_ SG_ 641 StatusDiagnosticFBD_HM_BMWPart_4 "contains BMW part number";
CM_ SG_ 641 StatusDiagnosticFBD_HM_BMWPart_5 "contains BMW part number";
CM_ SG_ 641 StatusDiagnosticFBD_HM_BMWPart_6 "contains BMW part number";
CM_ SG_ 641 StatusDiagnosticFBD_HM_BMWPart_7 "contains BMW part number, MSB";
CM_ SG_ 641 StatusDiagnosticFBD_HM_BMWPart_8 "contains BMW part number, AI";
CM_ SG_ 641 StatusDiagnosticFBD_HM_HWELMain "contains HWEL";
CM_ SG_ 641 StatusDiagnosticFBD_HM_HWELMinor "contains HWEL";
CM_ SG_ 641 StatusDiagnosticFBD_HM_HWELPatch "contains HWEL";
CM_ SG_ 641 StatusDiagnosticFBD_HM_BLESWFKMa "contains BLESWFK";
CM_ SG_ 641 StatusDiagnosticFBD_HM_BLESWFKMi "contains BLESWFK";
CM_ SG_ 641 StatusDiagnosticFBD_HM_BLESWFKPa "contains BLESWFK";
CM_ SG_ 641 StatusDiagnosticFBD_HM_UWBSWFKMa "contains UWBSWFK";
CM_ SG_ 641 StatusDiagnosticFBD_HM_UWBSWFKMi "contains UWBSWFK";
CM_ SG_ 641 StatusDiagnosticFBD_HM_UWBSWFKPa "contains UWBSWFK";
CM_ SG_ 641 StatusDiagnosticFBD_HM_Bootloade "contains bootloader FWSK";
CM_ SG_ 641 StatusDiagnosticFBD_HM_Bootloa_2 "contains bootloader FWSK";
CM_ SG_ 641 StatusDiagnosticFBD_HM_Bootloa_3 "contains bootloader FWSK";
CM_ SG_ 641 StatusDiagnosticFBD_HM_Productio "contains production date";
CM_ SG_ 641 StatusDiagnosticFBD_HM_SerialNum "contains serial number";
CM_ SG_ 647 StatusDiagnosticFBD_HR_BMWPartNu "contains BMW part number, LSB";
CM_ SG_ 647 StatusDiagnosticFBD_HR_BMWPart_2 "contains BMW part number";
CM_ SG_ 647 StatusDiagnosticFBD_HR_BMWPart_3 "contains BMW part number";
CM_ SG_ 647 StatusDiagnosticFBD_HR_BMWPart_4 "contains BMW part number";
CM_ SG_ 647 StatusDiagnosticFBD_HR_BMWPart_5 "contains BMW part number";
CM_ SG_ 647 StatusDiagnosticFBD_HR_BMWPart_6 "contains BMW part number";
CM_ SG_ 647 StatusDiagnosticFBD_HR_BMWPart_7 "contains BMW part number, MSB";
CM_ SG_ 647 StatusDiagnosticFBD_HR_BMWPart_8 "contains BMW part number, AI";
CM_ SG_ 647 StatusDiagnosticFBD_HR_HWELMain "contains HWEL";
CM_ SG_ 647 StatusDiagnosticFBD_HR_HWELMinor "contains HWEL";
CM_ SG_ 647 StatusDiagnosticFBD_HR_HWELPatch "contains HWEL";
CM_ SG_ 647 StatusDiagnosticFBD_HR_BLESWFKMa "contains BLESWFK";
CM_ SG_ 647 StatusDiagnosticFBD_HR_BLESWFKMi "contains BLESWFK";
CM_ SG_ 647 StatusDiagnosticFBD_HR_BLESWFKPa "contains BLESWFK";
CM_ SG_ 647 StatusDiagnosticFBD_HR_UWBSWFKMa "contains UWBSWFK";
CM_ SG_ 647 StatusDiagnosticFBD_HR_UWBSWFKMi "contains UWBSWFK";
CM_ SG_ 647 StatusDiagnosticFBD_HR_UWBSWFKPa "contains UWBSWFK";
CM_ SG_ 647 StatusDiagnosticFBD_HR_Bootloade "contains bootloader FWSK";
CM_ SG_ 647 StatusDiagnosticFBD_HR_Bootloa_2 "contains bootloader FWSK";
CM_ SG_ 647 StatusDiagnosticFBD_HR_Bootloa_3 "contains bootloader FWSK";
CM_ SG_ 647 StatusDiagnosticFBD_HR_Productio "contains production date";
CM_ SG_ 647 StatusDiagnosticFBD_HR_SerialNum "contains serial number";
CM_ SG_ 642 StatusDiagnosticFBD_Miko_BMWPart "contains BMW part number, LSB";
CM_ SG_ 642 StatusDiagnosticFBD_Miko_BMWPa_2 "contains BMW part number";
CM_ SG_ 642 StatusDiagnosticFBD_Miko_BMWPa_3 "contains BMW part number";
CM_ SG_ 642 StatusDiagnosticFBD_Miko_BMWPa_4 "contains BMW part number";
CM_ SG_ 642 StatusDiagnosticFBD_Miko_BMWPa_5 "contains BMW part number";
CM_ SG_ 642 StatusDiagnosticFBD_Miko_BMWPa_6 "contains BMW part number";
CM_ SG_ 642 StatusDiagnosticFBD_Miko_BMWPa_7 "contains BMW part number, MSB";
CM_ SG_ 642 StatusDiagnosticFBD_Miko_BMWPa_8 "contains BMW part number, AI";
CM_ SG_ 642 StatusDiagnosticFBD_Miko_HWELMai "contains HWEL";
CM_ SG_ 642 StatusDiagnosticFBD_Miko_HWELMin "contains HWEL";
CM_ SG_ 642 StatusDiagnosticFBD_Miko_HWELPat "contains HWEL";
CM_ SG_ 642 StatusDiagnosticFBD_Miko_BLESWFK "contains BLESWFK";
CM_ SG_ 642 StatusDiagnosticFBD_Miko_BLESW_2 "contains BLESWFK";
CM_ SG_ 642 StatusDiagnosticFBD_Miko_BLESW_3 "contains BLESWFK";
CM_ SG_ 642 StatusDiagnosticFBD_Miko_UWBSWFK "contains UWBSWFK";
CM_ SG_ 642 StatusDiagnosticFBD_Miko_UWBSW_2 "contains UWBSWFK";
CM_ SG_ 642 StatusDiagnosticFBD_Miko_UWBSW_3 "contains UWBSWFK";
CM_ SG_ 642 StatusDiagnosticFBD_Miko_Bootloa "contains bootloader FWSK";
CM_ SG_ 642 StatusDiagnosticFBD_Miko_Bootl_2 "contains bootloader FWSK";
CM_ SG_ 642 StatusDiagnosticFBD_Miko_Bootl_3 "contains bootloader FWSK";
CM_ SG_ 642 StatusDiagnosticFBD_Miko_Product "contains production date";
CM_ SG_ 642 StatusDiagnosticFBD_Miko_SerialN "contains serial number";
CM_ SG_ 864 StatusDiagnosticFBD_MM_BMWPartNu "contains BMW part number, LSB";
CM_ SG_ 864 StatusDiagnosticFBD_MM_BMWPart_2 "contains BMW part number";
CM_ SG_ 864 StatusDiagnosticFBD_MM_BMWPart_3 "contains BMW part number";
CM_ SG_ 864 StatusDiagnosticFBD_MM_BMWPart_4 "contains BMW part number";
CM_ SG_ 864 StatusDiagnosticFBD_MM_BMWPart_5 "contains BMW part number";
CM_ SG_ 864 StatusDiagnosticFBD_MM_BMWPart_6 "contains BMW part number";
CM_ SG_ 864 StatusDiagnosticFBD_MM_BMWPart_7 "contains BMW part number, MSB";
CM_ SG_ 864 StatusDiagnosticFBD_MM_BMWPart_8 "contains BMW part number, AI";
CM_ SG_ 864 StatusDiagnosticFBD_MM_HWELMain "contains HWEL";
CM_ SG_ 864 StatusDiagnosticFBD_MM_HWELMinor "contains HWEL";
CM_ SG_ 864 StatusDiagnosticFBD_MM_HWELPatch "contains HWEL";
CM_ SG_ 864 StatusDiagnosticFBD_MM_BLESWFKMa "contains BLESWFK";
CM_ SG_ 864 StatusDiagnosticFBD_MM_BLESWFKMi "contains BLESWFK";
CM_ SG_ 864 StatusDiagnosticFBD_MM_BLESWFKPa "contains BLESWFK";
CM_ SG_ 864 StatusDiagnosticFBD_MM_UWBSWFKMa "contains UWBSWFK";
CM_ SG_ 864 StatusDiagnosticFBD_MM_UWBSWFKMi "contains UWBSWFK";
CM_ SG_ 864 StatusDiagnosticFBD_MM_UWBSWFKPa "contains UWBSWFK";
CM_ SG_ 864 StatusDiagnosticFBD_MM_Bootloade "contains bootloader FWSK";
CM_ SG_ 864 StatusDiagnosticFBD_MM_Bootloa_2 "contains bootloader FWSK";
CM_ SG_ 864 StatusDiagnosticFBD_MM_Bootloa_3 "contains bootloader FWSK";
CM_ SG_ 864 StatusDiagnosticFBD_MM_Productio "contains production date";
CM_ SG_ 864 StatusDiagnosticFBD_MM_SerialNum "contains serial number";
CM_ SG_ 643 StatusDiagnosticFBD_Trunk_BMWPar "contains BMW part number, LSB";
CM_ SG_ 643 StatusDiagnosticFBD_Trunk_BMWP_2 "contains BMW part number";
CM_ SG_ 643 StatusDiagnosticFBD_Trunk_BMWP_3 "contains BMW part number";
CM_ SG_ 643 StatusDiagnosticFBD_Trunk_BMWP_4 "contains BMW part number";
CM_ SG_ 643 StatusDiagnosticFBD_Trunk_BMWP_5 "contains BMW part number";
CM_ SG_ 643 StatusDiagnosticFBD_Trunk_BMWP_6 "contains BMW part number";
CM_ SG_ 643 StatusDiagnosticFBD_Trunk_BMWP_7 "contains BMW part number, MSB";
CM_ SG_ 643 StatusDiagnosticFBD_Trunk_BMWP_8 "contains BMW part number, AI";
CM_ SG_ 643 StatusDiagnosticFBD_Trunk_HWELMa "contains HWEL";
CM_ SG_ 643 StatusDiagnosticFBD_Trunk_HWELMi "contains HWEL";
CM_ SG_ 643 StatusDiagnosticFBD_Trunk_HWELPa "contains HWEL";
CM_ SG_ 643 StatusDiagnosticFBD_Trunk_BLESWF "contains BLESWFK";
CM_ SG_ 643 StatusDiagnosticFBD_Trunk_BLES_2 "contains BLESWFK";
CM_ SG_ 643 StatusDiagnosticFBD_Trunk_BLES_3 "contains BLESWFK";
CM_ SG_ 643 StatusDiagnosticFBD_Trunk_UWBSWF "contains UWBSWFK";
CM_ SG_ 643 StatusDiagnosticFBD_Trunk_UWBS_2 "contains UWBSWFK";
CM_ SG_ 643 StatusDiagnosticFBD_Trunk_UWBS_3 "contains UWBSWFK";
CM_ SG_ 643 StatusDiagnosticFBD_Trunk_Bootlo "contains bootloader FWSK";
CM_ SG_ 643 StatusDiagnosticFBD_Trunk_Boot_2 "contains bootloader FWSK";
CM_ SG_ 643 StatusDiagnosticFBD_Trunk_Boot_3 "contains bootloader FWSK";
CM_ SG_ 643 StatusDiagnosticFBD_Trunk_Produc "contains production date";
CM_ SG_ 643 StatusDiagnosticFBD_Trunk_Serial "contains serial number";
CM_ SG_ 644 StatusDiagnosticFBD_VL_BMWPartNu "contains BMW part number, LSB";
CM_ SG_ 644 StatusDiagnosticFBD_VL_BMWPart_2 "contains BMW part number";
CM_ SG_ 644 StatusDiagnosticFBD_VL_BMWPart_3 "contains BMW part number";
CM_ SG_ 644 StatusDiagnosticFBD_VL_BMWPart_4 "contains BMW part number";
CM_ SG_ 644 StatusDiagnosticFBD_VL_BMWPart_5 "contains BMW part number";
CM_ SG_ 644 StatusDiagnosticFBD_VL_BMWPart_6 "contains BMW part number";
CM_ SG_ 644 StatusDiagnosticFBD_VL_BMWPart_7 "contains BMW part number, MSB";
CM_ SG_ 644 StatusDiagnosticFBD_VL_BMWPart_8 "contains BMW part number, AI";
CM_ SG_ 644 StatusDiagnosticFBD_VL_HWELMain "contains HWEL";
CM_ SG_ 644 StatusDiagnosticFBD_VL_HWELMinor "contains HWEL";
CM_ SG_ 644 StatusDiagnosticFBD_VL_HWELPatch "contains HWEL";
CM_ SG_ 644 StatusDiagnosticFBD_VL_BLESWFKMa "contains BLESWFK";
CM_ SG_ 644 StatusDiagnosticFBD_VL_BLESWFKMi "contains BLESWFK";
CM_ SG_ 644 StatusDiagnosticFBD_VL_BLESWFKPa "contains BLESWFK";
CM_ SG_ 644 StatusDiagnosticFBD_VL_UWBSWFKMa "contains UWBSWFK";
CM_ SG_ 644 StatusDiagnosticFBD_VL_UWBSWFKMi "contains UWBSWFK";
CM_ SG_ 644 StatusDiagnosticFBD_VL_UWBSWFKPa "contains UWBSWFK";
CM_ SG_ 644 StatusDiagnosticFBD_VL_Bootloade "contains bootloader FWSK";
CM_ SG_ 644 StatusDiagnosticFBD_VL_Bootloa_2 "contains bootloader FWSK";
CM_ SG_ 644 StatusDiagnosticFBD_VL_Bootloa_3 "contains bootloader FWSK";
CM_ SG_ 644 StatusDiagnosticFBD_VL_Productio "contains production date";
CM_ SG_ 644 StatusDiagnosticFBD_VL_SerialNum "contains serial number";
CM_ SG_ 640 StatusDiagnosticFBD_VM_BMWPartNu "contains BMW part number, LSB";
CM_ SG_ 640 StatusDiagnosticFBD_VM_BMWPart_2 "contains BMW part number";
CM_ SG_ 640 StatusDiagnosticFBD_VM_BMWPart_3 "contains BMW part number";
CM_ SG_ 640 StatusDiagnosticFBD_VM_BMWPart_4 "contains BMW part number";
CM_ SG_ 640 StatusDiagnosticFBD_VM_BMWPart_5 "contains BMW part number";
CM_ SG_ 640 StatusDiagnosticFBD_VM_BMWPart_6 "contains BMW part number";
CM_ SG_ 640 StatusDiagnosticFBD_VM_BMWPart_7 "contains BMW part number, MSB";
CM_ SG_ 640 StatusDiagnosticFBD_VM_BMWPart_8 "contains BMW part number, AI";
CM_ SG_ 640 StatusDiagnosticFBD_VM_HWELMain "contains HWEL";
CM_ SG_ 640 StatusDiagnosticFBD_VM_HWELMinor "contains HWEL";
CM_ SG_ 640 StatusDiagnosticFBD_VM_HWELPatch "contains HWEL";
CM_ SG_ 640 StatusDiagnosticFBD_VM_BLESWFKMa "contains BLESWFK";
CM_ SG_ 640 StatusDiagnosticFBD_VM_BLESWFKMi "contains BLESWFK";
CM_ SG_ 640 StatusDiagnosticFBD_VM_BLESWFKPa "contains BLESWFK";
CM_ SG_ 640 StatusDiagnosticFBD_VM_UWBSWFKMa "contains UWBSWFK";
CM_ SG_ 640 StatusDiagnosticFBD_VM_UWBSWFKMi "contains UWBSWFK";
CM_ SG_ 640 StatusDiagnosticFBD_VM_UWBSWFKPa "contains UWBSWFK";
CM_ SG_ 640 StatusDiagnosticFBD_VM_Bootloade "contains bootloader FWSK";
CM_ SG_ 640 StatusDiagnosticFBD_VM_Bootloa_2 "contains bootloader FWSK";
CM_ SG_ 640 StatusDiagnosticFBD_VM_Bootloa_3 "contains bootloader FWSK";
CM_ SG_ 640 StatusDiagnosticFBD_VM_Productio "contains production date";
CM_ SG_ 640 StatusDiagnosticFBD_VM_SerialNum "contains serial number";
CM_ SG_ 645 StatusDiagnosticFBD_VR_BMWPartNu "contains BMW part number, LSB";
CM_ SG_ 645 StatusDiagnosticFBD_VR_BMWPart_2 "contains BMW part number";
CM_ SG_ 645 StatusDiagnosticFBD_VR_BMWPart_3 "contains BMW part number";
CM_ SG_ 645 StatusDiagnosticFBD_VR_BMWPart_4 "contains BMW part number";
CM_ SG_ 645 StatusDiagnosticFBD_VR_BMWPart_5 "contains BMW part number";
CM_ SG_ 645 StatusDiagnosticFBD_VR_BMWPart_6 "contains BMW part number";
CM_ SG_ 645 StatusDiagnosticFBD_VR_BMWPart_7 "contains BMW part number, MSB";
CM_ SG_ 645 StatusDiagnosticFBD_VR_BMWPart_8 "contains BMW part number, AI";
CM_ SG_ 645 StatusDiagnosticFBD_VR_HWELMain "contains HWEL";
CM_ SG_ 645 StatusDiagnosticFBD_VR_HWELMinor "contains HWEL";
CM_ SG_ 645 StatusDiagnosticFBD_VR_HWELPatch "contains HWEL";
CM_ SG_ 645 StatusDiagnosticFBD_VR_BLESWFKMa "contains BLESWFK";
CM_ SG_ 645 StatusDiagnosticFBD_VR_BLESWFKMi "contains BLESWFK";
CM_ SG_ 645 StatusDiagnosticFBD_VR_BLESWFKPa "contains BLESWFK";
CM_ SG_ 645 StatusDiagnosticFBD_VR_UWBSWFKMa "contains UWBSWFK";
CM_ SG_ 645 StatusDiagnosticFBD_VR_UWBSWFKMi "contains UWBSWFK";
CM_ SG_ 645 StatusDiagnosticFBD_VR_UWBSWFKPa "contains UWBSWFK";
CM_ SG_ 645 StatusDiagnosticFBD_VR_Bootloade "contains bootloader FWSK";
CM_ SG_ 645 StatusDiagnosticFBD_VR_Bootloa_2 "contains bootloader FWSK";
CM_ SG_ 645 StatusDiagnosticFBD_VR_Bootloa_3 "contains bootloader FWSK";
CM_ SG_ 645 StatusDiagnosticFBD_VR_Productio "contains production date";
CM_ SG_ 645 StatusDiagnosticFBD_VR_SerialNum "contains serial number";
CM_ SG_ 156 StatusFBD_HL_PowerMode "contains actual power mode of FBD";
CM_ SG_ 156 StatusFBD_HL_ResetState "contains reset state";
CM_ SG_ 156 StatusFBD_HL_ResetReason "contains reset reason";
CM_ SG_ 156 StatusFBD_HL_BLEStatus "contains actual BLE status";
CM_ SG_ 156 StatusFBD_HL_UWBStatus "contains actual UWB status";
CM_ SG_ 156 StatusFBD_HL_WakeUpReason "contains the wakeup reason of the FBD";
CM_ SG_ 156 StatusFBD_HL_IRKListIndexWakeUpT "contains IRK list index of the Device which triggered wake up";
CM_ SG_ 156 StatusFBD_HL_Temperature "contains actual temperature of FBD";
CM_ SG_ 156 StatusFBD_HL_BLENumberOfBonding "contains actual number of bonded BLE devices";
CM_ SG_ 156 StatusFBD_HL_BLENumberActiveConn "contains actual number of active BLE connections";
CM_ SG_ 156 StatusFBD_HL_BLEChipPowerOnReset "contains actual number PowerOn resets of BLE chip";
CM_ SG_ 156 StatusFBD_HL_BLEChipSWResetCount "contains actual number SW resets of BLE chip";
CM_ SG_ 156 StatusFBD_HL_BLEChipWatchdogCoun "contains actual number watchdog resets of BLE chip";
CM_ SG_ 156 StatusFBD_HL_BLEChipTemperatureP "contains actual number temperature prewarnings of BLE chip";
CM_ SG_ 156 StatusFBD_HL_BLEChipThermalShutd "contains actual number thermal shutdowns of BLE chip";
CM_ SG_ 156 StatusFBD_HL_BLEChipErrorState "contains actual error state of BLE chip (read from \"Int_BLE_Status_ChipErrorState\")";
CM_ SG_ 156 StatusFBD_HL_UWBChipPowerOnReset "contains actual number PowerOn resets of UWB chip";
CM_ SG_ 156 StatusFBD_HL_UWBChipSWResetCount "contains actual number SW resets of UWB chip";
CM_ SG_ 156 StatusFBD_HL_UWBChipWatchdogCoun "contains actual number watchdog resets of UWB chip";
CM_ SG_ 156 StatusFBD_HL_UWBChipTemperatureP "contains actual number temperature prewarnings of UWB chip";
CM_ SG_ 156 StatusFBD_HL_UWBChipThermalShutd "contains actual number thermal shutdowns of UWB chip";
CM_ SG_ 156 StatusFBD_HL_UWBChipErrorState "contains actual error state of UWB chip";
CM_ SG_ 156 StatusFBD_HL_ProgrammingCounter "contains programming (flash) counter";
CM_ SG_ 156 StatusFBD_HL_ProgrammingErrorCou "contains programming error counter";
CM_ SG_ 156 StatusFBD_HL_SPIHangupCounter "contains SPI hangup counter";
CM_ SG_ 156 StatusFBD_HL_SBCChipTemperatureP "contains actual number temperature prewarnings of SBC chip";
CM_ SG_ 156 StatusFBD_HL_SBCChipThermalShutd "contains actual number thermal shutdowns of SBC chip";
CM_ SG_ 156 StatusFBD_HL_SBCErrorState "contains actual error state of SBC chip";
CM_ SG_ 156 StatusFBD_HL_OptionCode "contains option code";
CM_ SG_ 156 StatusFBD_HL_UWBCollisionCounter "contains UWB collision counter";
CM_ SG_ 156 StatusFBD_HL_DebugInformation1 "contains debug information 1";
CM_ SG_ 156 StatusFBD_HL_DebugInformation2 "contains debug information 2";
CM_ SG_ 151 StatusFBD_HM_PowerMode "contains actual power mode of FBD";
CM_ SG_ 151 StatusFBD_HM_ResetState "contains reset state";
CM_ SG_ 151 StatusFBD_HM_ResetReason "contains reset reason";
CM_ SG_ 151 StatusFBD_HM_BLEStatus "contains actual BLE status";
CM_ SG_ 151 StatusFBD_HM_UWBStatus "contains actual UWB status";
CM_ SG_ 151 StatusFBD_HM_WakeUpReason "contains the wakeup reason of the FBD";
CM_ SG_ 151 StatusFBD_HM_IRKListIndexWakeUpT "contains IRK list index of the Device which triggered wake up";
CM_ SG_ 151 StatusFBD_HM_Temperature "contains actual temperature of FBD";
CM_ SG_ 151 StatusFBD_HM_BLENumberOfBonding "contains actual number of bonded BLE devices";
CM_ SG_ 151 StatusFBD_HM_BLENumberActiveConn "contains actual number of active BLE connections";
CM_ SG_ 151 StatusFBD_HM_BLEChipPowerOnReset "contains actual number PowerOn resets of BLE chip";
CM_ SG_ 151 StatusFBD_HM_BLEChipSWResetCount "contains actual number SW resets of BLE chip";
CM_ SG_ 151 StatusFBD_HM_BLEChipWatchdogCoun "contains actual number watchdog resets of BLE chip";
CM_ SG_ 151 StatusFBD_HM_BLEChipTemperatureP "contains actual number temperature prewarnings of BLE chip";
CM_ SG_ 151 StatusFBD_HM_BLEChipThermalShutd "contains actual number thermal shutdowns of BLE chip";
CM_ SG_ 151 StatusFBD_HM_BLEChipErrorState "contains actual error state of BLE chip (read from \"Int_BLE_Status_ChipErrorState\")";
CM_ SG_ 151 StatusFBD_HM_UWBChipPowerOnReset "contains actual number PowerOn resets of UWB chip";
CM_ SG_ 151 StatusFBD_HM_UWBChipSWResetCount "contains actual number SW resets of UWB chip";
CM_ SG_ 151 StatusFBD_HM_UWBChipWatchdogCoun "contains actual number watchdog resets of UWB chip";
CM_ SG_ 151 StatusFBD_HM_UWBChipTemperatureP "contains actual number temperature prewarnings of UWB chip";
CM_ SG_ 151 StatusFBD_HM_UWBChipThermalShutd "contains actual number thermal shutdowns of UWB chip";
CM_ SG_ 151 StatusFBD_HM_UWBChipErrorState "contains actual error state of UWB chip";
CM_ SG_ 151 StatusFBD_HM_ProgrammingCounter "contains programming (flash) counter";
CM_ SG_ 151 StatusFBD_HM_ProgrammingErrorCou "contains programming error counter";
CM_ SG_ 151 StatusFBD_HM_SPIHangupCounter "contains SPI hangup counter";
CM_ SG_ 151 StatusFBD_HM_SBCChipTemperatureP "contains actual number temperature prewarnings of SBC chip";
CM_ SG_ 151 StatusFBD_HM_SBCChipThermalShutd "contains actual number thermal shutdowns of SBC chip";
CM_ SG_ 151 StatusFBD_HM_SBCErrorState "contains actual error state of SBC chip";
CM_ SG_ 151 StatusFBD_HM_OptionCode "contains option code";
CM_ SG_ 151 StatusFBD_HM_UWBCollisionCounter "contains UWB collision counter";
CM_ SG_ 151 StatusFBD_HM_DebugInformation1 "contains debug information 1";
CM_ SG_ 151 StatusFBD_HM_DebugInformation2 "contains debug information 2";
CM_ SG_ 157 StatusFBD_HR_PowerMode "contains actual power mode of FBD";
CM_ SG_ 157 StatusFBD_HR_ResetState "contains reset state";
CM_ SG_ 157 StatusFBD_HR_ResetReason "contains reset reason";
CM_ SG_ 157 StatusFBD_HR_BLEStatus "contains actual BLE status";
CM_ SG_ 157 StatusFBD_HR_UWBStatus "contains actual UWB status";
CM_ SG_ 157 StatusFBD_HR_WakeUpReason "contains the wakeup reason of the FBD";
CM_ SG_ 157 StatusFBD_HR_IRKListIndexWakeUpT "contains IRK list index of the Device which triggered wake up";
CM_ SG_ 157 StatusFBD_HR_Temperature "contains actual temperature of FBD";
CM_ SG_ 157 StatusFBD_HR_BLENumberOfBonding "contains actual number of bonded BLE devices";
CM_ SG_ 157 StatusFBD_HR_BLENumberActiveConn "contains actual number of active BLE connections";
CM_ SG_ 157 StatusFBD_HR_BLEChipPowerOnReset "contains actual number PowerOn resets of BLE chip";
CM_ SG_ 157 StatusFBD_HR_BLEChipSWResetCount "contains actual number SW resets of BLE chip";
CM_ SG_ 157 StatusFBD_HR_BLEChipWatchdogCoun "contains actual number watchdog resets of BLE chip";
CM_ SG_ 157 StatusFBD_HR_BLEChipTemperatureP "contains actual number temperature prewarnings of BLE chip";
CM_ SG_ 157 StatusFBD_HR_BLEChipThermalShutd "contains actual number thermal shutdowns of BLE chip";
CM_ SG_ 157 StatusFBD_HR_BLEChipErrorState "contains actual error state of BLE chip (read from \"Int_BLE_Status_ChipErrorState\")";
CM_ SG_ 157 StatusFBD_HR_UWBChipPowerOnReset "contains actual number PowerOn resets of UWB chip";
CM_ SG_ 157 StatusFBD_HR_UWBChipSWResetCount "contains actual number SW resets of UWB chip";
CM_ SG_ 157 StatusFBD_HR_UWBChipWatchdogCoun "contains actual number watchdog resets of UWB chip";
CM_ SG_ 157 StatusFBD_HR_UWBChipTemperatureP "contains actual number temperature prewarnings of UWB chip";
CM_ SG_ 157 StatusFBD_HR_UWBChipThermalShutd "contains actual number thermal shutdowns of UWB chip";
CM_ SG_ 157 StatusFBD_HR_UWBChipErrorState "contains actual error state of UWB chip";
CM_ SG_ 157 StatusFBD_HR_ProgrammingCounter "contains programming (flash) counter";
CM_ SG_ 157 StatusFBD_HR_ProgrammingErrorCou "contains programming error counter";
CM_ SG_ 157 StatusFBD_HR_SPIHangupCounter "contains SPI hangup counter";
CM_ SG_ 157 StatusFBD_HR_SBCChipTemperatureP "contains actual number temperature prewarnings of SBC chip";
CM_ SG_ 157 StatusFBD_HR_SBCChipThermalShutd "contains actual number thermal shutdowns of SBC chip";
CM_ SG_ 157 StatusFBD_HR_SBCErrorState "contains actual error state of SBC chip";
CM_ SG_ 157 StatusFBD_HR_OptionCode "contains option code";
CM_ SG_ 157 StatusFBD_HR_UWBCollisionCounter "contains UWB collision counter";
CM_ SG_ 157 StatusFBD_HR_DebugInformation1 "contains debug information 1";
CM_ SG_ 157 StatusFBD_HR_DebugInformation2 "contains debug information 2";
CM_ SG_ 152 StatusFBD_Miko_PowerMode "contains actual power mode of FBD";
CM_ SG_ 152 StatusFBD_Miko_ResetState "contains reset state";
CM_ SG_ 152 StatusFBD_Miko_ResetReason "contains reset reason";
CM_ SG_ 152 StatusFBD_Miko_BLEStatus "contains actual BLE status";
CM_ SG_ 152 StatusFBD_Miko_UWBStatus "contains actual UWB status";
CM_ SG_ 152 StatusFBD_Miko_WakeUpReason "contains the wakeup reason of the FBD";
CM_ SG_ 152 StatusFBD_Miko_IRKListIndexWakeU "contains IRK list index of the Device which triggered wake up";
CM_ SG_ 152 StatusFBD_Miko_Temperature "contains actual temperature of FBD";
CM_ SG_ 152 StatusFBD_Miko_BLENumberOfBondin "contains actual number of bonded BLE devices";
CM_ SG_ 152 StatusFBD_Miko_BLENumberActiveCo "contains actual number of active BLE connections";
CM_ SG_ 152 StatusFBD_Miko_BLEChipPowerOnRes "contains actual number PowerOn resets of BLE chip";
CM_ SG_ 152 StatusFBD_Miko_BLEChipSWResetCou "contains actual number SW resets of BLE chip";
CM_ SG_ 152 StatusFBD_Miko_BLEChipWatchdogCo "contains actual number watchdog resets of BLE chip";
CM_ SG_ 152 StatusFBD_Miko_BLEChipTemperatur "contains actual number temperature prewarnings of BLE chip";
CM_ SG_ 152 StatusFBD_Miko_BLEChipThermalShu "contains actual number thermal shutdowns of BLE chip";
CM_ SG_ 152 StatusFBD_Miko_BLEChipErrorState "contains actual error state of BLE chip (read from \"Int_BLE_Status_ChipErrorState\")";
CM_ SG_ 152 StatusFBD_Miko_UWBChipPowerOnRes "contains actual number PowerOn resets of UWB chip";
CM_ SG_ 152 StatusFBD_Miko_UWBChipSWResetCou "contains actual number SW resets of UWB chip";
CM_ SG_ 152 StatusFBD_Miko_UWBChipWatchdogCo "contains actual number watchdog resets of UWB chip";
CM_ SG_ 152 StatusFBD_Miko_UWBChipTemperatur "contains actual number temperature prewarnings of UWB chip";
CM_ SG_ 152 StatusFBD_Miko_UWBChipThermalShu "contains actual number thermal shutdowns of UWB chip";
CM_ SG_ 152 StatusFBD_Miko_UWBChipErrorState "contains actual error state of UWB chip";
CM_ SG_ 152 StatusFBD_Miko_ProgrammingCounte "contains programming (flash) counter";
CM_ SG_ 152 StatusFBD_Miko_ProgrammingErrorC "contains programming error counter";
CM_ SG_ 152 StatusFBD_Miko_SPIHangupCounter "contains SPI hangup counter";
CM_ SG_ 152 StatusFBD_Miko_SBCChipTemperatur "contains actual number temperature prewarnings of SBC chip";
CM_ SG_ 152 StatusFBD_Miko_SBCChipThermalShu "contains actual number thermal shutdowns of SBC chip";
CM_ SG_ 152 StatusFBD_Miko_SBCErrorState "contains actual error state of SBC chip";
CM_ SG_ 152 StatusFBD_Miko_OptionCode "contains option code";
CM_ SG_ 152 StatusFBD_Miko_UWBCollisionCount "contains UWB collision counter";
CM_ SG_ 152 StatusFBD_Miko_DebugInformation1 "contains debug information 1";
CM_ SG_ 152 StatusFBD_Miko_DebugInformation2 "contains debug information 2";
CM_ SG_ 815 StatusFBD_MM_PowerMode "contains actual power mode of FBD";
CM_ SG_ 815 StatusFBD_MM_ResetState "contains reset state";
CM_ SG_ 815 StatusFBD_MM_ResetReason "contains reset reason";
CM_ SG_ 815 StatusFBD_MM_BLEStatus "contains actual BLE status";
CM_ SG_ 815 StatusFBD_MM_UWBStatus "contains actual UWB status";
CM_ SG_ 815 StatusFBD_MM_WakeUpReason "contains WakeUpReason";
CM_ SG_ 815 StatusFBD_MM_IRKListIndexWakeUpT "contains IRKListIndex which wakes up";
CM_ SG_ 815 StatusFBD_MM_Temperature "contains actual temperature of FBD";
CM_ SG_ 815 StatusFBD_MM_BLENumberOfBonding "contains actual number of bonded BLE devices";
CM_ SG_ 815 StatusFBD_MM_BLENumberActiveConn "contains actual number of active BLE connections";
CM_ SG_ 815 StatusFBD_MM_BLEChipPowerOnReset "contains actual number PowerOn resets of BLE chip";
CM_ SG_ 815 StatusFBD_MM_BLEChipSWResetCount "contains actual number SW resets of BLE chip";
CM_ SG_ 815 StatusFBD_MM_BLEChipWatchdogCoun "contains actual number watchdog resets of BLE chip";
CM_ SG_ 815 StatusFBD_MM_BLEChipTemperatureP "contains actual number temperature prewarnings of BLE chip";
CM_ SG_ 815 StatusFBD_MM_BLEChipThermalShutd "contains actual number thermal shutdowns of BLE chip";
CM_ SG_ 815 StatusFBD_MM_BLEChipErrorState "contains actual error state of BLE chip (read from \"Int_BLE_Status_ChipErrorState\")";
CM_ SG_ 815 StatusFBD_MM_UWBChipPowerOnReset "contains actual number PowerOn resets of UWB chip";
CM_ SG_ 815 StatusFBD_MM_UWBChipSWResetCount "contains actual number SW resets of UWB chip";
CM_ SG_ 815 StatusFBD_MM_UWBChipWatchdogCoun "contains actual number watchdog resets of UWB chip";
CM_ SG_ 815 StatusFBD_MM_UWBChipTemperatureP "contains actual number temperature prewarnings of UWB chip";
CM_ SG_ 815 StatusFBD_MM_UWBChipThermalShutd "contains actual number thermal shutdowns of UWB chip";
CM_ SG_ 815 StatusFBD_MM_UWBChipErrorState "contains actual error state of UWB chip";
CM_ SG_ 815 StatusFBD_MM_ProgrammingCounter "contains programming (flash) counter";
CM_ SG_ 815 StatusFBD_MM_ProgrammingErrorCou "contains programming error counter";
CM_ SG_ 815 StatusFBD_MM_SPIHangupCounter "contains SPI hangup counter";
CM_ SG_ 815 StatusFBD_MM_SBCChipTemperatureP "contains actual number temperature prewarnings of SBC chip";
CM_ SG_ 815 StatusFBD_MM_SBCChipThermalShutd "contains actual number thermal shutdowns of SBC chip";
CM_ SG_ 815 StatusFBD_MM_SBCErrorState "contains actual error state of SBC chip";
CM_ SG_ 815 StatusFBD_MM_OptionCode "contains option code";
CM_ SG_ 815 StatusFBD_MM_UWBCollisionCounter "contains UWB collision counter";
CM_ SG_ 815 StatusFBD_MM_DebugInformation1 "contains debug information 1";
CM_ SG_ 815 StatusFBD_MM_DebugInformation2 "contains debug information 2";
CM_ SG_ 153 StatusFBD_Trunk_PowerMode "contains actual power mode of FBD";
CM_ SG_ 153 StatusFBD_Trunk_ResetState "contains reset state";
CM_ SG_ 153 StatusFBD_Trunk_ResetReason "contains reset reason";
CM_ SG_ 153 StatusFBD_Trunk_BLEStatus "contains actual BLE status";
CM_ SG_ 153 StatusFBD_Trunk_UWBStatus "contains actual UWB status";
CM_ SG_ 153 StatusFBD_Trunk_WakeUpReason "contains the wakeup reason of the FBD";
CM_ SG_ 153 StatusFBD_Trunk_IRKListIndexWake "contains IRK list index of the Device which triggered wake up";
CM_ SG_ 153 StatusFBD_Trunk_Temperature "contains actual temperature of FBD";
CM_ SG_ 153 StatusFBD_Trunk_BLENumberOfBondi "contains actual number of bonded BLE devices";
CM_ SG_ 153 StatusFBD_Trunk_BLENumberActiveC "contains actual number of active BLE connections";
CM_ SG_ 153 StatusFBD_Trunk_BLEChipPowerOnRe "contains actual number PowerOn resets of BLE chip";
CM_ SG_ 153 StatusFBD_Trunk_BLEChipSWResetCo "contains actual number SW resets of BLE chip";
CM_ SG_ 153 StatusFBD_Trunk_BLEChipWatchdogC "contains actual number watchdog resets of BLE chip";
CM_ SG_ 153 StatusFBD_Trunk_BLEChipTemperatu "contains actual number temperature prewarnings of BLE chip";
CM_ SG_ 153 StatusFBD_Trunk_BLEChipThermalSh "contains actual number thermal shutdowns of BLE chip";
CM_ SG_ 153 StatusFBD_Trunk_BLEChipErrorStat "contains actual error state of BLE chip (read from \"Int_BLE_Status_ChipErrorState\")";
CM_ SG_ 153 StatusFBD_Trunk_UWBChipPowerOnRe "contains actual number PowerOn resets of UWB chip";
CM_ SG_ 153 StatusFBD_Trunk_UWBChipSWResetCo "contains actual number SW resets of UWB chip";
CM_ SG_ 153 StatusFBD_Trunk_UWBChipWatchdogC "contains actual number watchdog resets of UWB chip";
CM_ SG_ 153 StatusFBD_Trunk_UWBChipTemperatu "contains actual number temperature prewarnings of UWB chip";
CM_ SG_ 153 StatusFBD_Trunk_UWBChipThermalSh "contains actual number thermal shutdowns of UWB chip";
CM_ SG_ 153 StatusFBD_Trunk_UWBChipErrorStat "contains actual error state of UWB chip";
CM_ SG_ 153 StatusFBD_Trunk_ProgrammingCount "contains programming (flash) counter";
CM_ SG_ 153 StatusFBD_Trunk_ProgrammingError "contains programming error counter";
CM_ SG_ 153 StatusFBD_Trunk_SPIHangupCounter "contains SPI hangup counter";
CM_ SG_ 153 StatusFBD_Trunk_SBCChipTemperatu "contains actual number temperature prewarnings of SBC chip";
CM_ SG_ 153 StatusFBD_Trunk_SBCChipThermalSh "contains actual number thermal shutdowns of SBC chip";
CM_ SG_ 153 StatusFBD_Trunk_SBCErrorState "contains actual error state of SBC chip";
CM_ SG_ 153 StatusFBD_Trunk_OptionCode "contains option code";
CM_ SG_ 153 StatusFBD_Trunk_UWBCollisionCoun "contains UWB collision counter";
CM_ SG_ 153 StatusFBD_Trunk_DebugInformation "contains debug information 1";
CM_ SG_ 153 StatusFBD_Trunk_DebugInformati_2 "contains debug information 2";
CM_ SG_ 154 StatusFBD_VL_PowerMode "contains actual power mode of FBD";
CM_ SG_ 154 StatusFBD_VL_ResetState "contains reset state";
CM_ SG_ 154 StatusFBD_VL_ResetReason "contains reset reason";
CM_ SG_ 154 StatusFBD_VL_BLEStatus "contains actual BLE status";
CM_ SG_ 154 StatusFBD_VL_UWBStatus "contains actual UWB status";
CM_ SG_ 154 StatusFBD_VL_WakeUpReason "contains the wakeup reason of the FBD";
CM_ SG_ 154 StatusFBD_VL_IRKListIndexWakeUpT "contains IRK list index of the Device which triggered wake up";
CM_ SG_ 154 StatusFBD_VL_Temperature "contains actual temperature of FBD";
CM_ SG_ 154 StatusFBD_VL_BLENumberOfBonding "contains actual number of bonded BLE devices";
CM_ SG_ 154 StatusFBD_VL_BLENumberActiveConn "contains actual number of active BLE connections";
CM_ SG_ 154 StatusFBD_VL_BLEChipPowerOnReset "contains actual number PowerOn resets of BLE chip";
CM_ SG_ 154 StatusFBD_VL_BLEChipSWResetCount "contains actual number SW resets of BLE chip";
CM_ SG_ 154 StatusFBD_VL_BLEChipWatchdogCoun "contains actual number watchdog resets of BLE chip";
CM_ SG_ 154 StatusFBD_VL_BLEChipTemperatureP "contains actual number temperature prewarnings of BLE chip";
CM_ SG_ 154 StatusFBD_VL_BLEChipThermalShutd "contains actual number thermal shutdowns of BLE chip";
CM_ SG_ 154 StatusFBD_VL_BLEChipErrorState "contains actual error state of BLE chip (read from \"Int_BLE_Status_ChipErrorState\")";
CM_ SG_ 154 StatusFBD_VL_UWBChipPowerOnReset "contains actual number PowerOn resets of UWB chip";
CM_ SG_ 154 StatusFBD_VL_UWBChipSWResetCount "contains actual number SW resets of UWB chip";
CM_ SG_ 154 StatusFBD_VL_UWBChipWatchdogCoun "contains actual number watchdog resets of UWB chip";
CM_ SG_ 154 StatusFBD_VL_UWBChipTemperatureP "contains actual number temperature prewarnings of UWB chip";
CM_ SG_ 154 StatusFBD_VL_UWBChipThermalShutd "contains actual number thermal shutdowns of UWB chip";
CM_ SG_ 154 StatusFBD_VL_UWBChipErrorState "contains actual error state of UWB chip";
CM_ SG_ 154 StatusFBD_VL_ProgrammingCounter "contains programming (flash) counter";
CM_ SG_ 154 StatusFBD_VL_ProgrammingErrorCou "contains programming error counter";
CM_ SG_ 154 StatusFBD_VL_SPIHangupCounter "contains SPI hangup counter";
CM_ SG_ 154 StatusFBD_VL_SBCChipTemperatureP "contains actual number temperature prewarnings of SBC chip";
CM_ SG_ 154 StatusFBD_VL_SBCChipThermalShutd "contains actual number thermal shutdowns of SBC chip";
CM_ SG_ 154 StatusFBD_VL_SBCErrorState "contains actual error state of SBC chip";
CM_ SG_ 154 StatusFBD_VL_OptionCode "contains option code";
CM_ SG_ 154 StatusFBD_VL_UWBCollisionCounter "contains UWB collision counter";
CM_ SG_ 154 StatusFBD_VL_DebugInformation1 "contains debug information 1";
CM_ SG_ 154 StatusFBD_VL_DebugInformation2 "contains debug information 2";
CM_ SG_ 150 StatusFBD_VM_PowerMode "contains actual power mode of FBD";
CM_ SG_ 150 StatusFBD_VM_ResetState "contains reset state";
CM_ SG_ 150 StatusFBD_VM_ResetReason "contains reset reason";
CM_ SG_ 150 StatusFBD_VM_BLEStatus "contains actual BLE status";
CM_ SG_ 150 StatusFBD_VM_UWBStatus "contains actual UWB status";
CM_ SG_ 150 StatusFBD_VM_WakeUpReason "contains the wakeup reason of the FBD";
CM_ SG_ 150 StatusFBD_VM_IRKListIndexWakeUpT "contains IRK list index of the Device which triggered wake up";
CM_ SG_ 150 StatusFBD_VM_Temperature "contains actual temperature of FBD";
CM_ SG_ 150 StatusFBD_VM_BLENumberOfBonding "contains actual number of bonded BLE devices";
CM_ SG_ 150 StatusFBD_VM_BLENumberActiveConn "contains actual number of active BLE connections";
CM_ SG_ 150 StatusFBD_VM_BLEChipPowerOnReset "contains actual number PowerOn resets of BLE chip";
CM_ SG_ 150 StatusFBD_VM_BLEChipSWResetCount "contains actual number SW resets of BLE chip";
CM_ SG_ 150 StatusFBD_VM_BLEChipWatchdogCoun "contains actual number watchdog resets of BLE chip";
CM_ SG_ 150 StatusFBD_VM_BLEChipTemperatureP "contains actual number temperature prewarnings of BLE chip";
CM_ SG_ 150 StatusFBD_VM_BLEChipThermalShutd "contains actual number thermal shutdowns of BLE chip";
CM_ SG_ 150 StatusFBD_VM_BLEChipErrorState "contains actual error state of BLE chip (read from \"Int_BLE_Status_ChipErrorState\")";
CM_ SG_ 150 StatusFBD_VM_UWBChipPowerOnReset "contains actual number PowerOn resets of UWB chip";
CM_ SG_ 150 StatusFBD_VM_UWBChipSWResetCount "contains actual number SW resets of UWB chip";
CM_ SG_ 150 StatusFBD_VM_UWBChipWatchdogCoun "contains actual number watchdog resets of UWB chip";
CM_ SG_ 150 StatusFBD_VM_UWBChipTemperatureP "contains actual number temperature prewarnings of UWB chip";
CM_ SG_ 150 StatusFBD_VM_UWBChipThermalShutd "contains actual number thermal shutdowns of UWB chip";
CM_ SG_ 150 StatusFBD_VM_UWBChipErrorState "contains actual error state of UWB chip";
CM_ SG_ 150 StatusFBD_VM_ProgrammingCounter "contains programming (flash) counter";
CM_ SG_ 150 StatusFBD_VM_ProgrammingErrorCou "contains programming error counter";
CM_ SG_ 150 StatusFBD_VM_SPIHangupCounter "contains SPI hangup counter";
CM_ SG_ 150 StatusFBD_VM_SBCChipTemperatureP "contains actual number temperature prewarnings of SBC chip";
CM_ SG_ 150 StatusFBD_VM_SBCChipThermalShutd "contains actual number thermal shutdowns of SBC chip";
CM_ SG_ 150 StatusFBD_VM_SBCErrorState "contains actual error state of SBC chip";
CM_ SG_ 150 StatusFBD_VM_OptionCode "contains option code";
CM_ SG_ 150 StatusFBD_VM_UWBCollisionCounter "contains UWB collision counter";
CM_ SG_ 150 StatusFBD_VM_DebugInformation1 "contains debug information 1";
CM_ SG_ 150 StatusFBD_VM_DebugInformation2 "contains debug information 2";
CM_ SG_ 155 StatusFBD_VR_PowerMode "contains actual power mode of FBD";
CM_ SG_ 155 StatusFBD_VR_ResetState "contains reset state";
CM_ SG_ 155 StatusFBD_VR_ResetReason "contains reset reason";
CM_ SG_ 155 StatusFBD_VR_BLEStatus "contains actual BLE status";
CM_ SG_ 155 StatusFBD_VR_UWBStatus "contains actual UWB status";
CM_ SG_ 155 StatusFBD_VR_WakeUpReason "contains the wakeup reason of the FBD";
CM_ SG_ 155 StatusFBD_VR_IRKListIndexWakeUpT "contains IRK list index of the Device which triggered wake up";
CM_ SG_ 155 StatusFBD_VR_Temperature "contains actual temperature of FBD";
CM_ SG_ 155 StatusFBD_VR_BLENumberOfBonding "contains actual number of bonded BLE devices";
CM_ SG_ 155 StatusFBD_VR_BLENumberActiveConn "contains actual number of active BLE connections";
CM_ SG_ 155 StatusFBD_VR_BLEChipPowerOnReset "contains actual number PowerOn resets of BLE chip";
CM_ SG_ 155 StatusFBD_VR_BLEChipSWResetCount "contains actual number SW resets of BLE chip";
CM_ SG_ 155 StatusFBD_VR_BLEChipWatchdogCoun "contains actual number watchdog resets of BLE chip";
CM_ SG_ 155 StatusFBD_VR_BLEChipTemperatureP "contains actual number temperature prewarnings of BLE chip";
CM_ SG_ 155 StatusFBD_VR_BLEChipThermalShutd "contains actual number thermal shutdowns of BLE chip";
CM_ SG_ 155 StatusFBD_VR_BLEChipErrorState "contains actual error state of BLE chip (read from \"Int_BLE_Status_ChipErrorState\")";
CM_ SG_ 155 StatusFBD_VR_UWBChipPowerOnReset "contains actual number PowerOn resets of UWB chip";
CM_ SG_ 155 StatusFBD_VR_UWBChipSWResetCount "contains actual number SW resets of UWB chip";
CM_ SG_ 155 StatusFBD_VR_UWBChipWatchdogCoun "contains actual number watchdog resets of UWB chip";
CM_ SG_ 155 StatusFBD_VR_UWBChipTemperatureP "contains actual number temperature prewarnings of UWB chip";
CM_ SG_ 155 StatusFBD_VR_UWBChipThermalShutd "contains actual number thermal shutdowns of UWB chip";
CM_ SG_ 155 StatusFBD_VR_UWBChipErrorState "contains actual error state of UWB chip";
CM_ SG_ 155 StatusFBD_VR_ProgrammingCounter "contains programming (flash) counter";
CM_ SG_ 155 StatusFBD_VR_ProgrammingErrorCou "contains programming error counter";
CM_ SG_ 155 StatusFBD_VR_SPIHangupCounter "contains SPI hangup counter";
CM_ SG_ 155 StatusFBD_VR_SBCChipTemperatureP "contains actual number temperature prewarnings of SBC chip";
CM_ SG_ 155 StatusFBD_VR_SBCChipThermalShutd "contains actual number thermal shutdowns of SBC chip";
CM_ SG_ 155 StatusFBD_VR_SBCErrorState "contains actual error state of SBC chip";
CM_ SG_ 155 StatusFBD_VR_OptionCode "contains option code";
CM_ SG_ 155 StatusFBD_VR_UWBCollisionCounter "contains UWB collision counter";
CM_ SG_ 155 StatusFBD_VR_DebugInformation1 "contains debug information 1";
CM_ SG_ 155 StatusFBD_VR_DebugInformation2 "contains debug information 2";
CM_ SG_ 226 StatusIRKConfigurationFBD_HL_Lis "contains list index";
CM_ SG_ 226 StatusIRKConfigurationFBD_HL_Cha "contains channel index";
CM_ SG_ 226 StatusIRKConfigurationFBD_HL_Con "contains configuration";
CM_ SG_ 221 StatusIRKConfigurationFBD_HM_Lis "contains list index";
CM_ SG_ 221 StatusIRKConfigurationFBD_HM_Cha "contains channel index";
CM_ SG_ 221 StatusIRKConfigurationFBD_HM_Con "contains configuration";
CM_ SG_ 227 StatusIRKConfigurationFBD_HR_Lis "contains list index";
CM_ SG_ 227 StatusIRKConfigurationFBD_HR_Cha "contains channel index";
CM_ SG_ 227 StatusIRKConfigurationFBD_HR_Con "contains configuration";
CM_ SG_ 222 StatusIRKConfigurationFBD_Miko_L "contains list index";
CM_ SG_ 222 StatusIRKConfigurationFBD_Miko_C "contains channel index";
CM_ SG_ 222 StatusIRKConfigurationFBD_Miko_2 "contains configuration";
CM_ SG_ 241 StatusIRKConfigurationFBD_MM_Lis "contains list index";
CM_ SG_ 241 StatusIRKConfigurationFBD_MM_Cha "contains channel index";
CM_ SG_ 241 StatusIRKConfigurationFBD_MM_Con "contains configuration";
CM_ SG_ 223 StatusIRKConfigurationFBD_Trunk_ "contains list index";
CM_ SG_ 223 StatusIRKConfigurationFBD_Trun_2 "contains channel index";
CM_ SG_ 223 StatusIRKConfigurationFBD_Trun_3 "contains configuration";
CM_ SG_ 224 StatusIRKConfigurationFBD_VL_Lis "contains list index";
CM_ SG_ 224 StatusIRKConfigurationFBD_VL_Cha "contains channel index";
CM_ SG_ 224 StatusIRKConfigurationFBD_VL_Con "contains configuration";
CM_ SG_ 220 StatusIRKConfigurationFBD_VM_Lis "contains list index";
CM_ SG_ 220 StatusIRKConfigurationFBD_VM_Cha "contains channel index";
CM_ SG_ 220 StatusIRKConfigurationFBD_VM_Con "contains configuration";
CM_ SG_ 225 StatusIRKConfigurationFBD_VR_Lis "contains list index";
CM_ SG_ 225 StatusIRKConfigurationFBD_VR_Cha "contains channel index";
CM_ SG_ 225 StatusIRKConfigurationFBD_VR_Con "contains configuration";
CM_ SG_ 236 StatusRangingIntentFBD_HL_IRKLis "contains IRK List ID";
CM_ SG_ 236 StatusRangingIntentFBD_HL_Intent "Contains intent confidence";
CM_ SG_ 231 StatusRangingIntentFBD_HM_IRKLis "contains IRK List ID";
CM_ SG_ 231 StatusRangingIntentFBD_HM_Intent "Contains intent confidence";
CM_ SG_ 237 StatusRangingIntentFBD_HR_IRKLis "contains IRK List ID";
CM_ SG_ 237 StatusRangingIntentFBD_HR_Intent "Contains intent confidence";
CM_ SG_ 232 StatusRangingIntentFBD_Miko_IRKL "contains IRK List ID";
CM_ SG_ 232 StatusRangingIntentFBD_Miko_Inte "Contains intent confidence";
CM_ SG_ 242 StatusRangingIntentFBD_MM_IRKLis "contains IRK List ID";
CM_ SG_ 242 StatusRangingIntentFBD_MM_Intent "Contains intent confidence";
CM_ SG_ 233 StatusRangingIntentFBD_Trunk_IRK "contains IRK List ID";
CM_ SG_ 233 StatusRangingIntentFBD_Trunk_Int "Contains intent confidence";
CM_ SG_ 234 StatusRangingIntentFBD_VL_IRKLis "contains IRK List ID";
CM_ SG_ 234 StatusRangingIntentFBD_VL_Intent "Contains intent confidence";
CM_ SG_ 230 StatusRangingIntentFBD_VM_IRKLis "contains IRK List ID";
CM_ SG_ 230 StatusRangingIntentFBD_VM_Intent "Contains intent confidence";
CM_ SG_ 235 StatusRangingIntentFBD_VR_IRKLis "contains IRK List ID";
CM_ SG_ 235 StatusRangingIntentFBD_VR_Intent "Contains intent confidence";
CM_ SG_ 426 StatusRangingSessionFBD_HL_Sessi "ACK zu SessionSetup, CtrRangingSession, …";
CM_ SG_ 426 StatusRangingSessionFBD_HL_Rangi "contains Frame Index";
CM_ SG_ 426 StatusRangingSessionFBD_HL_Funct "Start, Stop, Suspend, Resume, Delete a Session";
CM_ SG_ 426 StatusRangingSessionFBD_HL_Setup "ACK, NACK of SessionSetup";
CM_ SG_ 426 StatusRangingSessionFBD_HL_Start "ACK, NACK of SessionStart";
CM_ SG_ 426 StatusRangingSessionFBD_HL_Suspe "ACK, NACK of SessionSuspend";
CM_ SG_ 426 StatusRangingSessionFBD_HL_Resum "ACK, NACK of SessionResume";
CM_ SG_ 426 StatusRangingSessionFBD_HL_Statu "status of FBD6";
CM_ SG_ 426 StatusRangingSessionFBD_HL_Error "error code of FBD6";
CM_ SG_ 426 StatusRangingSessionFBD_HL_Diag1 "diagnose information of FBD6";
CM_ SG_ 426 StatusRangingSessionFBD_HL_Diag2 "diagnose information of FBD6";
CM_ SG_ 426 StatusRangingSessionFBD_HL_Diag3 "diagnose information of FBD6";
CM_ SG_ 421 StatusRangingSessionFBD_HM_Sessi "ACK zu SessionSetup, CtrRangingSession, …";
CM_ SG_ 421 StatusRangingSessionFBD_HM_Frame "contains Frame Index";
CM_ SG_ 421 StatusRangingSessionFBD_HM_Funct "Start, Stop, Suspend, Resume, Delete a Session";
CM_ SG_ 421 StatusRangingSessionFBD_HM_Setup "ACK, NACK of SessionSetup";
CM_ SG_ 421 StatusRangingSessionFBD_HM_Start "ACK, NACK of SessionStart";
CM_ SG_ 421 StatusRangingSessionFBD_HM_Suspe "ACK, NACK of SessionSuspend";
CM_ SG_ 421 StatusRangingSessionFBD_HM_Resum "ACK, NACK of SessionResume";
CM_ SG_ 421 StatusRangingSessionFBD_HM_Statu "status of FBD6";
CM_ SG_ 421 StatusRangingSessionFBD_HM_Error "error code of FBD6";
CM_ SG_ 421 StatusRangingSessionFBD_HM_Diag1 "diagnose information of FBD6";
CM_ SG_ 421 StatusRangingSessionFBD_HM_Diag2 "diagnose information of FBD6";
CM_ SG_ 421 StatusRangingSessionFBD_HM_Diag3 "diagnose information of FBD6";
CM_ SG_ 427 StatusRangingSessionFBD_HR_Sessi "ACK zu SessionSetup, CtrRangingSession, …";
CM_ SG_ 427 StatusRangingSessionFBD_HR_Frame "contains Frame Index";
CM_ SG_ 427 StatusRangingSessionFBD_HR_Funct "Start, Stop, Suspend, Resume, Delete a Session";
CM_ SG_ 427 StatusRangingSessionFBD_HR_Setup "ACK, NACK of SessionSetup";
CM_ SG_ 427 StatusRangingSessionFBD_HR_Start "ACK, NACK of SessionStart";
CM_ SG_ 427 StatusRangingSessionFBD_HR_Suspe "ACK, NACK of SessionSuspend";
CM_ SG_ 427 StatusRangingSessionFBD_HR_Resum "ACK, NACK of SessionResume";
CM_ SG_ 427 StatusRangingSessionFBD_HR_Statu "status of FBD6";
CM_ SG_ 427 StatusRangingSessionFBD_HR_Error "error code of FBD6";
CM_ SG_ 427 StatusRangingSessionFBD_HR_Diag1 "diagnose information of FBD6";
CM_ SG_ 427 StatusRangingSessionFBD_HR_Diag2 "diagnose information of FBD6";
CM_ SG_ 427 StatusRangingSessionFBD_HR_Diag3 "diagnose information of FBD6";
CM_ SG_ 422 StatusRangingSessionFBD_Miko_Ses "ACK zu SessionSetup, CtrRangingSession, …";
CM_ SG_ 422 StatusRangingSessionFBD_Miko_Fra "contains Frame Index";
CM_ SG_ 422 StatusRangingSessionFBD_Miko_Fun "Start, Stop, Suspend, Resume, Delete a Session";
CM_ SG_ 422 StatusRangingSessionFBD_Miko_Set "ACK, NACK of SessionSetup";
CM_ SG_ 422 StatusRangingSessionFBD_Miko_Sta "ACK, NACK of SessionStart";
CM_ SG_ 422 StatusRangingSessionFBD_Miko_Sus "ACK, NACK of SessionSuspend";
CM_ SG_ 422 StatusRangingSessionFBD_Miko_Res "ACK, NACK of SessionResume";
CM_ SG_ 422 StatusRangingSessionFBD_Miko_S_2 "status of FBD6";
CM_ SG_ 422 StatusRangingSessionFBD_Miko_Err "error code of FBD6";
CM_ SG_ 422 StatusRangingSessionFBD_Miko_Dia "diagnose information of FBD6";
CM_ SG_ 422 StatusRangingSessionFBD_Miko_D_2 "diagnose information of FBD6";
CM_ SG_ 422 StatusRangingSessionFBD_Miko_D_3 "diagnose information of FBD6";
CM_ SG_ 440 StatusRangingSessionFBD_MM_Sessi "ACK zu SessionSetup, CtrRangingSession, …";
CM_ SG_ 440 StatusRangingSessionFBD_MM_Frame "contains Frame Index";
CM_ SG_ 440 StatusRangingSessionFBD_MM_Funct "Start, Stop, Suspend, Resume, Delete a Session";
CM_ SG_ 440 StatusRangingSessionFBD_MM_Setup "ACK, NACK of SessionSetup";
CM_ SG_ 440 StatusRangingSessionFBD_MM_Start "ACK, NACK of SessionStart";
CM_ SG_ 440 StatusRangingSessionFBD_MM_Suspe "ACK, NACK of SessionSuspend";
CM_ SG_ 440 StatusRangingSessionFBD_MM_Resum "ACK, NACK of SessionResume";
CM_ SG_ 440 StatusRangingSessionFBD_MM_Statu "status of FBD6";
CM_ SG_ 440 StatusRangingSessionFBD_MM_Error "error code of FBD6";
CM_ SG_ 440 StatusRangingSessionFBD_MM_Diag1 "diagnose information of FBD6";
CM_ SG_ 440 StatusRangingSessionFBD_MM_Diag2 "diagnose information of FBD6";
CM_ SG_ 440 StatusRangingSessionFBD_MM_Diag3 "diagnose information of FBD6";
CM_ SG_ 423 StatusRangingSessionFBD_Trunk_Se "ACK zu SessionSetup, CtrRangingSession, …";
CM_ SG_ 423 StatusRangingSessionFBD_Trunk_Fr "contains Frame Index";
CM_ SG_ 423 StatusRangingSessionFBD_Trunk_Fu "Start, Stop, Suspend, Resume, Delete a Session";
CM_ SG_ 423 StatusRangingSessionFBD_Trunk__2 "ACK, NACK of SessionSetup";
CM_ SG_ 423 StatusRangingSessionFBD_Trunk_St "ACK, NACK of SessionStart";
CM_ SG_ 423 StatusRangingSessionFBD_Trunk_Su "ACK, NACK of SessionSuspend";
CM_ SG_ 423 StatusRangingSessionFBD_Trunk_Re "ACK, NACK of SessionResume";
CM_ SG_ 423 StatusRangingSessionFBD_Trunk__3 "status of FBD6";
CM_ SG_ 423 StatusRangingSessionFBD_Trunk_Er "error code of FBD6";
CM_ SG_ 423 StatusRangingSessionFBD_Trunk_Di "diagnose information of FBD6";
CM_ SG_ 423 StatusRangingSessionFBD_Trunk__4 "diagnose information of FBD6";
CM_ SG_ 423 StatusRangingSessionFBD_Trunk__5 "diagnose information of FBD6";
CM_ SG_ 424 StatusRangingSessionFBD_VL_Sessi "ACK zu SessionSetup, CtrRangingSession, …";
CM_ SG_ 424 StatusRangingSessionFBD_VL_Frame "contains Frame Index";
CM_ SG_ 424 StatusRangingSessionFBD_VL_Funct "Start, Stop, Suspend, Resume, Delete a Session";
CM_ SG_ 424 StatusRangingSessionFBD_VL_Setup "ACK, NACK of SessionSetup";
CM_ SG_ 424 StatusRangingSessionFBD_VL_Start "ACK, NACK of SessionStart";
CM_ SG_ 424 StatusRangingSessionFBD_VL_Suspe "ACK, NACK of SessionSuspend";
CM_ SG_ 424 StatusRangingSessionFBD_VL_Resum "ACK, NACK of SessionResume";
CM_ SG_ 424 StatusRangingSessionFBD_VL_Statu "status of FBD6";
CM_ SG_ 424 StatusRangingSessionFBD_VL_Error "error code of FBD6";
CM_ SG_ 424 StatusRangingSessionFBD_VL_Diag1 "diagnose information of FBD6";
CM_ SG_ 424 StatusRangingSessionFBD_VL_Diag2 "diagnose information of FBD6";
CM_ SG_ 424 StatusRangingSessionFBD_VL_Diag3 "diagnose information of FBD6";
CM_ SG_ 420 StatusRangingSessionFBD_VM_Sessi "ACK zu SessionSetup, CtrRangingSession, …";
CM_ SG_ 420 StatusRangingSessionFBD_VM_Frame "contains Frame Index";
CM_ SG_ 420 StatusRangingSessionFBD_VM_Funct "Start, Stop, Suspend, Resume, Delete a Session";
CM_ SG_ 420 StatusRangingSessionFBD_VM_Setup "ACK, NACK of SessionSetup";
CM_ SG_ 420 StatusRangingSessionFBD_VM_Start "ACK, NACK of SessionStart";
CM_ SG_ 420 StatusRangingSessionFBD_VM_Suspe "ACK, NACK of SessionSuspend";
CM_ SG_ 420 StatusRangingSessionFBD_VM_Resum "ACK, NACK of SessionResume";
CM_ SG_ 420 StatusRangingSessionFBD_VM_Statu "status of FBD6";
CM_ SG_ 420 StatusRangingSessionFBD_VM_Error "error code of FBD6";
CM_ SG_ 420 StatusRangingSessionFBD_VM_Diag1 "diagnose information of FBD6";
CM_ SG_ 420 StatusRangingSessionFBD_VM_Diag2 "diagnose information of FBD6";
CM_ SG_ 420 StatusRangingSessionFBD_VM_Diag3 "diagnose information of FBD6";
CM_ SG_ 425 StatusRangingSessionFBD_VR_Sessi "ACK zu SessionSetup, CtrRangingSession, …";
CM_ SG_ 425 StatusRangingSessionFBD_VR_Frame "contains Frame Index";
CM_ SG_ 425 StatusRangingSessionFBD_VR_Funct "Start, Stop, Suspend, Resume, Delete a Session";
CM_ SG_ 425 StatusRangingSessionFBD_VR_Setup "ACK, NACK of SessionSetup";
CM_ SG_ 425 StatusRangingSessionFBD_VR_Start "ACK, NACK of SessionStart";
CM_ SG_ 425 StatusRangingSessionFBD_VR_Suspe "ACK, NACK of SessionSuspend";
CM_ SG_ 425 StatusRangingSessionFBD_VR_Resum "ACK, NACK of SessionResume";
CM_ SG_ 425 StatusRangingSessionFBD_VR_Statu "status of FBD6";
CM_ SG_ 425 StatusRangingSessionFBD_VR_Error "error code of FBD6";
CM_ SG_ 425 StatusRangingSessionFBD_VR_Diag1 "diagnose information of FBD6";
CM_ SG_ 425 StatusRangingSessionFBD_VR_Diag2 "diagnose information of FBD6";
CM_ SG_ 425 StatusRangingSessionFBD_VR_Diag3 "diagnose information of FBD6";
CM_ SG_ 476 StatusRangingSessionSignFBD_HL_S "contains Session-ID";
CM_ SG_ 476 StatusRangingSessionSignFBD_HL_F "contains Frame Index";
CM_ SG_ 476 StatusRangingSessionSignFBD_HL_2 "contains signature, only signal TAG 0xFF possible";
CM_ SG_ 471 StatusRangingSessionSignFBD_HM_S "contains Session-ID";
CM_ SG_ 471 StatusRangingSessionFBD_HM_Rangi "contains Frame Index";
CM_ SG_ 471 StatusRangingSessionSignFBD_HM_2 "contains signature, only signal TAG 0xFF possible";
CM_ SG_ 477 StatusRangingSessionSignFBD_HR_S "contains Session-ID";
CM_ SG_ 477 StatusRangingSessionFBD_HR_Rangi "contains Frame Index";
CM_ SG_ 477 StatusRangingSessionSignFBD_HR_2 "contains signature, only signal TAG 0xFF possible";
CM_ SG_ 472 StatusRangingSessionSignFBD_Miko "contains Session-ID";
CM_ SG_ 472 StatusRangingSessionFBD_Miko_Ran "contains Frame Index";
CM_ SG_ 472 StatusRangingSessionSignFBD_Mi_2 "contains signature, only signal TAG 0xFF possible";
CM_ SG_ 441 StatusRangingSessionSignFBD_MM_S "contains Session-ID";
CM_ SG_ 441 StatusRangingSessionFBD_MM_Rangi "contains Frame Index";
CM_ SG_ 441 StatusRangingSessionSignFBD_MM_2 "contains signature, only signal TAG 0xFF possible";
CM_ SG_ 473 StatusRangingSessionSignFBD_Trun "contains Session-ID";
CM_ SG_ 473 StatusRangingSessionFBD_Trunk_Ra "contains Frame Index";
CM_ SG_ 473 StatusRangingSessionSignFBD_Tr_2 "contains signature, only signal TAG 0xFF possible";
CM_ SG_ 474 StatusRangingSessionSignFBD_VL_S "contains Session-ID";
CM_ SG_ 474 StatusRangingSessionFBD_VL_Rangi "contains Frame Index";
CM_ SG_ 474 StatusRangingSessionSignFBD_VL_2 "contains signature, only signal TAG 0xFF possible";
CM_ SG_ 470 StatusRangingSessionSignFBD_VM_S "contains Session-ID";
CM_ SG_ 470 StatusRangingSessionFBD_VM_Rangi "contains Frame Index";
CM_ SG_ 470 StatusRangingSessionSignFBD_VM_2 "contains signature, only signal TAG 0xFF possible";
CM_ SG_ 475 StatusRangingSessionSignFBD_VR_S "contains Session-ID";
CM_ SG_ 475 StatusRangingSessionFBD_VR_Rangi "contains Frame Index";
CM_ SG_ 475 StatusRangingSessionSignFBD_VR_2 "contains signature, only signal TAG 0xFF possible";
CM_ SG_ 126 StatusTimeSyncFBD_HL_Status "contains status to TimeSync";
CM_ SG_ 126 StatusTimeSyncFBD_HL_ReSyncCorre "contains deviation to TimeSync";
CM_ SG_ 121 StatusTimeSyncFBD_HM_Status "contains status to TimeSync";
CM_ SG_ 121 StatusTimeSyncFBD_HM_ReSyncCorre "contains deviation to TimeSync";
CM_ SG_ 127 StatusTimeSyncFBD_HR_Status "contains status to TimeSync";
CM_ SG_ 127 StatusTimeSyncFBD_HR_ReSyncCorre "contains deviation to TimeSync";
CM_ SG_ 122 StatusTimeSyncFBD_Miko_Status "contains status to TimeSync";
CM_ SG_ 122 StatusTimeSyncFBD_Miko_ReSyncCor "contains deviation to TimeSync";
CM_ SG_ 812 StatusTimeSyncFBD_MM_Status "contains status to TimeSync";
CM_ SG_ 812 StatusTimeSyncFBD_MM_ReSyncCorre "contains deviation to TimeSync";
CM_ SG_ 128 StatusTimeSyncFBD_SML_Status "contains status to TimeSync";
CM_ SG_ 128 StatusTimeSyncFBD_SML_ReSyncCorr "contains deviation to TimeSync";
CM_ SG_ 129 StatusTimeSyncFBD_SMR_Status "contains status to TimeSync";
CM_ SG_ 129 StatusTimeSyncFBD_SMR_ReSyncCorr "contains deviation to TimeSync";
CM_ SG_ 123 StatusTimeSyncFBD_Trunk_Status "contains status to TimeSync";
CM_ SG_ 123 StatusTimeSyncFBD_Trunk_ReSyncCo "contains deviation to TimeSync";
CM_ SG_ 124 StatusTimeSyncFBD_VL_Status "contains status to TimeSync";
CM_ SG_ 124 StatusTimeSyncFBD_VL_ReSyncCorre "contains deviation to TimeSync";
CM_ SG_ 120 StatusTimeSyncFBD_VM_Status "contains status to TimeSync";
CM_ SG_ 120 StatusTimeSyncFBD_VM_ReSyncCorre "contains deviation to TimeSync";
CM_ SG_ 125 StatusTimeSyncFBD_VR_Status "contains status to TimeSync";
CM_ SG_ 125 StatusTimeSyncFBD_VR_ReSyncCorre "contains deviation to TimeSync";
CM_ SG_ 436 StatusUWBRangingFBD_HL_SessionID "contains Session-ID";
CM_ SG_ 436 StatusUWBRangingFBD_HL_TimeOfFli "ranging result in ps (PH) = (DEC) * 15.65";
CM_ SG_ 436 StatusUWBRangingFBD_HL_RangingBl "contains Frame Index";
CM_ SG_ 436 StatusUWBRangingFBD_HL_RangingRo "contains Hopping Offset";
CM_ SG_ 436 StatusUWBRangingFBD_HL_OverallRe "overall receive power (Range: -127 ... -1 dB / step: 0.5dB)";
CM_ SG_ 436 StatusUWBRangingFBD_HL_FirstPath "first path power (Range: -127 ... -1 dB / step: 0.5dB)";
CM_ SG_ 436 StatusUWBRangingFBD_HL_AngleOfAr "first path AoA";
CM_ SG_ 436 StatusUWBRangingFBD_HL_PhaseDiff "indicates first path Phase Difference of Arrival (PDoA)";
CM_ SG_ 436 StatusUWBRangingFBD_HL_Strongest "strongest path power (Range: -127 ... -1 dB / step: 0.5dB)";
CM_ SG_ 436 StatusUWBRangingFBD_HL_BLE_RSSI "indicates strongest path based on BLE received signal strength indicator";
CM_ SG_ 436 StatusUWBRangingFBD_HL_Stronge_2 "strongest path offset (Range: 0 ... 125ns / step: 0.5ns)";
CM_ SG_ 436 StatusUWBRangingFBD_HL_PDoA_SNR "indicates minimum SNR of the two Rx paths of an FBD indicated at every ranging round";
CM_ SG_ 436 StatusUWBRangingFBD_HL_DutyCycle "indicates duty cycle limit (%), the actual percentage value of frames in relation to the maximum value of 26 frames per second";
CM_ SG_ 436 StatusUWBRangingFBD_HL_FinalData "indicates whether the Final Data is calculated over CAN-FD or received via RF UWB 0 = final data via RF UWB; 1 = final data over CAN-FD; F = no final data";
CM_ SG_ 436 StatusUWBRangingFBD_HL_Antenna "indicates Antenna information (which rx chain is used)";
CM_ SG_ 436 StatusUWBRangingFBD_HL_Status1 "PowerMode and debug information byte1 ToF: time off light FDD: Final data distribution";
CM_ SG_ 436 StatusUWBRangingFBD_HL_Status2 "PowerMode and debug information byte2";
CM_ SG_ 436 StatusUWBRangingFBD_HL_Status3 "PowerMode and debug information byte3";
CM_ SG_ 436 StatusUWBRangingFBD_HL_Status4 "NoisePower and debug information byte4 If Status2=0x00 and Status3=0x0F: Value in Status4 is NoisePower (manual calculation of NoisePower: (value)*0.5-127 [dB]";
CM_ SG_ 436 StatusUWBRangingFBD_HL_IV00 "contains IV";
CM_ SG_ 436 StatusUWBRangingFBD_HL_IV01 "contains IV";
CM_ SG_ 436 StatusUWBRangingFBD_HL_IV02 "contains IV";
CM_ SG_ 436 StatusUWBRangingFBD_HL_IV03 "contains IV";
CM_ SG_ 436 StatusUWBRangingFBD_HL_Sign00 "contains signing to ranging result";
CM_ SG_ 436 StatusUWBRangingFBD_HL_Sign01 "contains signing to ranging result";
CM_ SG_ 436 StatusUWBRangingFBD_HL_Sign02 "contains signing to ranging result";
CM_ SG_ 436 StatusUWBRangingFBD_HL_Sign03 "contains signing to ranging result";
CM_ SG_ 436 StatusUWBRangingFBD_HL_Sign04 "contains signing to ranging result";
CM_ SG_ 436 StatusUWBRangingFBD_HL_Sign05 "contains signing to ranging result";
CM_ SG_ 436 StatusUWBRangingFBD_HL_Sign06 "contains signing to ranging result";
CM_ SG_ 436 StatusUWBRangingFBD_HL_Sign07 "contains signing to ranging result";
CM_ SG_ 431 StatusUWBRangingFBD_HM_SessionID "contains Session-ID";
CM_ SG_ 431 StatusUWBRangingFBD_HM_TimeOfFli "ranging result in ps (PH) = (DEC) * 15.65";
CM_ SG_ 431 StatusUWBRangingFBD_HM_RangingBl "contains Frame Index";
CM_ SG_ 431 StatusUWBRangingFBD_HM_RangingRo "contains Hopping Offset";
CM_ SG_ 431 StatusUWBRangingFBD_HM_OverallRe "overall receive power (Range: -127 ... -1 dB / step: 0.5dB)";
CM_ SG_ 431 StatusUWBRangingFBD_HM_FirstPath "first path power (Range: -127 ... -1 dB / step: 0.5dB)";
CM_ SG_ 431 StatusUWBRangingFBD_HM_AngleOfAr "first path AoA";
CM_ SG_ 431 StatusUWBRangingFBD_HM_PhaseDiff "indicates first path Phase Difference of Arrival (PDoA)";
CM_ SG_ 431 StatusUWBRangingFBD_HM_Strongest "strongest path power (Range: -127 ... -1 dB / step: 0.5dB)";
CM_ SG_ 431 StatusUWBRangingFBD_HM_BLE_RSSI "indicates strongest path based on BLE received signal strength indicator";
CM_ SG_ 431 StatusUWBRangingFBD_HM_Stronge_2 "strongest path offset (Range: 0 ... 125ns / step: 0.5ns)";
CM_ SG_ 431 StatusUWBRangingFBD_HM_PDoA_SNR "indicates minimum SNR of the two Rx paths of an FBD indicated at every ranging round";
CM_ SG_ 431 StatusUWBRangingFBD_HM_DutyCycle "indicates duty cycle limit (%), the actual percentage value of frames in relation to the maximum value of 26 frames per second";
CM_ SG_ 431 StatusUWBRangingFBD_HM_FinalData "indicates whether the Final Data is calculated over CAN-FD or received via RF UWB 0 = final data via RF UWB; 1 = final data over CAN-FD; F = no final data";
CM_ SG_ 431 StatusUWBRangingFBD_HM_Antenna "indicates Antenna information (which rx chain is used)";
CM_ SG_ 431 StatusUWBRangingFBD_HM_Status1 "PowerMode and debug information byte1 ToF: time off light FDD: Final data distribution";
CM_ SG_ 431 StatusUWBRangingFBD_HM_Status2 "PowerMode and debug information byte2";
CM_ SG_ 431 StatusUWBRangingFBD_HM_Status3 "PowerMode and debug information byte3";
CM_ SG_ 431 StatusUWBRangingFBD_HM_Status4 "NoisePower and debug information byte4 If Status2=0x00 and Status3=0x0F: Value in Status4 is NoisePower (manual calculation of NoisePower: (value)*0.5-127 [dB]";
CM_ SG_ 431 StatusUWBRangingFBD_HM_IV00 "contains IV";
CM_ SG_ 431 StatusUWBRangingFBD_HM_IV01 "contains IV";
CM_ SG_ 431 StatusUWBRangingFBD_HM_IV02 "contains IV";
CM_ SG_ 431 StatusUWBRangingFBD_HM_IV03 "contains IV";
CM_ SG_ 431 StatusUWBRangingFBD_HM_Sign00 "contains signing to ranging result";
CM_ SG_ 431 StatusUWBRangingFBD_HM_Sign01 "contains signing to ranging result";
CM_ SG_ 431 StatusUWBRangingFBD_HM_Sign02 "contains signing to ranging result";
CM_ SG_ 431 StatusUWBRangingFBD_HM_Sign03 "contains signing to ranging result";
CM_ SG_ 431 StatusUWBRangingFBD_HM_Sign04 "contains signing to ranging result";
CM_ SG_ 431 StatusUWBRangingFBD_HM_Sign05 "contains signing to ranging result";
CM_ SG_ 431 StatusUWBRangingFBD_HM_Sign06 "contains signing to ranging result";
CM_ SG_ 431 StatusUWBRangingFBD_HM_Sign07 "contains signing to ranging result";
CM_ SG_ 437 StatusUWBRangingFBD_HR_SessionID "contains Session-ID";
CM_ SG_ 437 StatusUWBRangingFBD_HR_TimeOfFli "ranging result in ps (PH) = (DEC) * 15.65";
CM_ SG_ 437 StatusUWBRangingFBD_HR_RangingBl "contains Frame Index";
CM_ SG_ 437 StatusUWBRangingFBD_HR_RangingRo "contains Hopping Offset";
CM_ SG_ 437 StatusUWBRangingFBD_HR_OverallRe "overall receive power (Range: -127 ... -1 dB / step: 0.5dB)";
CM_ SG_ 437 StatusUWBRangingFBD_HR_FirstPath "first path power (Range: -127 ... -1 dB / step: 0.5dB)";
CM_ SG_ 437 StatusUWBRangingFBD_HR_AngleOfAr "first path AoA";
CM_ SG_ 437 StatusUWBRangingFBD_HR_PhaseDiff "indicates first path Phase Difference of Arrival (PDoA)";
CM_ SG_ 437 StatusUWBRangingFBD_HR_Strongest "strongest path power (Range: -127 ... -1 dB / step: 0.5dB)";
CM_ SG_ 437 StatusUWBRangingFBD_HR_BLE_RSSI "indicates strongest path based on BLE received signal strength indicator";
CM_ SG_ 437 StatusUWBRangingFBD_HR_Stronge_2 "strongest path offset (Range: 0 ... 125ns / step: 0.5ns)";
CM_ SG_ 437 StatusUWBRangingFBD_HR_PDoA_SNR "indicates minimum SNR of the two Rx paths of an FBD indicated at every ranging round";
CM_ SG_ 437 StatusUWBRangingFBD_HR_DutyCycle "indicates duty cycle limit (%), the actual percentage value of frames in relation to the maximum value of 26 frames per second";
CM_ SG_ 437 StatusUWBRangingFBD_HR_FinalData "indicates whether the Final Data is calculated over CAN-FD or received via RF UWB 0 = final data via RF UWB; 1 = final data over CAN-FD; F = no final data";
CM_ SG_ 437 StatusUWBRangingFBD_HR_Antenna "indicates Antenna information (which rx chain is used)";
CM_ SG_ 437 StatusUWBRangingFBD_HR_Status1 "PowerMode and debug information byte1 ToF: time off light FDD: Final data distribution";
CM_ SG_ 437 StatusUWBRangingFBD_HR_Status2 "PowerMode and debug information byte2";
CM_ SG_ 437 StatusUWBRangingFBD_HR_Status3 "PowerMode and debug information byte3";
CM_ SG_ 437 StatusUWBRangingFBD_HR_Status4 "NoisePower and debug information byte4 If Status2=0x00 and Status3=0x0F: Value in Status4 is NoisePower (manual calculation of NoisePower: (value)*0.5-127 [dB]";
CM_ SG_ 437 StatusUWBRangingFBD_HR_IV00 "contains IV";
CM_ SG_ 437 StatusUWBRangingFBD_HR_IV01 "contains IV";
CM_ SG_ 437 StatusUWBRangingFBD_HR_IV02 "contains IV";
CM_ SG_ 437 StatusUWBRangingFBD_HR_IV03 "contains IV";
CM_ SG_ 437 StatusUWBRangingFBD_HR_Sign00 "contains signing to ranging result";
CM_ SG_ 437 StatusUWBRangingFBD_HR_Sign01 "contains signing to ranging result";
CM_ SG_ 437 StatusUWBRangingFBD_HR_Sign02 "contains signing to ranging result";
CM_ SG_ 437 StatusUWBRangingFBD_HR_Sign03 "contains signing to ranging result";
CM_ SG_ 437 StatusUWBRangingFBD_HR_Sign04 "contains signing to ranging result";
CM_ SG_ 437 StatusUWBRangingFBD_HR_Sign05 "contains signing to ranging result";
CM_ SG_ 437 StatusUWBRangingFBD_HR_Sign06 "contains signing to ranging result";
CM_ SG_ 437 StatusUWBRangingFBD_HR_Sign07 "contains signing to ranging result";
CM_ SG_ 432 StatusUWBRangingFBD_Miko_Session "contains Session-ID";
CM_ SG_ 432 StatusUWBRangingFBD_Miko_TimeOfF "ranging result in ps (PH) = (DEC) * 15.65";
CM_ SG_ 432 StatusUWBRangingFBD_Miko_Ranging "contains Frame Index";
CM_ SG_ 432 StatusUWBRangingFBD_Miko_Rangi_2 "contains Hopping Offset";
CM_ SG_ 432 StatusUWBRangingFBD_Miko_Overall "overall receive power (Range: -127 ... -1 dB / step: 0.5dB)";
CM_ SG_ 432 StatusUWBRangingFBD_Miko_FirstPa "first path power (Range: -127 ... -1 dB / step: 0.5dB)";
CM_ SG_ 432 StatusUWBRangingFBD_Miko_AngleOf "first path AoA";
CM_ SG_ 432 StatusUWBRangingFBD_Miko_PhaseDi "indicates first path Phase Difference of Arrival (PDoA)";
CM_ SG_ 432 StatusUWBRangingFBD_Miko_Stronge "strongest path power (Range: -127 ... -1 dB / step: 0.5dB)";
CM_ SG_ 432 StatusUWBRangingFBD_Miko_BLE_RSS "indicates strongest path based on BLE received signal strength indicator";
CM_ SG_ 432 StatusUWBRangingFBD_Miko_Stron_2 "strongest path offset (Range: 0 ... 125ns / step: 0.5ns)";
CM_ SG_ 432 StatusUWBRangingFBD_Miko_PDoA_SN "indicates minimum SNR of the two Rx paths of an FBD indicated at every ranging round";
CM_ SG_ 432 StatusUWBRangingFBD_Miko_DutyCyc "indicates duty cycle limit (%), the actual percentage value of frames in relation to the maximum value of 26 frames per second";
CM_ SG_ 432 StatusUWBRangingFBD_Miko_FinalDa "indicates whether the Final Data is calculated over CAN-FD or received via RF UWB 0 = final data via RF UWB; 1 = final data over CAN-FD; F = no final data";
CM_ SG_ 432 StatusUWBRangingFBD_Miko_Antenna "indicates Antenna information (which rx chain is used)";
CM_ SG_ 432 StatusUWBRangingFBD_Miko_Status1 "PowerMode and debug information byte1 ToF: time off light FDD: Final data distribution";
CM_ SG_ 432 StatusUWBRangingFBD_Miko_Status2 "PowerMode and debug information byte2";
CM_ SG_ 432 StatusUWBRangingFBD_Miko_Status3 "PowerMode and debug information byte3";
CM_ SG_ 432 StatusUWBRangingFBD_Miko_Status4 "NoisePower and debug information byte4 If Status2=0x00 and Status3=0x0F: Value in Status4 is NoisePower (manual calculation of NoisePower: (value)*0.5-127 [dB]";
CM_ SG_ 432 StatusUWBRangingFBD_Miko_IV00 "contains IV";
CM_ SG_ 432 StatusUWBRangingFBD_Miko_IV01 "contains IV";
CM_ SG_ 432 StatusUWBRangingFBD_Miko_IV02 "contains IV";
CM_ SG_ 432 StatusUWBRangingFBD_Miko_IV03 "contains IV";
CM_ SG_ 432 StatusUWBRangingFBD_Miko_Sign00 "contains signing to ranging result";
CM_ SG_ 432 StatusUWBRangingFBD_Miko_Sign01 "contains signing to ranging result";
CM_ SG_ 432 StatusUWBRangingFBD_Miko_Sign02 "contains signing to ranging result";
CM_ SG_ 432 StatusUWBRangingFBD_Miko_Sign03 "contains signing to ranging result";
CM_ SG_ 432 StatusUWBRangingFBD_Miko_Sign04 "contains signing to ranging result";
CM_ SG_ 432 StatusUWBRangingFBD_Miko_Sign05 "contains signing to ranging result";
CM_ SG_ 432 StatusUWBRangingFBD_Miko_Sign06 "contains signing to ranging result";
CM_ SG_ 432 StatusUWBRangingFBD_Miko_Sign07 "contains signing to ranging result";
CM_ SG_ 443 StatusUWBRangingFBD_MM_SessionID "contains Session-ID";
CM_ SG_ 443 StatusUWBRangingFBD_MM_TimeOfFli "ranging result in ps (PH) = (DEC) * 15.65";
CM_ SG_ 443 StatusUWBRangingFBD_MM_RangingBl "contains Ranging Block Index";
CM_ SG_ 443 StatusUWBRangingFBD_MM_RangingRo "contains Ranging Round Index (Hopping Offset)";
CM_ SG_ 443 StatusUWBRangingFBD_MM_OverallRe "overall receive power (Range: -127 ... -1 dB / step: 0.5dB)";
CM_ SG_ 443 StatusUWBRangingFBD_MM_FirstPath "first path power (Range: -127 ... -1 dB / step: 0.5dB)";
CM_ SG_ 443 StatusUWBRangingFBD_MM_AngleOfAr "first path AoA";
CM_ SG_ 443 StatusUWBRangingFBD_MM_PhaseDiff "indicates first path Phase Difference of Arrival (PDoA)";
CM_ SG_ 443 StatusUWBRangingFBD_MM_Strongest "strongest path power (Range: -127 ... -1 dB / step: 0.5dB)";
CM_ SG_ 443 StatusUWBRangingFBD_MM_BLE_RSSI "indicates strongest path based on BLE received signal strength indicator";
CM_ SG_ 443 StatusUWBRangingFBD_MM_Stronge_2 "strongest path offset (Range: 0 ... 125ns / step: 0.5ns)";
CM_ SG_ 443 StatusUWBRangingFBD_MM_PDoA_SNR "indicates minimum SNR of the two Rx paths of an FBD indicated at every ranging round";
CM_ SG_ 443 StatusUWBRangingFBD_MM_DutyCycle "indicates duty cycle limit (%), the actual percentage value of frames in relation to the maximum value of 26 frames per second";
CM_ SG_ 443 StatusUWBRangingFBD_MM_FinalData "indicates whether the Final Data is calculated over CAN-FD or received via RF UWB 0 = final data via RF UWB; 1 = final data over CAN-FD; F = no final data";
CM_ SG_ 443 StatusUWBRangingFBD_MM_Antenna "indicates Antenna information (which rx chain is used)";
CM_ SG_ 443 StatusUWBRangingFBD_MM_Status1 "PowerMode and debug information byte1 ToF: time off light FDD: Final data distribution";
CM_ SG_ 443 StatusUWBRangingFBD_MM_Status2 "PowerMode and debug information byte2";
CM_ SG_ 443 StatusUWBRangingFBD_MM_Status3 "PowerMode and debug information byte3";
CM_ SG_ 443 StatusUWBRangingFBD_MM_Status4 "NoisePower and debug information byte4 If Status2=0x00 and Status3=0x0F: Value in Status4 is NoisePower (manual calculation of NoisePower: (value)*0.5-127 [dB]";
CM_ SG_ 443 StatusUWBRangingFBD_MM_IV00 "contains IV to signature";
CM_ SG_ 443 StatusUWBRangingFBD_MM_IV01 "contains IV to signature";
CM_ SG_ 443 StatusUWBRangingFBD_MM_IV02 "contains IV to signature";
CM_ SG_ 443 StatusUWBRangingFBD_MM_IV03 "contains IV to signature";
CM_ SG_ 443 StatusUWBRangingFBD_MM_Sign00 "contains signature";
CM_ SG_ 443 StatusUWBRangingFBD_MM_Sign01 "contains signature";
CM_ SG_ 443 StatusUWBRangingFBD_MM_Sign02 "contains signature";
CM_ SG_ 443 StatusUWBRangingFBD_MM_Sign03 "contains signature";
CM_ SG_ 443 StatusUWBRangingFBD_MM_Sign04 "contains signature";
CM_ SG_ 443 StatusUWBRangingFBD_MM_Sign05 "contains signature";
CM_ SG_ 443 StatusUWBRangingFBD_MM_Sign06 "contains signature";
CM_ SG_ 443 StatusUWBRangingFBD_MM_Sign07 "contains signature";
CM_ SG_ 438 StatusUWBRangingFBD_SML_SessionI "contains Session-ID";
CM_ SG_ 438 StatusUWBRangingFBD_SML_TimeOfFl "ranging result in ps (PH) = (DEC) * 15.65";
CM_ SG_ 438 StatusUWBRangingFBD_SML_RangingB "contains Frame Index";
CM_ SG_ 438 StatusUWBRangingFBD_SML_RangingR "contains Hopping Offset";
CM_ SG_ 438 StatusUWBRangingFBD_SML_OverallR "overall receive power (Range: -127 ... -1 dB / step: 0.5dB)";
CM_ SG_ 438 StatusUWBRangingFBD_SML_FirstPat "first path power (Range: -127 ... -1 dB / step: 0.5dB)";
CM_ SG_ 438 StatusUWBRangingFBD_SML_AngleOfA "first path AoA";
CM_ SG_ 438 StatusUWBRangingFBD_SML_PhaseDif "indicates first path Phase Difference of Arrival (PDoA)";
CM_ SG_ 438 StatusUWBRangingFBD_SML_Stronges "strongest path power (Range: -127 ... -1 dB / step: 0.5dB)";
CM_ SG_ 438 StatusUWBRangingFBD_SML_BLE_RSSI "indicates strongest path based on BLE received signal strength indicator";
CM_ SG_ 438 StatusUWBRangingFBD_SML_Strong_2 "strongest path offset (Range: 0 ... 125ns / step: 0.5ns)";
CM_ SG_ 438 StatusUWBRangingFBD_SML_PDoA_SNR "indicates minimum SNR of the two Rx paths of an FBD indicated at every ranging round";
CM_ SG_ 438 StatusUWBRangingFBD_SML_DutyCycl "indicates duty cycle limit (%), the actual percentage value of frames in relation to the maximum value of 26 frames per second";
CM_ SG_ 438 StatusUWBRangingFBD_SML_FinalDat "indicates whether the Final Data is calculated over CAN-FD or received via RF UWB 0 = final data via RF UWB; 1 = final data over CAN-FD; F = no final data";
CM_ SG_ 438 StatusUWBRangingFBD_SML_Antenna "indicates Antenna information (which rx chain is used)";
CM_ SG_ 438 StatusUWBRangingFBD_SML_Status1 "PowerMode and debug information byte1 ToF: time off light FDD: Final data distribution";
CM_ SG_ 438 StatusUWBRangingFBD_SML_Status2 "PowerMode and debug information byte2";
CM_ SG_ 438 StatusUWBRangingFBD_SML_Status3 "PowerMode and debug information byte3";
CM_ SG_ 438 StatusUWBRangingFBD_SML_Status4 "NoisePower and debug information byte4 If Status2=0x00 and Status3=0x0F: Value in Status4 is NoisePower (manual calculation of NoisePower: (value)*0.5-127 [dB]";
CM_ SG_ 438 StatusUWBRangingFBD_SML_IV00 "contains IV";
CM_ SG_ 438 StatusUWBRangingFBD_SML_IV01 "contains IV";
CM_ SG_ 438 StatusUWBRangingFBD_SML_IV02 "contains IV";
CM_ SG_ 438 StatusUWBRangingFBD_SML_IV03 "contains IV";
CM_ SG_ 438 StatusUWBRangingFBD_SML_Sign00 "contains signing to ranging result";
CM_ SG_ 438 StatusUWBRangingFBD_SML_Sign01 "contains signing to ranging result";
CM_ SG_ 438 StatusUWBRangingFBD_SML_Sign02 "contains signing to ranging result";
CM_ SG_ 438 StatusUWBRangingFBD_SML_Sign03 "contains signing to ranging result";
CM_ SG_ 438 StatusUWBRangingFBD_SML_Sign04 "contains signing to ranging result";
CM_ SG_ 438 StatusUWBRangingFBD_SML_Sign05 "contains signing to ranging result";
CM_ SG_ 438 StatusUWBRangingFBD_SML_Sign06 "contains signing to ranging result";
CM_ SG_ 438 StatusUWBRangingFBD_SML_Sign07 "contains signing to ranging result";
CM_ SG_ 439 StatusUWBRangingFBD_SMR_SessionI "contains Session-ID";
CM_ SG_ 439 StatusUWBRangingFBD_SMR_TimeOfFl "ranging result in ps (PH) = (DEC) * 15.65";
CM_ SG_ 439 StatusUWBRangingFBD_SMR_RangingB "contains Frame Index";
CM_ SG_ 439 StatusUWBRangingFBD_SMR_RangingR "contains Hopping Offset";
CM_ SG_ 439 StatusUWBRangingFBD_SMR_OverallR "overall receive power (Range: -127 ... -1 dB / step: 0.5dB)";
CM_ SG_ 439 StatusUWBRangingFBD_SMR_FirstPat "first path power (Range: -127 ... -1 dB / step: 0.5dB)";
CM_ SG_ 439 StatusUWBRangingFBD_SMR_AngleOfA "first path AoA";
CM_ SG_ 439 StatusUWBRangingFBD_SMR_PhaseDif "indicates first path Phase Difference of Arrival (PDoA)";
CM_ SG_ 439 StatusUWBRangingFBD_SMR_Stronges "strongest path power (Range: -127 ... -1 dB / step: 0.5dB)";
CM_ SG_ 439 StatusUWBRangingFBD_SMR_BLE_RSSI "indicates strongest path based on BLE received signal strength indicator";
CM_ SG_ 439 StatusUWBRangingFBD_SMR_Strong_2 "strongest path offset (Range: 0 ... 125ns / step: 0.5ns)";
CM_ SG_ 439 StatusUWBRangingFBD_SMR_PDoA_SNR "indicates minimum SNR of the two Rx paths of an FBD indicated at every ranging round";
CM_ SG_ 439 StatusUWBRangingFBD_SMR_DutyCycl "indicates duty cycle limit (%), the actual percentage value of frames in relation to the maximum value of 26 frames per second";
CM_ SG_ 439 StatusUWBRangingFBD_SMR_FinalDat "indicates whether the Final Data is calculated over CAN-FD or received via RF UWB 0 = final data via RF UWB; 1 = final data over CAN-FD; F = no final data";
CM_ SG_ 439 StatusUWBRangingFBD_SMR_Antenna "indicates Antenna information (which rx chain is used)";
CM_ SG_ 439 StatusUWBRangingFBD_SMR_Status1 "PowerMode and debug information byte1 ToF: time off light FDD: Final data distribution";
CM_ SG_ 439 StatusUWBRangingFBD_SMR_Status2 "PowerMode and debug information byte2";
CM_ SG_ 439 StatusUWBRangingFBD_SMR_Status3 "PowerMode and debug information byte3";
CM_ SG_ 439 StatusUWBRangingFBD_SMR_Status4 "NoisePower and debug information byte4 If Status2=0x00 and Status3=0x0F: Value in Status4 is NoisePower (manual calculation of NoisePower: (value)*0.5-127 [dB]";
CM_ SG_ 439 StatusUWBRangingFBD_SMR_IV00 "contains IV";
CM_ SG_ 439 StatusUWBRangingFBD_SMR_IV01 "contains IV";
CM_ SG_ 439 StatusUWBRangingFBD_SMR_IV02 "contains IV";
CM_ SG_ 439 StatusUWBRangingFBD_SMR_IV03 "contains IV";
CM_ SG_ 439 StatusUWBRangingFBD_SMR_Sign00 "contains signing to ranging result";
CM_ SG_ 439 StatusUWBRangingFBD_SMR_Sign01 "contains signing to ranging result";
CM_ SG_ 439 StatusUWBRangingFBD_SMR_Sign02 "contains signing to ranging result";
CM_ SG_ 439 StatusUWBRangingFBD_SMR_Sign03 "contains signing to ranging result";
CM_ SG_ 439 StatusUWBRangingFBD_SMR_Sign04 "contains signing to ranging result";
CM_ SG_ 439 StatusUWBRangingFBD_SMR_Sign05 "contains signing to ranging result";
CM_ SG_ 439 StatusUWBRangingFBD_SMR_Sign06 "contains signing to ranging result";
CM_ SG_ 439 StatusUWBRangingFBD_SMR_Sign07 "contains signing to ranging result";
CM_ SG_ 433 StatusUWBRangingFBD_Trunk_Sessio "contains Session-ID";
CM_ SG_ 433 StatusUWBRangingFBD_Trunk_TimeOf "ranging result in ps (PH) = (DEC) * 15.65";
CM_ SG_ 433 StatusUWBRangingFBD_Trunk_Rangin "contains Frame Index";
CM_ SG_ 433 StatusUWBRangingFBD_Trunk_Rang_2 "contains Hopping Offset";
CM_ SG_ 433 StatusUWBRangingFBD_Trunk_Overal "overall receive power (Range: -127 ... -1 dB / step: 0.5dB)";
CM_ SG_ 433 StatusUWBRangingFBD_Trunk_FirstP "first path power (Range: -127 ... -1 dB / step: 0.5dB)";
CM_ SG_ 433 StatusUWBRangingFBD_Trunk_AngleO "first path AoA";
CM_ SG_ 433 StatusUWBRangingFBD_Trunk_PhaseD "indicates first path Phase Difference of Arrival (PDoA)";
CM_ SG_ 433 StatusUWBRangingFBD_Trunk_Strong "strongest path power (Range: -127 ... -1 dB / step: 0.5dB)";
CM_ SG_ 433 StatusUWBRangingFBD_Trunk_BLE_RS "indicates strongest path based on BLE received signal strength indicator";
CM_ SG_ 433 StatusUWBRangingFBD_Trunk_Stro_2 "strongest path offset (Range: 0 ... 125ns / step: 0.5ns)";
CM_ SG_ 433 StatusUWBRangingFBD_Trunk_PDoA_S "indicates minimum SNR of the two Rx paths of an FBD indicated at every ranging round";
CM_ SG_ 433 StatusUWBRangingFBD_Trunk_DutyCy "indicates duty cycle limit (%), the actual percentage value of frames in relation to the maximum value of 26 frames per second";
CM_ SG_ 433 StatusUWBRangingFBD_Trunk_FinalD "indicates whether the Final Data is calculated over CAN-FD or received via RF UWB 0 = final data via RF UWB; 1 = final data over CAN-FD; F = no final data";
CM_ SG_ 433 StatusUWBRangingFBD_Trunk_Antenn "indicates Antenna information (which rx chain is used)";
CM_ SG_ 433 StatusUWBRangingFBD_Trunk_Status "PowerMode and debug information byte1 ToF: time off light FDD: Final data distribution";
CM_ SG_ 433 StatusUWBRangingFBD_Trunk_Stat_2 "PowerMode and debug information byte2";
CM_ SG_ 433 StatusUWBRangingFBD_Trunk_Stat_3 "PowerMode and debug information byte3";
CM_ SG_ 433 StatusUWBRangingFBD_Trunk_Stat_4 "NoisePower and debug information byte4 If Status2=0x00 and Status3=0x0F: Value in Status4 is NoisePower (manual calculation of NoisePower: (value)*0.5-127 [dB]";
CM_ SG_ 433 StatusUWBRangingFBD_Trunk_IV00 "contains IV";
CM_ SG_ 433 StatusUWBRangingFBD_Trunk_IV01 "contains IV";
CM_ SG_ 433 StatusUWBRangingFBD_Trunk_IV02 "contains IV";
CM_ SG_ 433 StatusUWBRangingFBD_Trunk_IV03 "contains IV";
CM_ SG_ 433 StatusUWBRangingFBD_Trunk_Sign00 "contains signing to ranging result";
CM_ SG_ 433 StatusUWBRangingFBD_Trunk_Sign01 "contains signing to ranging result";
CM_ SG_ 433 StatusUWBRangingFBD_Trunk_Sign02 "contains signing to ranging result";
CM_ SG_ 433 StatusUWBRangingFBD_Trunk_Sign03 "contains signing to ranging result";
CM_ SG_ 433 StatusUWBRangingFBD_Trunk_Sign04 "contains signing to ranging result";
CM_ SG_ 433 StatusUWBRangingFBD_Trunk_Sign05 "contains signing to ranging result";
CM_ SG_ 433 StatusUWBRangingFBD_Trunk_Sign06 "contains signing to ranging result";
CM_ SG_ 433 StatusUWBRangingFBD_Trunk_Sign07 "contains signing to ranging result";
CM_ SG_ 434 StatusUWBRangingFBD_VL_SessionID "contains Session-ID";
CM_ SG_ 434 StatusUWBRangingFBD_VL_TimeOfFli "ranging result in ps (PH) = (DEC) * 15.65";
CM_ SG_ 434 StatusUWBRangingFBD_VL_RangingBl "contains Frame Index";
CM_ SG_ 434 StatusUWBRangingFBD_VL_RangingRo "contains Hopping Offset";
CM_ SG_ 434 StatusUWBRangingFBD_VL_OverallRe "overall receive power (Range: -127 ... -1 dB / step: 0.5dB)";
CM_ SG_ 434 StatusUWBRangingFBD_VL_FirstPath "first path power (Range: -127 ... -1 dB / step: 0.5dB)";
CM_ SG_ 434 StatusUWBRangingFBD_VL_AngleOfAr "first path AoA";
CM_ SG_ 434 StatusUWBRangingFBD_VL_PhaseDiff "indicates first path Phase Difference of Arrival (PDoA)";
CM_ SG_ 434 StatusUWBRangingFBD_VL_Strongest "strongest path power (Range: -127 ... -1 dB / step: 0.5dB)";
CM_ SG_ 434 StatusUWBRangingFBD_VL_BLE_RSSI "indicates strongest path based on BLE received signal strength indicator";
CM_ SG_ 434 StatusUWBRangingFBD_VL_Stronge_2 "strongest path offset (Range: 0 ... 125ns / step: 0.5ns)";
CM_ SG_ 434 StatusUWBRangingFBD_VL_PDoA_SNR "indicates minimum SNR of the two Rx paths of an FBD indicated at every ranging round";
CM_ SG_ 434 StatusUWBRangingFBD_VL_DutyCycle "indicates duty cycle limit (%), the actual percentage value of frames in relation to the maximum value of 26 frames per second";
CM_ SG_ 434 StatusUWBRangingFBD_VL_FinalData "indicates whether the Final Data is calculated over CAN-FD or received via RF UWB 0 = final data via RF UWB; 1 = final data over CAN-FD; F = no final data";
CM_ SG_ 434 StatusUWBRangingFBD_VL_Antenna "indicates Antenna information (which rx chain is used)";
CM_ SG_ 434 StatusUWBRangingFBD_VL_Status1 "PowerMode and debug information byte1 ToF: time off light FDD: Final data distribution";
CM_ SG_ 434 StatusUWBRangingFBD_VL_Status2 "PowerMode and debug information byte2";
CM_ SG_ 434 StatusUWBRangingFBD_VL_Status3 "PowerMode and debug information byte3";
CM_ SG_ 434 StatusUWBRangingFBD_VL_Status4 "NoisePower and debug information byte4 If Status2=0x00 and Status3=0x0F: Value in Status4 is NoisePower (manual calculation of NoisePower: (value)*0.5-127 [dB]";
CM_ SG_ 434 StatusUWBRangingFBD_VL_IV00 "contains IV";
CM_ SG_ 434 StatusUWBRangingFBD_VL_IV01 "contains IV";
CM_ SG_ 434 StatusUWBRangingFBD_VL_IV02 "contains IV";
CM_ SG_ 434 StatusUWBRangingFBD_VL_IV03 "contains IV";
CM_ SG_ 434 StatusUWBRangingFBD_VL_Sign00 "contains signing to ranging result";
CM_ SG_ 434 StatusUWBRangingFBD_VL_Sign01 "contains signing to ranging result";
CM_ SG_ 434 StatusUWBRangingFBD_VL_Sign02 "contains signing to ranging result";
CM_ SG_ 434 StatusUWBRangingFBD_VL_Sign03 "contains signing to ranging result";
CM_ SG_ 434 StatusUWBRangingFBD_VL_Sign04 "contains signing to ranging result";
CM_ SG_ 434 StatusUWBRangingFBD_VL_Sign05 "contains signing to ranging result";
CM_ SG_ 434 StatusUWBRangingFBD_VL_Sign06 "contains signing to ranging result";
CM_ SG_ 434 StatusUWBRangingFBD_VL_Sign07 "contains signing to ranging result";
CM_ SG_ 430 StatusUWBRangingFBD_VM_SessionID "contains Session-ID";
CM_ SG_ 430 StatusUWBRangingFBD_VM_TimeOfFli "ranging result in ps (PH) = (DEC) * 15.65";
CM_ SG_ 430 StatusUWBRangingFBD_VM_RangingBl "contains Frame Index";
CM_ SG_ 430 StatusUWBRangingFBD_VM_RangingRo "contains Hopping Offset";
CM_ SG_ 430 StatusUWBRangingFBD_VM_OverallRe "overall receive power (Range: -127 ... -1 dB / step: 0.5dB)";
CM_ SG_ 430 StatusUWBRangingFBD_VM_FirstPath "first path power (Range: -127 ... -1 dB / step: 0.5dB)";
CM_ SG_ 430 StatusUWBRangingFBD_VM_AngleOfAr "first path AoA";
CM_ SG_ 430 StatusUWBRangingFBD_VM_PhaseDiff "indicates first path Phase Difference of Arrival (PDoA)";
CM_ SG_ 430 StatusUWBRangingFBD_VM_Strongest "strongest path power (Range: -127 ... -1 dB / step: 0.5dB)";
CM_ SG_ 430 StatusUWBRangingFBD_VM_BLE_RSSI "indicates strongest path based on BLE received signal strength indicator";
CM_ SG_ 430 StatusUWBRangingFBD_VM_Stronge_2 "strongest path offset (Range: 0 ... 125ns / step: 0.5ns)";
CM_ SG_ 430 StatusUWBRangingFBD_VM_PDoA_SNR "indicates minimum SNR of the two Rx paths of an FBD indicated at every ranging round";
CM_ SG_ 430 StatusUWBRangingFBD_VM_DutyCycle "indicates duty cycle limit (%), the actual percentage value of frames in relation to the maximum value of 26 frames per second";
CM_ SG_ 430 StatusUWBRangingFBD_VM_FinalData "indicates whether the Final Data is calculated over CAN-FD or received via RF UWB 0 = final data via RF UWB; 1 = final data over CAN-FD; F = no final data";
CM_ SG_ 430 StatusUWBRangingFBD_VM_Antenna "indicates Antenna information (which rx chain is used)";
CM_ SG_ 430 StatusUWBRangingFBD_VM_Status1 "PowerMode and debug information byte1 ToF: time off light FDD: Final data distribution";
CM_ SG_ 430 StatusUWBRangingFBD_VM_Status2 "PowerMode and debug information byte2";
CM_ SG_ 430 StatusUWBRangingFBD_VM_Status3 "PowerMode and debug information byte3";
CM_ SG_ 430 StatusUWBRangingFBD_VM_Status4 "NoisePower and debug information byte4 If Status2=0x00 and Status3=0x0F: Value in Status4 is NoisePower (manual calculation of NoisePower: (value)*0.5-127 [dB]";
CM_ SG_ 430 StatusUWBRangingFBD_VM_IV00 "contains IV";
CM_ SG_ 430 StatusUWBRangingFBD_VM_IV01 "contains IV";
CM_ SG_ 430 StatusUWBRangingFBD_VM_IV02 "contains IV";
CM_ SG_ 430 StatusUWBRangingFBD_VM_IV03 "contains IV";
CM_ SG_ 430 StatusUWBRangingFBD_VM_Sign00 "contains signing to ranging result";
CM_ SG_ 430 StatusUWBRangingFBD_VM_Sign01 "contains signing to ranging result";
CM_ SG_ 430 StatusUWBRangingFBD_VM_Sign02 "contains signing to ranging result";
CM_ SG_ 430 StatusUWBRangingFBD_VM_Sign03 "contains signing to ranging result";
CM_ SG_ 430 StatusUWBRangingFBD_VM_Sign04 "contains signing to ranging result";
CM_ SG_ 430 StatusUWBRangingFBD_VM_Sign05 "contains signing to ranging result";
CM_ SG_ 430 StatusUWBRangingFBD_VM_Sign06 "contains signing to ranging result";
CM_ SG_ 430 StatusUWBRangingFBD_VM_Sign07 "contains signing to ranging result";

BA_DEF_ BO_ "VFrameFormat" ENUM "StandardCAN","ExtendedCAN","reserved","J1939PG","reserved","reserved","reserved","reserved","reserved","reserved","reserved","reserved","reserved","reserved","StandardCAN_FD","ExtendedCAN_FD";
BA_DEF_DEF_ "VFrameFormat" "StandardCAN";
BA_ "VFrameFormat" BO_ 646 14;
BA_ "VFrameFormat" BO_ 641 14;
BA_ "VFrameFormat" BO_ 647 14;
BA_ "VFrameFormat" BO_ 642 14;
BA_ "VFrameFormat" BO_ 864 14;
BA_ "VFrameFormat" BO_ 643 14;
BA_ "VFrameFormat" BO_ 644 14;
BA_ "VFrameFormat" BO_ 640 14;
BA_ "VFrameFormat" BO_ 645 14;
BA_ "VFrameFormat" BO_ 156 14;
BA_ "VFrameFormat" BO_ 151 14;
BA_ "VFrameFormat" BO_ 157 14;
BA_ "VFrameFormat" BO_ 152 14;
BA_ "VFrameFormat" BO_ 815 14;
BA_ "VFrameFormat" BO_ 153 14;
BA_ "VFrameFormat" BO_ 154 14;
BA_ "VFrameFormat" BO_ 150 14;
BA_ "VFrameFormat" BO_ 155 14;
BA_ "VFrameFormat" BO_ 426 14;
BA_ "VFrameFormat" BO_ 421 14;
BA_ "VFrameFormat" BO_ 427 14;
BA_ "VFrameFormat" BO_ 422 14;
BA_ "VFrameFormat" BO_ 440 14;
BA_ "VFrameFormat" BO_ 423 14;
BA_ "VFrameFormat" BO_ 424 14;
BA_ "VFrameFormat" BO_ 420 14;
BA_ "VFrameFormat" BO_ 425 14;
BA_ "VFrameFormat" BO_ 476 14;
BA_ "VFrameFormat" BO_ 471 14;
BA_ "VFrameFormat" BO_ 477 14;
BA_ "VFrameFormat" BO_ 472 14;
BA_ "VFrameFormat" BO_ 441 14;
BA_ "VFrameFormat" BO_ 473 14;
BA_ "VFrameFormat" BO_ 474 14;
BA_ "VFrameFormat" BO_ 470 14;
BA_ "VFrameFormat" BO_ 475 14;
BA_ "VFrameFormat" BO_ 436 14;
BA_ "VFrameFormat" BO_ 431 14;
BA_ "VFrameFormat" BO_ 437 14;
BA_ "VFrameFormat" BO_ 432 14;
BA_ "VFrameFormat" BO_ 443 14;
BA_ "VFrameFormat" BO_ 438 14;
BA_ "VFrameFormat" BO_ 439 14;
BA_ "VFrameFormat" BO_ 433 14;
BA_ "VFrameFormat" BO_ 434 14;
BA_ "VFrameFormat" BO_ 430 14;
